VERSION "HNNBNNNYNNNNNNNNNNNNNNNNNNNNNNNNNNNNNNNNNN/4/%%%/4/'%**4NNN///"

NS_ :

BS_:

BU_: Airbag BAP_Tester ICAS1_Gateway ICAS1_KommunikationsServer LE1 LE2 Motor_BEV Schaltbetaetigung

BO_ 958 Motor_14: 8 Motor_BEV
 SG_ Motor_14_CRC : 0|8@1+ (1,0) [0|255] ""  ICAS1_Gateway
 SG_ Motor_14_BZ : 8|4@1+ (1,0) [0|15] ""  ICAS1_Gateway
 SG_ MO_StartStopp_Status : 12|2@1+ (1.0,0.0) [0.0|3] ""  ICAS1_Gateway
 SG_ MO_StartStopp_Wiederstart : 14|1@1+ (1.0,0.0) [0.0|1] ""  ICAS1_Gateway
 SG_ MO_StartStopp_Motorstopp : 15|1@1+ (1.0,0.0) [0.0|1] ""  ICAS1_Gateway
 SG_ MO_Freig_Reku : 16|2@1+ (1.0,0.0) [0.0|3] ""  ICAS1_Gateway
 SG_ MO_Kl_75 : 18|1@1+ (1.0,0.0) [0.0|1] ""  ICAS1_Gateway
 SG_ MO_Kl_50 : 19|1@1+ (1.0,0.0) [0.0|1] ""  ICAS1_Gateway
 SG_ MO_Gangposition : 20|4@1+ (1.0,0.0) [0.0|15] ""  ICAS1_Gateway
 SG_ MO_StartStopp_Fahrerwunsch : 24|2@1+ (1.0,0.0) [0.0|3] ""  ICAS1_Gateway
 SG_ MO_HYB_Fahrbereitschaft : 26|1@1+ (1.0,0.0) [0.0|1] ""  ICAS1_Gateway
 SG_ MO_Ext_E_Fahrt_aktiv : 27|1@1+ (1.0,0.0) [0.0|1] ""  ICAS1_Gateway
 SG_ MO_Fahrer_bremst : 28|1@1+ (1.0,0.0) [0.0|1] ""  Airbag,ICAS1_Gateway
 SG_ MO_QBit_Fahrer_bremst : 29|1@1+ (1.0,0.0) [0.0|1] ""  Airbag,ICAS1_Gateway
 SG_ MO_BLS : 30|1@1+ (1.0,0.0) [0.0|1] ""  Airbag,ICAS1_Gateway
 SG_ MO_Konsistenz_Bremsped : 31|1@1+ (1.0,0.0) [0.0|1] ""  ICAS1_Gateway
 SG_ MO_Timeout_ESP : 32|1@1+ (1.0,0.0) [0.0|1] ""  ICAS1_Gateway
 SG_ MO_Klima_Eingr : 33|2@1+ (1.0,0.0) [0.0|3] ""  ICAS1_Gateway
 SG_ MO_Aussp_Anlass : 35|1@1+ (1.0,0.0) [0.0|1] ""  ICAS1_Gateway
 SG_ MO_Freig_Anlass : 36|1@1+ (1.0,0.0) [0.0|1] ""  ICAS1_Gateway
 SG_ MO_Kuppl_schalter : 37|1@1+ (1.0,0.0) [0.0|1] ""  ICAS1_Gateway
 SG_ MO_Interlock : 38|1@1+ (1.0,0.0) [0.0|1] ""  ICAS1_Gateway
 SG_ MO_Motor_laeuft : 39|1@1+ (1.0,0.0) [0.0|1] ""  ICAS1_Gateway
 SG_ MO_Kickdown : 40|1@1+ (1.0,0.0) [0.0|1] ""  ICAS1_Gateway,ICAS1_KommunikationsServer
 SG_ MO_QBit_KL_75 : 41|1@1+ (1.0,0.0) [0.0|1] ""  ICAS1_Gateway
 SG_ MO_EKlKomLeiRed : 42|2@1+ (1.0,0.0) [0.0|3] ""  ICAS1_Gateway
 SG_ MO_Handshake_STH : 44|1@1+ (1.0,0.0) [0.0|1] ""  ICAS1_Gateway
 SG_ MO_BKV_Unterdruckwarnung : 45|1@1+ (1.0,0.0) [0.0|1] ""  ICAS1_Gateway
 SG_ MO_Freigabe_Segeln : 46|1@1+ (1.0,0.0) [0.0|1] ""  ICAS1_Gateway
 SG_ MO_PTC_Status : 47|3@1+ (1.0,0.0) [0.0|7] ""  ICAS1_Gateway
 SG_ MO_QBit_Gangposition : 50|1@1+ (1.0,0.0) [0.0|1] ""  ICAS1_Gateway
 SG_ MO_Signalquelle_Gangposition : 51|1@1+ (1.0,0.0) [0.0|1] ""  ICAS1_Gateway
 SG_ MO_Remotestart_Betrieb : 52|1@1+ (1.0,0.0) [0.0|1] ""  ICAS1_Gateway
 SG_ MO_Remotestart_moeglich : 53|1@1+ (1.0,0.0) [0.0|1] ""  ICAS1_Gateway
 SG_ MO_FMAus_aktiv : 55|1@1+ (1.0,0.0) [0.0|1] ""  ICAS1_Gateway
 SG_ MO_FMAus_Startvariante : 56|2@1+ (1.0,0.0) [0.0|3] ""  ICAS1_Gateway
 SG_ MO_BMS_NV_Anf_stuetzen : 58|1@1+ (1.0,0.0) [0.0|1] ""  ICAS1_Gateway
 SG_ MO_Zylinderabschaltung : 59|2@1+ (1.0,0.0) [0.0|3] ""  ICAS1_Gateway
 SG_ MO_HYB_VM_aktiv : 61|1@1+ (1.0,0.0) [0.0|1] ""  ICAS1_Gateway
 SG_ MO_StartVorauss_erfuellt : 62|2@1+ (1.0,0.0) [0.0|3] ""  ICAS1_Gateway

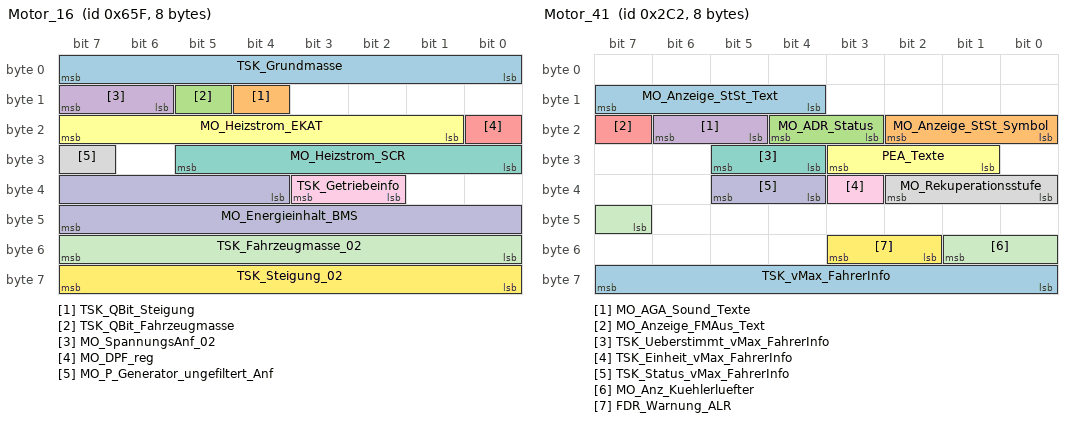
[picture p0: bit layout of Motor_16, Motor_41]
BO_ 1631 Motor_16: 8 Motor_BEV
 SG_ TSK_Grundmasse : 0|8@1+ (32,0) [0|8128] "Unit_KiloGram"  ICAS1_Gateway
 SG_ TSK_QBit_Steigung : 12|1@1+ (1.0,0.0) [0.0|1] ""  ICAS1_Gateway
 SG_ TSK_QBit_Fahrzeugmasse : 13|1@1+ (1.0,0.0) [0.0|1] ""  ICAS1_Gateway
 SG_ MO_SpannungsAnf_02 : 14|2@1+ (1.0,0.0) [0.0|3] ""  ICAS1_Gateway
 SG_ MO_DPF_reg : 16|1@1+ (1.0,0.0) [0.0|1] ""  ICAS1_Gateway
 SG_ MO_Heizstrom_EKAT : 17|7@1+ (1,0) [0|126] "Unit_Amper"  ICAS1_Gateway
 SG_ MO_Heizstrom_SCR : 24|6@1+ (1,0) [0|62] "Unit_Amper"  ICAS1_Gateway
 SG_ MO_P_Generator_ungefiltert_Anf : 31|1@1+ (1.0,0.0) [0.0|1] ""  ICAS1_Gateway
 SG_ TSK_Getriebeinfo : 34|2@1+ (1.0,0.0) [0.0|3] ""  ICAS1_Gateway
 SG_ MO_Energieinhalt_BMS : 36|12@1+ (25,0) [0|102325] "Unit_WattHour"  ICAS1_Gateway
 SG_ TSK_Fahrzeugmasse_02 : 48|8@1+ (32,0) [0|8128] "Unit_KiloGram"  ICAS1_Gateway
 SG_ TSK_Steigung_02 : 56|8@1+ (0.8,-101.6) [-100.8|101.6] "Unit_PerCent"  ICAS1_Gateway

BO_ 1648 Motor_18: 8 Motor_BEV
 SG_ MO_max_Ladedruck : 0|6@1+ (0.1,0) [0.0|6.3] "Unit_Bar"  ICAS1_Gateway
 SG_ MO_ANC_Kennfeld_Anf : 6|2@1+ (1.0,0.0) [0.0|3] ""  ICAS1_Gateway
 SG_ MO_Bremslicht_Reku : 8|1@1+ (1.0,0.0) [0.0|1] ""  ICAS1_Gateway
 SG_ MO_StartStopp_PopUp : 9|2@1+ (1.0,0.0) [0.0|3] ""  ICAS1_Gateway
 SG_ MO1_Sperr_Info_WFS : 11|1@1+ (1.0,0.0) [0.0|1] ""  ICAS1_Gateway
 SG_ MO1_Freigabe_Info_WFS : 12|1@1+ (1.0,0.0) [0.0|1] ""  ICAS1_Gateway
 SG_ MO_EPCL : 13|3@1+ (1.0,0.0) [0.0|7] ""  ICAS1_Gateway,ICAS1_KommunikationsServer
 SG_ MO_Zylabsch_Texte_02 : 16|4@1+ (1.0,0.0) [0.0|15] ""  ICAS1_Gateway
 SG_ MO_Fahrzeugtyp : 20|3@1+ (1.0,0.0) [0.0|7] ""  ICAS1_Gateway,ICAS1_KommunikationsServer
 SG_ MO_NMAX_Schaltanzeige : 23|9@1+ (25,0) [0|12775] "Unit_MinutInver"  ICAS1_Gateway
 SG_ MO_Abstellzeit : 32|8@1+ (8,0) [0|2024] "Unit_Minut"  ICAS1_Gateway
 SG_ MO_Abstellzeit_Status : 40|2@1+ (1.0,0.0) [0.0|3] ""  ICAS1_Gateway
 SG_ MO1_Freigabe_Verfallsinfo_WFS : 42|1@1+ (1.0,0.0) [0.0|1] ""  ICAS1_Gateway
 SG_ MO_Hybrid_StartStopp_LED : 43|2@1+ (1.0,0.0) [0.0|3] ""  ICAS1_Gateway
 SG_ MO_Fehler_Zylabsch : 45|2@1+ (1.0,0.0) [0.0|3] ""  ICAS1_Gateway
 SG_ MO_Anzahl_Abgesch_Zyl : 47|3@1+ (1.0,0.0) [0.0|7] ""  ICAS1_Gateway
 SG_ MO_Zylabsch_Texte : 50|2@1+ (1.0,0.0) [0.0|3] ""  ICAS1_Gateway
 SG_ MO_Ethanol_BS_Texte : 52|3@1+ (1.0,0.0) [0.0|7] ""  ICAS1_Gateway
 SG_ MO_Drehzahl_Warnung : 55|1@1+ (1.0,0.0) [0.0|1] ""  ICAS1_Gateway
 SG_ MO_obere_Drehzahlgrenze : 56|8@1+ (50,0) [50|12750] "Unit_MinutInver"  ICAS1_Gateway

BO_ 967 Motor_26: 8 Motor_BEV
 SG_ MO_Kuehlerluefter_MUX M  : 0|1@1+ (1.0,0.0) [0.0|1] "siema ooo"  ICAS1_Gateway
 SG_ MO_Kuehlerluefter_1 m0  : 1|7@1+ (1,0) [0|100] "Unit_PerCent"  ICAS1_Gateway
 SG_ MO_Kuehlerluefter_2 m1  : 1|7@1+ (1,0) [0|100] "Unit_PerCent"  ICAS1_Gateway
 SG_ MO_EFLEX_Lampe : 8|2@1+ (1.0,0.0) [0.0|3] ""  ICAS1_Gateway
 SG_ MO_KJS_nicht_bereit : 10|1@1+ (1.0,0.0) [0.0|1] ""  ICAS1_Gateway
 SG_ MO_ITM_Warnung_Pumpe : 11|1@1+ (1.0,0.0) [0.0|1] ""  ICAS1_Gateway
 SG_ WIV_Anzeige_aktiv : 12|1@1+ (1.0,0.0) [0.0|1] ""  ICAS1_Gateway
 SG_ WIV_Oelmin_Warn : 13|1@1+ (1.0,0.0) [0.0|1] ""  ICAS1_Gateway
 SG_ WIV_Sensorfehler : 14|1@1+ (1.0,0.0) [0.0|1] ""  ICAS1_Gateway
 SG_ WIV_Schieflage : 15|1@1+ (1.0,0.0) [0.0|1] ""  ICAS1_Gateway
 SG_ WIV_Oelstand : 16|4@1+ (12.5,0) [0.0|100.0] "Unit_PerCent"  ICAS1_Gateway
 SG_ MO_Zustand_HWP : 20|2@1+ (1.0,0.0) [0.0|3] ""  ICAS1_Gateway
 SG_ OLEV_Systemstoerung : 22|1@1+ (1.0,0.0) [0.0|1] ""  ICAS1_Gateway
 SG_ MO_Oelwarnung_max : 23|1@1+ (1.0,0.0) [0.0|1] ""  ICAS1_Gateway
 SG_ WIV_Oelsystem_aktiv : 24|1@1+ (1.0,0.0) [0.0|1] ""  ICAS1_Gateway
 SG_ WIV_nicht_betriebswarm : 25|1@1+ (1.0,0.0) [0.0|1] ""  ICAS1_Gateway
 SG_ WIV_Ueberfuell_Warn : 26|1@1+ (1.0,0.0) [0.0|1] ""  ICAS1_Gateway
 SG_ WIV_laufender_Motor : 27|1@1+ (1.0,0.0) [0.0|1] ""  ICAS1_Gateway
 SG_ MO_E_Warnungen : 28|4@1+ (1.0,0.0) [0.0|15] ""  ICAS1_Gateway
 SG_ MO_Text_Motorstart : 32|4@1+ (1.0,0.0) [0.0|15] ""  ICAS1_Gateway
 SG_ MO_E_Texte : 36|4@1+ (1.0,0.0) [0.0|15] ""  ICAS1_Gateway
 SG_ WIV_Oeldyn_avl : 40|1@1+ (1.0,0.0) [0.0|1] ""  ICAS1_Gateway
 SG_ MO_Text_Partikelfil_Reg : 41|1@1+ (1,0) [0|1] ""  ICAS1_Gateway
 SG_ OLEV_Oelstand_nicht_vorhanden : 42|1@1+ (1.0,0.0) [0.0|1] ""  ICAS1_Gateway
 SG_ WIV_Oelmenge : 43|5@1+ (125,0) [0|3875] "Unit_MilliLiter"  ICAS1_Gateway
 SG_ MO_Systemlampe : 48|1@1+ (1.0,0.0) [0.0|1] ""  ICAS1_Gateway
 SG_ MO_OBD2_Lampe : 49|1@1+ (1.0,0.0) [0.0|1] ""  ICAS1_Gateway
 SG_ MO_Heissleuchte : 50|1@1+ (1.0,0.0) [0.0|1] ""  ICAS1_Gateway
 SG_ MO_Partikel_Lampe : 51|1@1+ (1.0,0.0) [0.0|1] ""  ICAS1_Gateway
 SG_ MO_RedFahrleistung_Lampe : 52|1@1+ (1.0,0.0) [0.0|1] ""  ICAS1_Gateway,ICAS1_KommunikationsServer
 SG_ WIV_Oelstand_nicht_vorhanden : 53|1@1+ (1.0,0.0) [0.0|1] ""  ICAS1_Gateway
 SG_ WIV_nachfuellanzeige_ein : 54|1@1+ (1.0,0.0) [0.0|1] ""  ICAS1_Gateway
 SG_ WIV_Ueberfuell_deaktiv : 55|1@1+ (1.0,0.0) [0.0|1] ""  ICAS1_Gateway
 SG_ WIV_Unterfuell_Warn : 56|1@1+ (1.0,0.0) [0.0|1] ""  ICAS1_Gateway
 SG_ MO_Tankdeckel_Lampe : 57|1@1+ (1.0,0.0) [0.0|1] ""  ICAS1_Gateway
 SG_ MO_Text_Tankdeckelwarn : 58|1@1+ (1.0,0.0) [0.0|1] ""  ICAS1_Gateway
 SG_ MO_Vorglueh_Lampe : 59|1@1+ (1.0,0.0) [0.0|1] ""  ICAS1_Gateway
 SG_ WIV_Oeldr_Warn_Motor : 60|1@1+ (1.0,0.0) [0.0|1] ""  ICAS1_Gateway
 SG_ MO_E_Mode : 61|3@1+ (1.0,0.0) [0.0|7] ""  ICAS1_Gateway

BO_ 706 Motor_41: 8 Motor_BEV
 SG_ MO_Anzeige_StSt_Text : 12|4@1+ (1.0,0.0) [0.0|15] ""  Vector__XXX
 SG_ MO_Anzeige_StSt_Symbol : 16|3@1+ (1.0,0.0) [0.0|7] ""  Vector__XXX
 SG_ MO_ADR_Status : 19|2@1+ (1.0,0.0) [0.0|3] ""  Vector__XXX
 SG_ MO_AGA_Sound_Texte : 21|2@1+ (1.0,0.0) [0.0|3] ""  Vector__XXX
 SG_ MO_Anzeige_FMAus_Text : 23|1@1+ (1.0,0.0) [0.0|1] ""  Vector__XXX
 SG_ PEA_Texte : 25|3@1+ (1.0,0.0) [0.0|7] ""  Vector__XXX
 SG_ TSK_Ueberstimmt_vMax_FahrerInfo : 28|2@1+ (1.0,0.0) [0.0|3] ""  Vector__XXX
 SG_ MO_Rekuperationsstufe : 32|3@1+ (1.0,0.0) [0.0|7] ""  ICAS1_KommunikationsServer
 SG_ TSK_Einheit_vMax_FahrerInfo : 35|1@1+ (1.0,0.0) [0.0|1] ""  ICAS1_KommunikationsServer
 SG_ TSK_Status_vMax_FahrerInfo : 36|2@1+ (1.0,0.0) [0.0|3] ""  ICAS1_KommunikationsServer
 SG_ MO_Anz_Kuehlerluefter : 47|3@1+ (1.0,0.0) [0.0|7] ""  Vector__XXX
 SG_ FDR_Warnung_ALR : 50|2@1+ (1.0,0.0) [0.0|3] ""  ICAS1_KommunikationsServer
 SG_ TSK_vMax_FahrerInfo : 56|8@1+ (1,15) [16|270] ""  ICAS1_KommunikationsServer

BO_ 267 Motor_51: 32 Motor_BEV
 SG_ Motor_51_CRC : 0|8@1+ (1,0) [0|255] ""  ICAS1_Gateway
 SG_ Motor_51_BZ : 8|4@1+ (1,0) [0|15] ""  ICAS1_Gateway
 SG_ MO_Fahrpedalrohwert_01 : 12|8@1+ (0.4,0) [0.0|101.6] "Unit_PerCent"  Airbag,ICAS1_Gateway
 SG_ MO_QBit_Fahrpedalwerte_01 : 20|1@1+ (1.0,0.0) [0.0|1] ""  Airbag,ICAS1_Gateway
 SG_ MO_Fahrpedalgradient : 21|8@1+ (25,0) [0|6350] "Unit_PerCentPerSecon"  ICAS1_Gateway
 SG_ MO_Sig_Fahrpedalgradient : 29|1@1+ (1.0,0.0) [0.0|1] ""  ICAS1_Gateway
 SG_ MO_rel_Saugrohrdruck : 30|6@1+ (18,0) [0|1116] "Unit_MilliBar"  ICAS1_Gateway
 SG_ MO_rel_Saugrohrdruck_gem_err : 36|1@1+ (1.0,0.0) [0.0|1] ""  ICAS1_Gateway
 SG_ MO_Moment_im_Leerlauf : 37|1@1+ (1.0,0.0) [0.0|1] ""  ICAS1_Gateway
 SG_ MO_Schubabschaltung : 38|1@1+ (1.0,0.0) [0.0|1] ""  ICAS1_Gateway
 SG_ MO_Solldrehz_Leerlauf : 40|8@1+ (10,0) [0|2540] "Unit_MinutInver"  ICAS1_Gateway
 SG_ MO_Entkopplung_Sollschlupf : 48|7@1+ (20,0) [0|2480] "Unit_MinutInver"  ICAS1_Gateway
 SG_ MO_temporaere_Fahrerabwesenheit : 55|1@1+ (1.0,0.0) [0.0|1] ""  ICAS1_Gateway
 SG_ TSK_a_Soll_gradientenbegrenzt : 57|7@1+ (0.1,-7.2) [-7.2|5.4] "Unit_MeterPerSeconSquar"  ICAS1_Gateway
 SG_ TSK_Radbremsmom : 76|12@1+ (8,0) [0|32760] "Unit_NewtoMeter"  ICAS1_Gateway
 SG_ TSK_Status : 88|3@1+ (1.0,0.0) [0.0|7] ""  ICAS1_Gateway
 SG_ TSK_v_Begrenzung_aktiv : 91|1@1+ (1.0,0.0) [0.0|1] ""  ICAS1_Gateway
 SG_ TSK_Standby_Anf_ESP : 92|1@1+ (1.0,0.0) [0.0|1] ""  ICAS1_Gateway
 SG_ TSK_Freig_WU : 93|1@1+ (1.0,0.0) [0.0|1] ""  ICAS1_Gateway
 SG_ TSK_Freig_Verzoeg_Anf : 94|1@1+ (1.0,0.0) [0.0|1] ""  ICAS1_Gateway
 SG_ TSK_Limiter_ausgewaehlt : 95|1@1+ (1.0,0.0) [0.0|1] ""  ICAS1_Gateway
 SG_ TSK_Wunsch_Uebersetz : 96|10@1+ (0.0245,0) [0.0245|25.0635] ""  ICAS1_Gateway
 SG_ TSK_Hauptschalter_GRA_ACC : 106|2@1+ (1.0,0.0) [0.0|3] ""  ICAS1_Gateway,ICAS1_KommunikationsServer
 SG_ TSK_SRBM_Anf_ASIL : 108|3@1+ (1.0,0.0) [0.0|7] ""  ICAS1_Gateway
 SG_ TSK_ax_Getriebe_02 : 112|9@1+ (0.024,-2.016) [-2.016|10.224] "Unit_MeterPerSeconSquar"  ICAS1_Gateway
 SG_ TSK_Zwangszusch_ESP : 121|1@1+ (1.0,0.0) [0.0|1] ""  ICAS1_Gateway
 SG_ TSK_zul_Regelabw : 122|6@1+ (0.024,0) [0.000|1.512] "Unit_MeterPerSeconSquar"  ICAS1_Gateway
 SG_ MO_Status_MinDrzEingriff : 235|3@1+ (1.0,0.0) [0.0|7] ""  ICAS1_Gateway
 SG_ MO_Status_MaxDrzEingriff : 238|3@1+ (1.0,0.0) [0.0|7] ""  ICAS1_Gateway
 SG_ MO_Status_MinDrzEingriff_sek : 241|3@1+ (1.0,0.0) [0.0|7] ""  ICAS1_Gateway
 SG_ MO_Status_MaxDrzEingriff_sek : 244|3@1+ (1.0,0.0) [0.0|7] ""  ICAS1_Gateway
 SG_ GRA_KuFu_aktiv : 247|1@1+ (1.0,0.0) [0.0|1] ""  ICAS1_Gateway
 SG_ TSK_SRBM_max_Gradient : 248|7@1+ (50,0) [0|6250] "Unit_NewtoMeterPerSecon"  ICAS1_Gateway
 SG_ LIM_KuFu_aktiv : 255|1@1+ (1.0,0.0) [0.0|1] ""  ICAS1_Gateway

BO_ 330 Motor_52: 32 Motor_BEV
 SG_ MO_Hochschaltdrehz : 21|12@1+ (3,0) [3|12282] "Unit_MinutInver"  Vector__XXX
 SG_ MO_Anzeige_Verbr_Einheit : 33|2@1+ (1.0,0.0) [0.0|3] ""  Vector__XXX
 SG_ MO_Schaltblitz_Anz : 35|7@1+ (1,0) [0|100] "Unit_PerCent"  Vector__XXX
 SG_ MO_Anzeige_Drehmoment : 42|11@1+ (1,0) [0|2045] "Unit_NewtoMeter"  Vector__XXX
 SG_ MO_Anzeige_Leistung : 53|11@1+ (0.6,0) [0.0|1227.0] "Unit_KiloWatt"  Vector__XXX
 SG_ MO_rel_Ladedruck : 64|8@1+ (0.4,0) [0.0|100.0] "Unit_PerCent"  Vector__XXX
 SG_ MO_Istgang : 72|4@1+ (1.0,0.0) [0.0|15] ""  Vector__XXX
 SG_ MO_Sollgang : 76|4@1+ (1.0,0.0) [0.0|15] ""  Vector__XXX
 SG_ MO_Oeldruck : 80|8@1+ (0.04,0) [0.00|10.00] "Unit_Bar"  Vector__XXX
 SG_ MO_Anzeigedrehz : 88|12@1+ (3,0) [0|12282] "Unit_MinutInver"  Vector__XXX
 SG_ MO_Effizienzmodus : 100|1@1+ (1.0,0.0) [0.0|1] ""  Vector__XXX
 SG_ MO_Fehler_Oeldrucksensor : 101|1@1+ (1.0,0.0) [0.0|1] ""  Vector__XXX
 SG_ MO_Schaltempf_verfbar : 102|1@1+ (1.0,0.0) [0.0|1] ""  Vector__XXX
 SG_ MO_Ladedruck : 103|9@1+ (0.01,0) [0.00|5.10] "Unit_Bar"  Vector__XXX
 SG_ MO_KVS : 112|15@1+ (1,0) [0|32767] "Unit_MicroLiter"  Vector__XXX
 SG_ MO_KVS_Ueberlauf : 127|1@1+ (1.0,0.0) [0.0|1] ""  Vector__XXX
 SG_ MO_ePowermeter : 128|8@1+ (0.4,-0.4) [0.0|100.8] "Unit_PerCent"  Vector__XXX
 SG_ MO_ePerformance : 136|8@1+ (0.4,-0.4) [0.0|100.8] "Unit_PerCent"  ICAS1_KommunikationsServer
 SG_ MO_Zust_Antrieb : 144|4@1+ (1.0,0.0) [0.0|15] ""  Vector__XXX
 SG_ MO_Zust_Betriebsstrategie : 148|3@1+ (1.0,0.0) [0.0|7] ""  Vector__XXX
 SG_ Ladezustand_02 : 152|8@1+ (0.5,0) [0.0|100.0] "Unit_PerCent"  ICAS1_Gateway,ICAS1_KommunikationsServer
 SG_ MO_Powermeter_Elm_02 : 168|12@1+ (0.05,-102.4) [-100.00|100.00] "Unit_PerCent"  Vector__XXX
 SG_ MO_Powermeter : 180|12@1+ (1,0) [0|4092] ""  ICAS1_KommunikationsServer

BO_ 512 Motor_53: 32 Motor_BEV
 SG_ TSK_Wunschgeschw : 12|10@1+ (0.32,0) [0.00|326.72] "Unit_KiloMeterPerHour"  ICAS1_Gateway,ICAS1_KommunikationsServer
 SG_ TSK_praediktiver_Hinweis : 22|3@1+ (1.0,0.0) [0.0|7] ""  ICAS1_Gateway
 SG_ TSK_naechstes_Event : 25|6@1+ (1.0,0.0) [0.0|63] ""  ICAS1_Gateway
 SG_ TSK_Fahrzeugstatus_praed_Fkt : 31|3@1+ (1.0,0.0) [0.0|7] ""  ICAS1_Gateway
 SG_ TSK_Texte : 40|5@1+ (1.0,0.0) [0.0|31] ""  ICAS1_Gateway,ICAS1_KommunikationsServer
 SG_ TSK_Akustik : 45|3@1+ (1.0,0.0) [0.0|7] ""  ICAS1_Gateway,ICAS1_KommunikationsServer
 SG_ TSK_Texte_Primaeranz : 48|5@1+ (1.0,0.0) [0.0|31] ""  ICAS1_Gateway,ICAS1_KommunikationsServer
 SG_ TSK_Limiter_Fahrerinfo : 53|2@1+ (1.0,0.0) [0.0|3] ""  ICAS1_Gateway,ICAS1_KommunikationsServer
 SG_ TSK_Limiter_Anzeige : 55|1@1+ (1.0,0.0) [0.0|1] ""  ICAS1_Gateway,ICAS1_KommunikationsServer
 SG_ TSK_Fahrzeugstatus_GRA : 56|1@1+ (1.0,0.0) [0.0|1] ""  ICAS1_Gateway,ICAS1_KommunikationsServer
 SG_ TSK_Fahrzeugstatus_Limiter : 57|1@1+ (1.0,0.0) [0.0|1] ""  ICAS1_Gateway,ICAS1_KommunikationsServer
 SG_ MO_Motorlaufwarnung : 58|1@1+ (1.0,0.0) [0.0|1] ""  ICAS1_Gateway
 SG_ TSK_naechstes_Event_Einheit : 60|1@1+ (1.0,0.0) [0.0|1] ""  ICAS1_Gateway
 SG_ TSK_Status_Anzeige : 61|3@1+ (1.0,0.0) [0.0|7] ""  ICAS1_Gateway,ICAS1_KommunikationsServer
 SG_ MO_Sperrung_FahrPr_BZS : 64|8@1+ (1.0,0.0) [0.0|255] ""  ICAS1_Gateway
 SG_ MO_Rampenzeit_Generator_Anf : 72|4@1+ (1.0,0.0) [0.0|15] ""  ICAS1_Gateway
 SG_ MO_Prio_MAX_Wunschdrehzahl : 76|1@1+ (1.0,0.0) [0.0|1] ""  ICAS1_Gateway
 SG_ MO_Prio_MIN_Wunschdrehzahl : 77|1@1+ (1.0,0.0) [0.0|1] ""  ICAS1_Gateway
 SG_ MO_Luftpfad_aktiv : 78|1@1+ (1.0,0.0) [0.0|1] ""  ICAS1_Gateway
 SG_ MO_v_Begrenz_Aktivierbar : 79|1@1+ (1.0,0.0) [0.0|1] ""  ICAS1_Gateway
 SG_ MO_Drehzahlbeeinflussung : 80|8@1+ (0.39,0) [0.00|99.45] "Unit_PerCent"  ICAS1_Gateway
 SG_ MO_MIN_Wunschdrehzahl : 88|8@1+ (25,0) [0|6350] "Unit_MinutInver"  ICAS1_Gateway
 SG_ MO_MAX_Wunschdrehzahl : 96|9@1+ (25,0) [0|12750] "Unit_MinutInver"  ICAS1_Gateway
 SG_ MO_Charisma_FahrPr : 105|4@1+ (1.0,0.0) [0.0|15] ""  ICAS1_Gateway
 SG_ MO_Charisma_Status : 109|2@1+ (1.0,0.0) [0.0|3] ""  ICAS1_Gateway
 SG_ MO_StSt_Charisma_FahrPr : 111|4@1+ (1.0,0.0) [0.0|15] ""  ICAS1_Gateway
 SG_ MO_StSt_Charisma_Status : 115|2@1+ (1.0,0.0) [0.0|3] ""  ICAS1_Gateway
 SG_ MO_BZS_Charisma_FahrPr : 117|4@1+ (1.0,0.0) [0.0|15] ""  ICAS1_Gateway
 SG_ MO_BZS_Charisma_Status : 121|2@1+ (1.0,0.0) [0.0|3] ""  ICAS1_Gateway
 SG_ MO_NGS_Position : 123|1@1+ (1.0,0.0) [0.0|1] ""  ICAS1_Gateway
 SG_ MO_NGS_Status : 124|2@1+ (1.0,0.0) [0.0|3] ""  ICAS1_Gateway
 SG_ MO_v_Begrenzung_Niveau : 126|2@1+ (1.0,0.0) [0.0|3] ""  ICAS1_Gateway
 SG_ MO_Anzeige_Rekuperation : 128|8@1+ (0.5,-0.5) [0.0|100.0] "Unit_PerCent"  ICAS1_Gateway
 SG_ PEA_Fortschrittsanzeige : 136|7@1+ (1,0) [0|100] "Unit_PerCent"  ICAS1_Gateway
 SG_ MO_Anzeige_Fahrbereitschaft : 143|1@1+ (1.0,0.0) [0.0|1] ""  ICAS1_Gateway,ICAS1_KommunikationsServer
 SG_ MO_Boost_verfuegbar : 144|8@1+ (0.4,-0.4) [0.0|100.4] "Unit_PerCent"  ICAS1_Gateway
 SG_ MO_Overboost : 152|1@1+ (1.0,0.0) [0.0|1] ""  ICAS1_Gateway
 SG_ MO_Boost_aktiv : 153|1@1+ (1.0,0.0) [0.0|1] ""  ICAS1_Gateway
 SG_ MO_Anzeige_Betriebsmodus : 154|4@1+ (1.0,0.0) [0.0|15] ""  ICAS1_Gateway
 SG_ PEA_Hinweis : 158|2@1+ (1.0,0.0) [0.0|3] ""  ICAS1_Gateway
 SG_ PEA_Ereignisanzeige : 160|5@1+ (1.0,0.0) [0.0|31] ""  ICAS1_Gateway
 SG_ PEA_Ereignisanzeige_temporaer : 165|1@1+ (1.0,0.0) [0.0|1] ""  ICAS1_Gateway
 SG_ PEA_Abschalttexte : 166|2@1+ (1.0,0.0) [0.0|3] ""  ICAS1_Gateway
 SG_ PEA_Zielgeschw_Einheit : 168|1@1+ (1.0,0.0) [0.0|1] ""  ICAS1_Gateway
 SG_ PEA_Zielgeschw : 169|5@1+ (1.0,0.0) [0.0|31] ""  ICAS1_Gateway
 SG_ MO_Antriebsstrang_Warnung_HS : 174|2@1+ (1.0,0.0) [0.0|3] ""  ICAS1_Gateway
 SG_ MO_Anzeige_Verbrauch_oE : 176|16@1+ (0.005,0) [0.000|327.675] "Unit_None"  ICAS1_Gateway

BO_ 332 Motor_54: 32 Motor_BEV
 SG_ MO_Anforderung_HMS : 12|3@1+ (1.0,0.0) [0.0|7] ""  ICAS1_Gateway
 SG_ FoD_DTC_TSK_GRA : 15|1@1+ (1.0,0.0) [0.0|1] ""  ICAS1_Gateway
 SG_ TSK_vMax_aktuell : 16|8@1+ (1,0) [0|253] "Unit_KiloMeterPerHour"  ICAS1_Gateway
 SG_ TSK_Status_EA : 32|3@1+ (1.0,0.0) [0.0|7] ""  ICAS1_Gateway
 SG_ FoD_DTC_TSK_ACC : 35|1@1+ (1.0,0.0) [0.0|1] ""  ICAS1_Gateway
 SG_ TSK_ACC_FoD_Status : 36|2@1+ (1.0,0.0) [0.0|3] ""  ICAS1_Gateway
 SG_ TSK_GRA_FoD_Status : 38|2@1+ (1.0,0.0) [0.0|3] ""  ICAS1_Gateway
 SG_ TSK_vMax_Fahrerassistenz : 40|9@1+ (1,0) [0|510] ""  ICAS1_Gateway
 SG_ TSK_Einheit_vMax_Fahrerassistenz : 49|1@1+ (1.0,0.0) [0.0|1] ""  ICAS1_Gateway
 SG_ TSK_Status_PLA : 50|3@1+ (1.0,0.0) [0.0|7] ""  ICAS1_Gateway
 SG_ TSK_aktives_System : 53|3@1+ (1.0,0.0) [0.0|7] ""  ICAS1_Gateway
 SG_ TSK_erhoehter_Fahrwiderstand : 56|1@1+ (1.0,0.0) [0.0|1] ""  ICAS1_Gateway
 SG_ TSK_Anf_Antriebsmoment : 57|1@1+ (1.0,0.0) [0.0|1] ""  ICAS1_Gateway
 SG_ TSK_Status_ARA : 58|3@1+ (1.0,0.0) [0.0|7] ""  ICAS1_Gateway
 SG_ TSK_Status_IPA : 61|3@1+ (1.0,0.0) [0.0|7] ""  ICAS1_Gateway
 SG_ MO_Fahrbereitschaft : 76|2@1+ (1.0,0.0) [0.0|3] ""  ICAS1_Gateway,LE1,LE2
 SG_ MO_Freilauf_Info : 78|2@1+ (1.0,0.0) [0.0|3] ""  ICAS1_Gateway
 SG_ MO_Krit_Heckobjekt : 81|3@1+ (1.0,0.0) [0.0|7] ""  ICAS1_Gateway
 SG_ MO_NGS_Gangpos : 84|3@1+ (1.0,0.0) [0.0|7] ""  ICAS1_Gateway
 SG_ MO_Freilauf_Status : 87|3@1+ (1.0,0.0) [0.0|7] ""  ICAS1_Gateway
 SG_ MO_EBoost_verf_praed : 90|2@1+ (1.0,0.0) [0.0|3] ""  ICAS1_Gateway
 SG_ MO_Heckspoiler_Anf : 92|1@1+ (1.0,0.0) [0.0|1] ""  ICAS1_Gateway
 SG_ MO_eLaunch_verf : 93|2@1+ (1.0,0.0) [0.0|3] ""  ICAS1_Gateway
 SG_ MO_Positionierung_aktiv : 95|1@1+ (1.0,0.0) [0.0|1] ""  ICAS1_Gateway
 SG_ MO_Freilauf_Typ : 98|2@1+ (1.0,0.0) [0.0|3] ""  ICAS1_Gateway
 SG_ MO_Startwunsch : 100|1@1+ (1.0,0.0) [0.0|1] ""  ICAS1_Gateway
 SG_ OBD_Calc_Load_Val : 128|8@1+ (0.39215686274509803,0) [0E-17|99.99999999999999765] "Unit_PerCent"  ICAS1_Gateway,LE1,LE2
 SG_ OBD_Eng_Cool_Temp : 136|8@1+ (1,-40) [-40|215] "Unit_DegreCelsi"  ICAS1_Gateway,LE1,LE2
 SG_ OBD_Abs_Throttle_Pos : 144|8@1+ (0.39215686274509803,0) [0E-17|99.99999999999999765] "Unit_PerCent"  ICAS1_Gateway,LE1,LE2
 SG_ OBD_Abs_Load_Val : 152|16@1+ (0.39215686274509803,0) [0E-17|25699.99999999999939605] "Unit_PerCent"  ICAS1_Gateway,LE1,LE2
 SG_ OBD_Abs_Pedal_Pos : 168|8@1+ (0.39215686274509803,0) [0E-17|99.99999999999999765] "Unit_PerCent"  ICAS1_Gateway,LE1,LE2
 SG_ MO_Servicemodus : 176|4@1+ (1.0,0.0) [0.0|15] ""  ICAS1_Gateway,LE1,LE2
 SG_ OBD_ClearMem_Inhibit : 183|1@1+ (1.0,0.0) [0.0|1] ""  ICAS1_Gateway,LE1,LE2
 SG_ OBD_Sperrung_Kaltstart_Denom : 184|1@1+ (1.0,0.0) [0.0|1] ""  ICAS1_Gateway,LE1,LE2
 SG_ MO_QBit_Aussen_Temp : 185|1@1+ (1.0,0.0) [0.0|1] ""  ICAS1_Gateway
 SG_ OBD_Sperrung_IUMPR : 186|1@1+ (1.0,0.0) [0.0|1] ""  ICAS1_Gateway,LE1,LE2
 SG_ OBD_Kaltstart_Denominator : 187|1@1+ (1.0,0.0) [0.0|1] ""  ICAS1_Gateway,LE1,LE2
 SG_ OBD_Minimum_Trip : 188|1@1+ (1.0,0.0) [0.0|1] ""  ICAS1_Gateway,LE1,LE2
 SG_ OBD_Driving_Cycle : 189|1@1+ (1.0,0.0) [0.0|1] ""  ICAS1_Gateway,LE1,LE2
 SG_ OBD_Warm_Up_Cycle : 190|1@1+ (1.0,0.0) [0.0|1] ""  ICAS1_Gateway,LE1,LE2
 SG_ OBD_Normed_Trip : 191|1@1+ (1.0,0.0) [0.0|1] ""  ICAS1_Gateway,LE1,LE2
 SG_ OBD_Aussen_Temp_gef : 248|8@1+ (1,-40) [-40|213] "Unit_DegreCelsi"  ICAS1_Gateway

BO_ 246 Motor_55: 32 Motor_BEV
 SG_ Motor_55_CRC : 0|8@1+ (1,0) [0|255] ""  ICAS1_Gateway
 SG_ Motor_55_BZ : 8|4@1+ (1,0) [0|15] ""  ICAS1_Gateway
 SG_ TS_Faktor_Radmomente : 12|2@1+ (1.0,0.0) [0.0|3] ""  ICAS1_Gateway
 SG_ TS_Status_MomRad_Ist : 14|2@1+ (1.0,0.0) [0.0|3] ""  ICAS1_Gateway
 SG_ TS_MomRad_verfuegb_maxReku_Summe : 16|12@1+ (3,-12279) [-12279|0] ""  ICAS1_Gateway
 SG_ TS_MomRad_Ist : 28|13@1+ (3,-12279) [-12279|12279] "Unit_None"  ICAS1_Gateway
 SG_ TS_MomRad_Soll_Summe : 41|13@1+ (3,-12279) [-12279|12279] "Unit_None"  ICAS1_Gateway
 SG_ TS_MomRad_Wunsch : 54|13@1+ (3,-12279) [-12279|12279] "Unit_None"  ICAS1_Gateway
 SG_ TS_MomRad_Wunsch_sek : 67|13@1+ (3,-12279) [-12279|12279] "Unit_None"  ICAS1_Gateway
 SG_ TS_MomRad_verfuegb_max : 80|12@1+ (3,0) [0|12279] "Unit_None"  ICAS1_Gateway
 SG_ TS_MomRad_verfuegb_max_sek : 92|12@1+ (3,0) [0|12279] "Unit_None"  ICAS1_Gateway
 SG_ TS_MomRad_verfuegb_maxReku : 104|12@1+ (3,-12279) [-12279|0] "Unit_None"  ICAS1_Gateway
 SG_ TS_MomRad_verfuegb_maxReku_sek : 116|12@1+ (3,-12279) [-12279|0] "Unit_None"  ICAS1_Gateway
 SG_ TS_MomRad_Ist_sek : 128|13@1+ (3,-12279) [-12279|12279] "Unit_None"  ICAS1_Gateway
 SG_ TS_Allrad_Anteil_sek : 141|9@1+ (0.2,0) [0.0|100.0] "Unit_PerCent"  ICAS1_Gateway
 SG_ FDR_Allrad_Anteil_max_sek : 150|9@1+ (0.2,0) [0.0|100.0] "Unit_PerCent"  ICAS1_Gateway
 SG_ FDR_Allrad_Anteil_min_sek : 159|9@1+ (0.2,0) [0.0|100.0] "Unit_PerCent"  ICAS1_Gateway
 SG_ FDR_MomRad_Eingriff : 168|13@1+ (3,-12279) [-12279|12279] "Unit_NewtoMeter"  ICAS1_Gateway
 SG_ FDR_Status_Eingriff : 181|1@1+ (1.0,0.0) [0.0|1] ""  ICAS1_Gateway
 SG_ FDR_MomRad_Eingriff_sek : 182|13@1+ (3,-12279) [-12279|12279] "Unit_NewtoMeter"  ICAS1_Gateway
 SG_ FDR_Status_Eingriff_sek : 195|1@1+ (1.0,0.0) [0.0|1] ""  ICAS1_Gateway

BO_ 190 Motor_56: 48 Motor_BEV
 SG_ Motor_56_CRC : 0|8@1+ (1,0) [0|255] ""  ICAS1_Gateway,LE1,LE2
 SG_ Motor_56_BZ : 8|4@1+ (1,0) [0|15] ""  ICAS1_Gateway,LE1,LE2
 SG_ MO_EM1_MinDrehzahl : 12|14@1+ (2,-10000) [-10000|22764] "Unit_MinutInver"  ICAS1_Gateway,LE1
 SG_ MO_EM1_MaxDrehzahl : 26|14@1+ (2,-10000) [-10000|22764] "Unit_MinutInver"  ICAS1_Gateway,LE1
 SG_ MO_EM1_DynLimit_AR : 40|8@1+ (1,0) [0|254] "Unit_NewtoMeter"  ICAS1_Gateway,LE1
 SG_ MO_EM1_Periode_AR : 48|8@1+ (0.001953125,0) [0E-9|0.496093750] "Unit_Secon"  ICAS1_Gateway,LE1
 SG_ MO_EM1_SollMoment : 56|12@1+ (0.5,-1023) [-1023.0|1023.5] "Unit_NewtoMeter"  ICAS1_Gateway,LE1
 SG_ MO_EM1_Sollmodus : 68|4@1+ (1.0,0.0) [0.0|15] ""  ICAS1_Gateway,LE1
 SG_ MO_EM1_Min_Leistung : 72|14@1+ (100,-819000) [-819000|819100] "Unit_Watt"  ICAS1_Gateway,LE1
 SG_ MO_EM1_Max_Leistung : 86|14@1+ (100,-819000) [-819000|819100] "Unit_Watt"  ICAS1_Gateway,LE1
 SG_ MO_EM1_Min_Strom_Lim : 100|13@1+ (0.5,-2047) [-2047.0|2047.5] "Unit_Amper"  ICAS1_Gateway,LE1
 SG_ MO_EM1_Max_Strom_Lim : 113|13@1+ (0.5,-2047) [-2047.0|2047.5] "Unit_Amper"  ICAS1_Gateway,LE1
 SG_ MO_EM1_AR_Anf : 126|3@1+ (1.0,0.0) [0.0|7] ""  ICAS1_Gateway,LE1
 SG_ MO_EM1_Kp_AR : 129|9@1+ (0.00390625,0) [0E-8|1.99218750] "Unit_NewtoMeterPerRPM"  ICAS1_Gateway,LE1
 SG_ MO_EM1_SollSpannung : 138|12@1+ (0.5,0) [0.0|2047.0] "Unit_Volt"  ICAS1_Gateway,LE1
 SG_ MO_EM2_MinDrehzahl : 156|14@1+ (2,-10000) [-10000|22764] "Unit_MinutInver"  ICAS1_Gateway,LE2
 SG_ MO_EM2_MaxDrehzahl : 170|14@1+ (2,-10000) [-10000|22764] "Unit_MinutInver"  ICAS1_Gateway,LE2
 SG_ MO_EM2_DynLimit_AR : 184|8@1+ (1,0) [0|254] "Unit_NewtoMeter"  ICAS1_Gateway,LE2
 SG_ MO_EM2_Periode_AR : 192|8@1+ (0.001953125,0) [0E-9|0.496093750] "Unit_Secon"  ICAS1_Gateway,LE2
 SG_ MO_EM2_SollMoment : 200|12@1+ (0.5,-1023) [-1023.0|1023.5] "Unit_NewtoMeter"  ICAS1_Gateway,LE2
 SG_ MO_EM2_Sollmodus : 212|4@1+ (1.0,0.0) [0.0|15] ""  ICAS1_Gateway,LE2
 SG_ MO_EM2_Min_Leistung : 216|14@1+ (100,-819000) [-819000|819100] "Unit_Watt"  ICAS1_Gateway,LE2
 SG_ MO_EM2_Max_Leistung : 230|14@1+ (100,-819000) [-819000|819100] "Unit_Watt"  ICAS1_Gateway,LE2
 SG_ MO_EM2_Min_Strom_Lim : 244|13@1+ (0.5,-2047) [-2047.0|2047.5] "Unit_Amper"  ICAS1_Gateway,LE2
 SG_ MO_EM2_Max_Strom_Lim : 257|13@1+ (0.5,-2047) [-2047.0|2047.5] "Unit_Amper"  ICAS1_Gateway,LE2
 SG_ MO_EM2_AR_Anf : 270|3@1+ (1.0,0.0) [0.0|7] ""  ICAS1_Gateway,LE2
 SG_ MO_EM2_SollSpannung : 282|12@1+ (0.5,0) [0.0|2047.0] "Unit_Volt"  ICAS1_Gateway,LE2
 SG_ MO_DC_Max_Strom_HV : 296|8@1+ (0.2,0) [0.0|50.8] "Unit_Amper"  ICAS1_Gateway
 SG_ MO_DC_SollSpannung_HV : 304|8@1+ (2,0) [0|508] "Unit_Volt"  ICAS1_Gateway
 SG_ MO_EM1_Max_Moment : 312|12@1+ (0.5,-1023) [-1023.0|1023.5] "Unit_NewtoMeter"  ICAS1_Gateway,LE1
 SG_ MO_EM1_Min_Moment : 324|12@1+ (0.5,-1023) [-1023.0|1023.5] "Unit_NewtoMeter"  ICAS1_Gateway,LE1
 SG_ MO_EM2_Max_Moment : 336|12@1+ (0.5,-1023) [-1023.0|1023.5] "Unit_NewtoMeter"  ICAS1_Gateway,LE2
 SG_ MO_EM2_Min_Moment : 348|12@1+ (0.5,-1023) [-1023.0|1023.5] "Unit_NewtoMeter"  ICAS1_Gateway,LE2

BO_ 2463978666 Motor_57: 32 Motor_BEV
 SG_ MO_EM1_Min_Spannung_Lim : 12|10@1+ (1,0) [0|1021] "Unit_Volt"  ICAS1_Gateway,LE1
 SG_ MO_EM1_Max_Spannung_Lim : 22|10@1+ (1,0) [0|1021] "Unit_Volt"  ICAS1_Gateway,LE1
 SG_ MO_EM1_Min_Leistung_Gesamt : 32|13@1+ (200,-819000) [-819000|818800] "Unit_Watt"  ICAS1_Gateway,LE1
 SG_ MO_EM1_Max_Leistung_Gesamt : 45|13@1+ (200,-819000) [-819000|818800] "Unit_Watt"  ICAS1_Gateway,LE1
 SG_ MO_EM2_Min_Leistung_Gesamt : 58|13@1+ (200,-819000) [-819000|818800] "Unit_Watt"  ICAS1_Gateway,LE2
 SG_ MO_EM2_Max_Leistung_Gesamt : 71|13@1+ (200,-819000) [-819000|818800] "Unit_Watt"  ICAS1_Gateway,LE2
 SG_ MO_EM2_Min_Spannung_Lim : 84|10@1+ (1,0) [0|1021] "Unit_Volt"  ICAS1_Gateway,LE2
 SG_ MO_EM2_Max_Spannung_Lim : 94|10@1+ (1,0) [0|1021] "Unit_Volt"  ICAS1_Gateway,LE2
 SG_ MO_EM1_Generator_Leistung : 104|8@1+ (100,0) [0|25300] "Unit_Watt"  ICAS1_Gateway,LE1
 SG_ MO_Verbrauch_EM_Ges : 120|15@1+ (10,0) [0|327670] "Unit_WattSecond"  ICAS1_Gateway,ICAS1_KommunikationsServer
 SG_ MO_Verbrauch_EM_Ges_Ueberlauf : 135|1@1+ (1.0,0.0) [0.0|1] ""  ICAS1_Gateway,ICAS1_KommunikationsServer
 SG_ MO_Rekuperation_Ges_EM : 136|15@1+ (10,0) [0|327670] "Unit_WattSecond"  ICAS1_Gateway,ICAS1_KommunikationsServer
 SG_ MO_Rekuperation_EM_Ges_Ueberlauf : 151|1@1+ (1.0,0.0) [0.0|1] ""  ICAS1_Gateway,ICAS1_KommunikationsServer
 SG_ MO_Drehzahl_EM : 152|13@1+ (8,-32768) [-32768|32744] "Unit_RevPerMinute"  ICAS1_Gateway
 SG_ MO_Uebersetzung_EM : 165|10@1+ (0.03125,0) [0.03125|31.90625] ""  ICAS1_Gateway
 SG_ MO_Drehzahl_EM_sek : 175|13@1+ (8,-32768) [-32768|32744] "Unit_RevPerMinute"  ICAS1_Gateway
 SG_ MO_Uebersetzung_EM_sek : 188|10@1+ (0.03125,0) [0.03125|31.90625] ""  ICAS1_Gateway

CM_ BO_ 1648 "Kombischnittstelle";
CM_ BO_ 967 "MQB - vorher Motor_06 / Umbenennung wg. ID-Wechsel";

CM_ SG_ 958 MO_Aussp_Anlass "Das Signal zeigt an, ob die Wiederholstartsperre aktiv ist. D. h. eine Ansteuerung des Anlassers wird auch bei erfüllten Startvoraussetzungen (HS: Interlock betätigt bzw. AT: P/N eingelegt und Bremse betätigt) nicht erfolgen.";
CM_ SG_ 958 MO_BKV_Unterdruckwarnung "Über die Unterdruckwarnung signalisiert das MSG dem ESP, dass kein ausreichender Unterdruck für den BKV zur Verfügung gestellt werden kann.";
CM_ SG_ 958 MO_BLS "Ungefiltertes Rohsignal des Bremslichtschalters, nur wenn HW-Eingang bestückt und ausgewertet wird. Bei Motoren ohne genutzten HW-Eingang wird kein Ersatzwert (bspw. SW-Signal über CAN) ausgegeben!
Bei AUDI muss das Signal wg. Bremslichtfunktion immer be";
CM_ SG_ 958 MO_BMS_NV_Anf_stuetzen "Garantierte Unterstützung des Zusatzspeichers ist erforderlich. Zusatzspeicher muss an das Versorgungsnezt angebunden werden. ";
CM_ SG_ 958 MO_EKlKomLeiRed "Anforderung an die Klimasteuerung, die Leistungsaufnahme des E-Kompressors bei schlechtem SOC und in bestimmten Fahrsituationen zu begrenzen. (Das bereits bestehende Signal 'Klimakompressor aus' als stets umzusetzende Anforderung bleibt unverändert besteh";
CM_ SG_ 958 MO_Ext_E_Fahrt_aktiv "Funktionsrückmeldung zum erw. E-Fahr-Betrieb über Lampe/LED im E-Mode-Taster";
CM_ SG_ 958 MO_Fahrer_bremst "Redundante Bremsinformation vom Motor.

MLB:
AUDI D4: Zykluszeit: 10ms (siehe Zykluszeit schnell/Cycletime Fast)
Im AUDI B8 wird in diesem Bit der Wert der ESP-CAN-Information 'ESP_Fahrer_bremst' ausgegeben.

Achtung:
Reduktion der Zykluszeit Motor";
CM_ SG_ 958 MO_FMAus_aktiv "Das Signal gibt Rückmeldung ob Freilauf Motor aus aktiv ist. Beleibt auch 0km/h (unterhalb der StartStopp Schwelle) weiterhin aktiv.";
CM_ SG_ 958 MO_FMAus_Startvariante "Startvariante beim Motorstart aus der Freilauf-Motor-AUS Phase";
CM_ SG_ 958 MO_Freig_Anlass "Bit wird gesetzt, wenn der Motor beim Automatikstart gestartet werden darf (Motorstillstand, Emissionsmaßnahmen sind erfüllt).";
CM_ SG_ 958 MO_Freig_Reku "Empfehlung des Motor-SG's zur Spannungsabsenkung/-anhebung für den Rekuperationsbetrieb";
CM_ SG_ 958 MO_Freigabe_Segeln "Freigabebit des Segelbetriebs im Getriebe. Bedingt durch bestimmte Diagnosen und Adaptionen des MSGs, die nur im Schub möglich sind, darf nicht jede Schubphase für einen Segelbetrieb genutzt werden. Eine Freigabe bleibt auch außerhalb einer Schubphase bes";
CM_ SG_ 958 MO_Gangposition "MLB:
Stellung des Wählhebels in der Schaltgasse des Handschaltgetriebes.
MLBevo: 
Ausweitung der Bedienung auch auf Automatikgetriebe;
Routing des Signals GE_Fahrstufe: 
1. Position_R (dez. 6) auf MO_Gangposition: Gang_R (dez. 13) wegen Entfall Signa";
CM_ SG_ 958 MO_Handshake_STH "Es gilt: Signalspec MO_Handshake v1.0

Handshake zwischen MSG und STH. Wenn das MSG die EKP aufgrund einer STH-Anforderung ansteuert und kein Fehlereintrag bzgl. EKP/KPE/NDR vorliegt, wird das Bit gesetzt.";
CM_ SG_ 958 MO_HYB_Fahrbereitschaft "Signal steuert u.a. in der Lenkhilfe zusammen mit weiteren Informationen den Modewechsel in den 'Drivemode'
Grüne Anzeige im Kombiinstrument zur Signalisierung der Bereitschaft des Hybridsystems.";
CM_ SG_ 958 MO_HYB_VM_aktiv "0 = VMotor wird nicht aktiv gehalten (nVM < n_min und keine LL-Regelung aktiv)
1 = VMotor aktiv (ab der ersten Einspritzung; gilt auch für Schubbetrieb, wenn VMotor spätestens durch LLRegelung befeuert würde)
Verwendet zur Bestimmung des Ist-Zustandes";
CM_ SG_ 958 MO_Interlock "Das Motorsteuergerät gibt die Information aus, ab wann der Kupplungsschalter durch das Motorsteuergerät als getreten gesehen wird.
Bei Systemen für Start Stopp muss das Interlocksignal für einen Start durch das MSG generiert werden, sobald der Schalthebe";
CM_ SG_ 958 MO_Kickdown "Es gilt: Signalspec MO_Kickdown v1.0";
CM_ SG_ 958 MO_Kl_50 "Klemme 50: Startausführung durch Ritzelstarter

MLB: nicht von allen Motoren gesendet
MQB/MLBevo: gesendet von allen Motoren";
CM_ SG_ 958 MO_Kl_75 "Klemme X
";
CM_ SG_ 958 MO_Klima_Eingr "Eingriffe des Motor bei der Klima";
CM_ SG_ 958 MO_Konsistenz_Bremsped "MLB:

AUDI D4: Zykluszeit: 10ms (siehe Zykluszeit schnell/Cycletime Fast)
Siehe 'Funktionsspezifikation Bremslichtinfo B8'

Achtung:
Reduktion der Zykluszeit Motor_03 auf 10ms geplant.
Projektabhängig soll künftig mit 10ms gesendet werden.
Empfäng";
CM_ SG_ 958 MO_Kuppl_schalter "MLB:
Das Motorsteuergerät gibt die Information aus, ab wann der Kupplungsschalter durch das Motorsteuergerät als getreten gesehen wird
0x0: Schalter sagt betätigt (Ausgekuppelt)
0x1: Schalter sagt nicht betätigt (Eingekuppelt)

MQB:
Nur Handschalter";
CM_ SG_ 958 MO_Motor_laeuft "Das Motorsteuergerät gibt die Information aus, ab wann der Motor verbrennungsbedingt autark läuft und durch zuschaltbare Nebenaggregate mechanisch belastbar ist (z.B. durch Generator, Klimakompressor, etc.).

Die 'Motor läuft' Information wird ausgegebe";
CM_ SG_ 958 MO_PTC_Status "Status-Rückmeldung vom MSG zum aktuellen PTC-Status (stufiges PTC, Relais am MSG). Bei Ansteuerung eines stufigen PTC durch ein anderes SG beschreibt das Signal die vom MSG freigegebene PTC-Stufe.";
CM_ SG_ 958 MO_QBit_Fahrer_bremst "MLB:
AUDI D4: Zykluszeit: 10ms (siehe Zykluszeit schnell/Cycletime Fast)

Achtung:
Reduktion der Zykluszeit Motor_03 auf 10ms geplant.
Projektabhängig soll künftig mit 10ms gesendet werden.
Empfänger die in weiteren Konzern-Projekten eingesetzt werd";
CM_ SG_ 958 MO_QBit_Gangposition "Qualitätsbit zum Signal MO_Gangposition";
CM_ SG_ 958 MO_QBit_KL_75 "Q - Bit für das KL 75 Signal zur Vermeidung der fehlerhaften Erkennung von Motorstarts. 
Wird auf 1 gesetzt, solange das Motorsteuergerät KL15 = AUS erkannt hat.";
CM_ SG_ 958 MO_Remotestart_Betrieb "Das MSG ist für den Remotestart-Betrieb bereit. Nach Empfang der Motorstartanforderung für RSt-Betrieb durch BCM wird der Fahrzeugmotor gestartet und solange der Motor läuft, bleibt dieses Bit aktiv. Dieses Signal ist nur zur Verwendung durch das BCM zur ";
CM_ SG_ 958 MO_Remotestart_moeglich "Wenn Bit gesetzt, würde das MSG bei entsprechender Anforderung durch das BCM den Remotestartbetrieb einleiten, d.h. das MSG ist remotestartfähig und es liegen aktuell keine relevanten Fehler oder andere Abbruchgründe vor.";
CM_ SG_ 958 MO_Signalquelle_Gangposition "Signalquelle des Signals MO_Gangposition
0: Signalquelle Gangpositionssensor
1: Signalquelle Modellwert (v/n)";
CM_ SG_ 958 MO_StartStopp_Fahrerwunsch "Fahreraktivität Start/Stop";
CM_ SG_ 958 MO_StartStopp_Motorstopp "Motor-Stopp durch Start/Stopp-Koordinator
HYBRID:
Wenn MO_Hybridfahrzeug = 1 gilt:
Verbrennungsmotor durch Hybrid-Koordinator im MSG ausgeschaltet. 
Die definierten Start/Stopp-Signale beziehen sich nur auf den Verbrennungsmotor!";
CM_ SG_ 958 MO_StartStopp_Status "Aktivitätsstatus Start/Stopp-Koordinator
HYBRID:
Wenn MO_Hybridfahrzeug = 1 gilt:
Signal bezieht sich nur auf den Verbrennungsmotor, nicht auf den Hybridantrieb
";
CM_ SG_ 958 MO_StartStopp_Wiederstart "Motorwiederstart durch Start/Stopp-Koordinator
HYBRID:
Wenn MO_Hybridfahrzeug =1 gilt:
Warnung vor Spannungseinbruch beim Zustart des Verbrennungsmotors. 
-nicht relevant, da derzeit kein Start über 12V-Starter geplant-
Dieses Signal wird nur vom Hyb";
CM_ SG_ 958 MO_StartVorauss_erfuellt "Dient der Fallunterscheidung bei ZAT-Betätigung im Zustand 'KL15 ein' (bei nicht gesetztem Signal folgt KL15 aus, bei gesetztem Signal folgt setzen KL50-Anf.)

0: Signal nicht bedient 
1: Voraussetzungen zur Antriebsstrangaktivierung / Startvoraussetzu";
CM_ SG_ 958 MO_Timeout_ESP "500 ms Timeout auf Bremsen-Botschaft ist >= 1 mal aufgelaufen, Löschen des Bits nach Neustart (KL15).

MLB:
AUDI D4: Zykluszeit: 10ms (siehe Zykluszeit schnell/Cycletime Fast)

Achtung:
Reduktion der Zykluszeit Motor_03 auf 10ms geplant.
Projektabh";
CM_ SG_ 958 MO_Zylinderabschaltung "Status Zylinderabschaltung Motor";
CM_ SG_ 958 Motor_14_CRC "Ab MQB und MLBevo:
'Berechnung siehe Lastenheft 'End-to-End Kommunikationsabsicherung'

Endwerte siehe Begleitdokument 'S-PDU Kennungsfolgen'";

CM_ SG_ 1631 MO_DPF_reg "Regeneration Diesel-Partikel-Filter";
CM_ SG_ 1631 MO_Energieinhalt_BMS "Restenergieinhalt der Traktionsbatterie, beeinflusst durch Fahrstrategie und weiteren Faktoren der Antriebssteuerung.";
CM_ SG_ 1631 MO_Heizstrom_EKAT "Aktuelle Gesamtstromaufnahme des E-Katalysators";
CM_ SG_ 1631 MO_Heizstrom_SCR "Aktuelle Gesamtstromaufnahme der Tank-, Fördermodul- und Leitungsheizung des SCR-Systems";
CM_ SG_ 1631 MO_P_Generator_ungefiltert_Anf "Bei Empfang der Anforderung soll der Sender BEM_P_Generator ungefiltert befüllen.";
CM_ SG_ 1631 MO_SpannungsAnf_02 "Forderung des Motor-SG's zur Spannungsanhebung";
CM_ SG_ 1631 TSK_Fahrzeugmasse_02 "Neue Definition ab D4
Fahrzeugmasse in kg. Das Signal dient der Anpassung der Sollbeschleunigung vom ACC


";
CM_ SG_ 1631 TSK_Grundmasse "Fahrzeuggrundmasse in kg. Das Signal dient der Anpassung der Sollbeschleunigung vom ACC

Hinweis: Ehemaliger Fehlerwert 0x7F wird senderseitig nicht unterstützt. Diesen Wert aus Kompatibilitätsgründen nicht neu belegen!";
CM_ SG_ 1631 TSK_Steigung_02 "Steigung in % Berg. Das Signal dient der Anpassung der Sollbeschleunigung vom ACC

Positive Werte > bergauf; 
Negative Werte < bergab

Fehler: Die Steigung aufgrund eines Fehlers (mit KD-Fehlereintrag) nicht mehr berechnet werden";

CM_ SG_ 1648 MO1_Freigabe_Info_WFS "WFS-Freigabeinformation";
CM_ SG_ 1648 MO1_Freigabe_Verfallsinfo_WFS "WFS-Freigabeverfallsinformation";
CM_ SG_ 1648 MO1_Sperr_Info_WFS "WFS-Sperrinformation";
CM_ SG_ 1648 MO_Abstellzeit "Abstelldauer nach letztem KL15 aus

Hinweis: 
Ehemaliger Fehlerwert 0xFF wird senderseitig nicht unterstützt. 
Diesen Wert aus Kompatibilitätsgründen nicht neu belegen!";
CM_ SG_ 1648 MO_Abstellzeit_Status "Statusinformation zur Abstellzeit
0: Die dem Status zugeordnete Variable konnte noch nicht berechnet werden. 
1: Die dem Status zugehörige Variable wurde korrekt berechnet. 
2: Der Wert der zugehörigen Variablen ist nur ein Minimalwert. 
3: Der Wert d";
CM_ SG_ 1648 MO_ANC_Kennfeld_Anf "Anforderung ANC Kennfeldumschaltung";
CM_ SG_ 1648 MO_Anzahl_Abgesch_Zyl "Gibt die Anzahl der abgeschalteten Zylinder an. In Übergangszuständen wird der Zielbetriebszustand angezeigt.";
CM_ SG_ 1648 MO_Bremslicht_Reku "Bremslicht (ggf. bei Rekuperation durch E-Motor) wird angesteuert";
CM_ SG_ 1648 MO_Drehzahl_Warnung "Warnhinweis zum Kombi im Fall einer fehlerbehafteten Drehzahlbegrenzung";
CM_ SG_ 1648 MO_EPCL "Die Anforderung der EPC-Lampe vom MSG ans Kombi soll durch das Bus-Signal MO_EPCL gemäß folgender Logik erfolgen:
MO_EPCL = 0 dez -> EPC Lampe aus, kein Text
MO_EPCL = 1 dez -> gelbe EPC-Symbolik, Text „Antrieb: Störung! Bitte Service aufsuchen“
MO_EPC";
CM_ SG_ 1648 MO_Ethanol_BS_Texte "Ethanol Brennstoff-Texte im Kombi

0 = kein Text
1 = E85 Warm_Up
2 = FlexFuel Warnung 3.Stufe (Too cold for ethanol)
3 = Warmfahrempfehlung MQB / FlexFuel Warnung 1.Stufe (Refuel with gasoline)
4 = FlexFuel Warnung 2. Stufe (Refuel with gasoline)
5";
CM_ SG_ 1648 MO_Fahrzeugtyp "Unterscheidet die Fahrzeugtypen bzgl. der Antriebsart";
CM_ SG_ 1648 MO_Fehler_Zylabsch "Fehlerstatus der Funktion Zylinderabschaltung ";
CM_ SG_ 1648 MO_Hybrid_StartStopp_LED "Ansteuerung der Funktions-LED der Hybrid Taste bzw. Start/Stop Deaktivierungstaste.
Der Start/Stopp-Master (derzeit im MSG) (oder ein künftiger Hybrid-Master) soll die Ansteuerung senden.";
CM_ SG_ 1648 MO_max_Ladedruck "maximal möglicher Ladedruck (zur Anpassung des Anzeigebereichs bei absoluter Ladedruckanzeige)";
CM_ SG_ 1648 MO_NMAX_Schaltanzeige "Maximaldrehzahl für Schaltanzeige";
CM_ SG_ 1648 MO_obere_Drehzahlgrenze "obere Drehzahlgrenze des Motors";
CM_ SG_ 1648 MO_StartStopp_PopUp "Das Signal zeigt an, ob der StSt-Status mittels Deaktivierungstaster geändert wurde. Ein Wechsel auf die Werte 01 oder 10 löst im Kombi ein entsprechendes PopUp aus. Bei einem Statuswechsel durch andere Signalquellen (z.B. Charisma, fehlerbedingte Abschal";
CM_ SG_ 1648 MO_Zylabsch_Texte "Zylinderabschaltung mode in Kombi, fuer Zylinderabschaltung";
CM_ SG_ 1648 MO_Zylabsch_Texte_02 "ZAS-Anzeige für den Fahrer im Kombi
0: kein ZAS (generell keinerlei ZAS-Anzeigen)  (Init für nicht ZAS-Motor)
1: ZAS im Vollmotorbetrieb  (Init für ZAS-Motor)
2: ZAS im Abschaltbetrieb: 1 Zyl aktiv
3: ZAS im Abschaltbetrieb: 2 Zyl aktiv
4: ZAS im Abs";

CM_ SG_ 967 MO_E_Mode "Anforderung der E-Mode Statusanzeige";
CM_ SG_ 967 MO_E_Texte "Anforderung von Hinweistexten des E-Systems separat für HEV/BEV bzw. erweiterbar für PHEV";
CM_ SG_ 967 MO_E_Warnungen "Anforderung von Warnanzeigen des E-Systems separat für HEV/BEV bzw. erweiterbar für PHEV";
CM_ SG_ 967 MO_EFLEX_Lampe "Um ein Starten mit E100 zu ermöglichen, wird Kraftstoff ggf. vorgeheizt. Das Signal dient der Anzeige des Heizungsstatus.

Heizung aus -> Lampe aus
Heizung ein -> Lampe ein
Heizung ein und Startversuch -> Lampe blinkend
Heizung nicht möglich -> Lampe";
CM_ SG_ 967 MO_Heissleuchte "Ansteuerung der Kühlwassertemperatur-Heißleuchte (Sensor nur noch am Motorsteuergerät): Temperaturschaltschwellen mit Hysterese (bei VW D1/Colorado Kombi derzeit noch nicht genutzt).";
CM_ SG_ 967 MO_ITM_Warnung_Pumpe "Textanzeige: 'Motor sofort abstellen, geschaltete Wasserpumpe defekt / klemmt'";
CM_ SG_ 967 MO_KJS_nicht_bereit "Dieses Signal zeigen einen Fehler der Kühlerjalousie mit unbekannter Stellung der Lamellen. ";
CM_ SG_ 967 MO_Kuehlerluefter_1 "Ansteuertastverhaeltnis (PWM) der Kuehlerluefterendstufe 1";
CM_ SG_ 967 MO_Kuehlerluefter_2 "Ansteuertastverhaeltnis (PWM) der Kuehlerluefterendstufe 2";
CM_ SG_ 967 MO_Kuehlerluefter_MUX "Multiplexer für das Signal 'MO_Kuehlerlüfter'";
CM_ SG_ 967 MO_OBD2_Lampe "OBD bzw. MIL-Lampe wird vom Motorsteuergerät angesteuert, die Information im Signal GE_OBD_Status wird vom Motorsteuergerät an das Kombi weitergereicht";
CM_ SG_ 967 MO_Oelwarnung_max "Ölstandswarnung mit der Aufforderung zum Ölwechsel.
Hintergrund: Bei Kraftstoffeintrag (B20) ins Öl verbleibt der RME-Anteil irreversibel im Öl.";
CM_ SG_ 967 MO_Partikel_Lampe "Partikelfilter-Lampe wird eingeschaltet";
CM_ SG_ 967 MO_RedFahrleistung_Lampe "Ansteuerung der Turtle-Mode Lampe für E-Traktion Fahrzeuge";
CM_ SG_ 967 MO_Systemlampe "EGas Systemlampe (EPC) oder Vorglühlampe im Kombi, Kombi steuert immer gleiche
LED an, nur über Ziffernblatt wird die EPC von der Vorglühlampe differenziert";
CM_ SG_ 967 MO_Tankdeckel_Lampe "Ansteuerung Tankdeckel-Warnlampe Kombiinstrument (nur Ottomotoren) z.Zt. Vorhalt VW";
CM_ SG_ 967 MO_Text_Motorstart "Anzeigetexte für Start/Stopp und Motor-Start
0xB Fehler_Kupplungsschalter nur für PAG-MLB";
CM_ SG_ 967 MO_Text_Partikelfil_Reg "Über dieses Bit im Kombi wird ein Klartextanzeige erzeugt werden: 'Partikelfilter benötigt Regeneration'.
";
CM_ SG_ 967 MO_Text_Tankdeckelwarn "Textbit der Tankdeckelwarnung, z.Zt. Vorhalt VW";
CM_ SG_ 967 MO_Vorglueh_Lampe "Vorglühlampe im Kombi, Kombi steuert immer gleiche LED an. 
Mit Einführung des Einheits-Kombis sind getrennte Signalwege für Vorglühlampe und EPCL notwendig.";
CM_ SG_ 967 MO_Zustand_HWP "Rückmeldung des  Ansteuerzustand der Hauptwasserpumpe an das Klima-SG .
Der Zustand 'HWP fördert' wird übermittelt, wenn die Schaufeln der Hauptwasserpumpe frei drehen können und die Motordrehzahl und damit die Wasserpumpendrehzahl größer als Null ist. B";
CM_ SG_ 967 OLEV_Oelstand_nicht_vorhanden "Kein aktueller Ölstand vorhanden";
CM_ SG_ 967 OLEV_Systemstoerung "Systemstörung im Ölsystem";
CM_ SG_ 967 WIV_Anzeige_aktiv "Peilstabsanzeigefunktion aktiv";
CM_ SG_ 967 WIV_laufender_Motor "Messung bei laufendem Motor nicht möglich";
CM_ SG_ 967 WIV_nachfuellanzeige_ein "Steuert das Aufblenden der Nachfüllanzeige im Kombi, nach Klemme 15 ein und geöffneter Motorhaube";
CM_ SG_ 967 WIV_nicht_betriebswarm "Motor nicht betriebswarm, Messung ungenau";
CM_ SG_ 967 WIV_Oeldr_Warn_Motor "Löst im Kombiinstrument die rote Prio1-Öldruckwarnung (inkl. 3xBeep) aus.
nur MLB: die Warnauslösung erfolgt nur bei gleichzeitig gesetztem 'WIV_Enable_Oeldr_Motor'";
CM_ SG_ 967 WIV_Oeldyn_avl "Ölstand aus dynamischer Messung vorhanden";
CM_ SG_ 967 WIV_Oelmenge "Ölmenge zwischen Min und Max";
CM_ SG_ 967 WIV_Oelmin_Warn "Signal gibt an wenn der Ölstand die Min-Schwelle unterschritten hat";
CM_ SG_ 967 WIV_Oelstand "8 Segmente zur Balkenanzeige des Ölstands";
CM_ SG_ 967 WIV_Oelstand_nicht_vorhanden "Kein aktueller Ölstand vorhanden";
CM_ SG_ 967 WIV_Oelsystem_aktiv "Gesamtölsystem aktiv (entspricht Ölsensor verbaut) und das Ölstand-Untermenu im MMI aktiv";
CM_ SG_ 967 WIV_Schieflage "Fahrzeug steht nicht waagerecht, Messung ungenau";
CM_ SG_ 967 WIV_Sensorfehler "Ölstand/Öltemperatursensor (TOG) defekt";
CM_ SG_ 967 WIV_Ueberfuell_deaktiv "Unterdrückung der Warnung im Kombi die durch Signal WIV_Ueberfuel_Warn ausgelöst wird";
CM_ SG_ 967 WIV_Ueberfuell_Warn "Ölstand hat die Überfüllschwelle überschritten";
CM_ SG_ 967 WIV_Unterfuell_Warn "Ölstand hat die Unterfüllschwelle unterschritten";

CM_ SG_ 706 FDR_Warnung_ALR "Warnmeldungen der Allradverteilung";
CM_ SG_ 706 MO_ADR_Status "Status der Arbeitsdrehzahlregelung";
CM_ SG_ 706 MO_AGA_Sound_Texte "Textausgabe des aktuellen Sound-Zustandes der Abgasklappensteuerung";
CM_ SG_ 706 MO_Anz_Kuehlerluefter "Signal bei aktivem Kühlerlüfternachlauf (Motor aus) im Allgemeinen für die Anzeige im Kombi-Instument zur Information des Kunden über diesen Lüfterlauf";
CM_ SG_ 706 MO_Anzeige_FMAus_Text "Fehlerstatus des FMAus-Systems (z.B. Fehler im Zusatzspeicher)";
CM_ SG_ 706 MO_Anzeige_StSt_Symbol "Steuert die Anzeige der StSt-Symbolik im Kombi";
CM_ SG_ 706 MO_Anzeige_StSt_Text "Steuert die Anzeige der StSt-Texte im Kombi";
CM_ SG_ 706 MO_Rekuperationsstufe "In Projekten mit variablen oder anwählbaren Rekuperationsstufen soll dem Fahrer die aktuell ausgewählte Stufe über ein Icon in den Anzeigeinstrumenten visualisiert werden können. Dies dient der Nachvollziehbarkeit für den Kunden in Bezug auf eine zukünfti";
CM_ SG_ 706 PEA_Texte "Status der Funktion PEA";
CM_ SG_ 706 TSK_Einheit_vMax_FahrerInfo "Einheit zu TSK_vMax_FahrerInfo. Das MSG spiegelt hier KBI_MFA_v_Einheit und stellt den Anzeigewert in dieser Einheit zur Verfügung (kein zyklisches Mux)";
CM_ SG_ 706 TSK_Status_vMax_FahrerInfo "Status der TSK_vMax_FahrerInfo zur Steuerung von PopUps, Fahrzeugstatus und ggf. einer LED. Bei Wert 0 in TSK_vMax_Fahrerinfo soll auf eine unspezifische Begrenzung hingewiesen werden (z.B. wegen Momentenbegrenzung), bei allen anderen Werten soll dieser a";
CM_ SG_ 706 TSK_Ueberstimmt_vMax_FahrerInfo "Information ueber den Zustand wann die vMax-Limitierung vom Fahrer ueberstimmt wird.";
CM_ SG_ 706 TSK_vMax_FahrerInfo "anzuzeigende Begrenzungsgeschwindigkeit bei aktiver HGB";

CM_ SG_ 267 GRA_KuFu_aktiv "Status der Kundenfunktion Geschwindigkeitsregelanlage für VMM1.0";
CM_ SG_ 267 LIM_KuFu_aktiv "Status der Kundenfunktion bedienbarer Speed Limiter für VMM1.0";
CM_ SG_ 267 MO_Entkopplung_Sollschlupf "MSG fordert von GSG an, das Anfahrelement (Fahr-/Wandlerkupplung) zu entkoppeln; das GSG soll die gesendete Drehzahl als Schlupf einstellen und ggf. die Regler-Parameter umschalten, damit Rucke aus dem Antrieb nicht im Fahrzeug spürbar werden; nutzbar z.B";
CM_ SG_ 267 MO_Fahrpedalgradient "Das Motorsteuergerät besitzt 2 analoge Fahrpedalsignale. Das Signal des ersten Kanals wird alle 4ms abgetastet. Um Bitschwankungen des A/D-Wandler herauszufiltern wird das Signal entjittert. Anschließend wird der Gradient berechnet. Entsprechend der Zyklu";
CM_ SG_ 267 MO_Fahrpedalrohwert_01 "AUDI D4: Zykluszeit: 10ms (siehe Zykluszeit schnell/Cycletime Fast)

Stellung des Fahrpedales (Rohwert, ohne Überlagerung durch GRA-Eingriffe etc.)

Die Funktionen zur Berechung des Fahrpedalrohwerts laufen im 10ms Raster. Der Fahrpedalwert berechnet ";
CM_ SG_ 267 MO_Moment_im_Leerlauf "Fahrerwunschmoment ist minimal: keine Momentenanforderung durch Fahrpedal, ACC oder GRA+; (Das Signal ist unabhängig von Momentenerhöhungen durch Leerlaufregler oder MSR).

AUDI D4: Zykluszeit: 10ms (siehe Zykluszeit schnell/Cycletime Fast)

Achtung:";
CM_ SG_ 267 MO_QBit_Fahrpedalwerte_01 "AUDI D4: Zykluszeit: 10ms (siehe Zykluszeit schnell/Cycletime Fast)

QBit für beide Fahrpedalwerte des Motors (Fahrpedalrohsignal für ESP, EPB, ACC; Fahrpedalwert für Getriebe)

Achtung:
Reduktion der Zykluszeit Motor_03 auf 10ms geplant.
Projektabh";
CM_ SG_ 267 MO_rel_Saugrohrdruck "Der Wert gibt an, um wieviel mbar der Saugrohrdruck unterhalb des Umgebungsdrucks liegt. Überdruck im Saugrohr wird nicht ausgegeben.
0: Saugrohrdruck=Umgebungsdruck";
CM_ SG_ 267 MO_rel_Saugrohrdruck_gem_err "0: mind. eine Modellrechnung wird zur Berechnung des relativen Saugdrucks herangezogen
1: Relativer Saugrohrdruck wird ausschließlich über Messgrößen bestimmt";
CM_ SG_ 267 MO_Schubabschaltung "ESP plausibilisiert Unterdrucksensor nur bei aktiver Schubabschaltung

MLBevo:
Signal wird nur in MLBevo Projekten mit PDKII Getriebe bedient. In allen anderen MLBevo Projekten wird das Signal mit '0' bedient
PDKII berücksichtigt Verzugszeiten, die in";
CM_ SG_ 267 MO_Sig_Fahrpedalgradient "Kennzeichnet das Vorzeichen des Signal 'Fahrpedalgradient'. Die Ausgabe erfolgt nur parallel statisch mit gesendetem Signal: 'Steuerungsbit Fahrpedalgradient' ";
CM_ SG_ 267 MO_Solldrehz_Leerlauf "Leerlaufsolldrehzahl, die im Motor eingestellt ist (Bei Parallelhybrid im E-Fahr-Betrieb Leerlaufsolldrehzahl der E-Maschine). Der Motor paßt aufgrund der Anforderung von anderen Steuergeräten seine Leerlaufsolldrehzahl an, bspw. Kat-Heizen, Anforderung v";
CM_ SG_ 267 MO_Status_MaxDrzEingriff "Aktuell drehzahlführender Anforderer der Maximaldrehzahl (Begrenzungsregelung) des Pulswechselrichters der Primärachse";
CM_ SG_ 267 MO_Status_MaxDrzEingriff_sek "Aktuell drehzahlführender Anforderer der Maximaldrehzahl (Begrenzungsregelung) des Pulswechselrichters der Sekundärachse";
CM_ SG_ 267 MO_Status_MinDrzEingriff "Aktuell drehzahlführender Anforderer der Minimaldrehzahl (Begrenzungsregelung) des Pulswechselrichters der Primärachse";
CM_ SG_ 267 MO_Status_MinDrzEingriff_sek "Aktuell drehzahlführender Anforderer der Minimaldrehzahl (Begrenzungsregelung) des Pulswechselrichters der Sekundärachse";
CM_ SG_ 267 MO_temporaere_Fahrerabwesenheit "Das Signal dient zur Signalisierung einer temporären Abwesenheit des Fahrers. In dieser Zeit ist es ihm möglich, sich durch gewisse ¿ im Verlassenskonzept definierte ¿ Fahreraktionen im aktuellen Fahrzyklus zurückzumelden.
Das Signal wird gesetzt, sobald";
CM_ SG_ 267 Motor_51_BZ "4bit Botschaftszähler, wird mit jeder Sendebotschaft inkrementiert";
CM_ SG_ 267 Motor_51_CRC "Für MLB:
Berechnung siehe Lastenheft 'Kommunikationsabsicherung für FlexRay und CAN'
Ab MQB und MLBevo:
Berechnung siehe Lastenheft 'End-to-End Kommunikationsabsicherung'

Endwerte siehe Begleitdokument 'S-PDU Kennungsfolgen'";
CM_ SG_ 267 TSK_a_Soll_gradientenbegrenzt "TSK Sollbeschleunigung für Fahrerassistenzsysteme mit aktiver Längsführung (GRA, ACC, IPA...). Der Wert stellt den ruckbegrenzten Sollwert der TSK-Regelung dar und ist Basis der TSK-Antriebs- und Bremsmomentenvorsteuerung.";
CM_ SG_ 267 TSK_ax_Getriebe_02 "Beschleunigungsanforderung des Beschleunigungsreglers (u. a. für ACC, GRA, Speed Limiter). Das Signal wird vom Getriebe benutzt, um die von GRA/ACC geforderte Sollbeschleunigung in dem verbrauchsgünstigsten Gang einzustellen.
MQB: Im MQB wird die Sollbes";
CM_ SG_ 267 TSK_Freig_Verzoeg_Anf "Freigabe der Verzögerungsanforderung der ACC oder ggf. GRA+ Funktion für ECD Regelung im ESP";
CM_ SG_ 267 TSK_Freig_WU "Freigabe des TSK_Übersetzungswunsches bei ACC/GRA Betrieb bergab für die Verstellung nach kurz bzw. Rückschaltung im Getriebe.";
CM_ SG_ 267 TSK_Hauptschalter_GRA_ACC "Stellung des GRA/ACC Hauptschalters. Das Signal wird auch bei Fehlerabschaltungen von GRA/ACC weiterhin bedient und ermöglicht für ACC die Steuerung der ACC-Anzeige auch in Fehlerfällen.";
CM_ SG_ 267 TSK_Limiter_ausgewaehlt "ACC/GRA-Betrieb nur bei nicht ausgewähltem Limiter möglich";
CM_ SG_ 267 TSK_Radbremsmom "Bei der Schnittstelle vom TSK zum ESP soll in Folgeprojekten des B8 und insbesondere bei VW-Projekten die Ansteuerung der Bremse nicht über Sollbeschleunigung sondern Bremsmoment erfolgen.  Es handelt sich genauer um das Summenradbremsmoment, welches die ";
CM_ SG_ 267 TSK_SRBM_Anf_ASIL "ASIL-Level des TSK-Anforderers, der aktuell eine Bremsmomentenanforderung auslöst";
CM_ SG_ 267 TSK_SRBM_max_Gradient "In diesem Signal wird der vom TSK maximal geforderte SummenRadBremsMomentengradient gesendet, der von der Bremse bei der Umsetzung der TSK-Verzögerung nicht überschritten werden darf.";
CM_ SG_ 267 TSK_Standby_Anf_ESP "Mit diesem Bit wird das aktive Bremssystem auf eine anstehende TSK-Verzögerungsanforderung vorbereitet (Überfahren Leerweg, Anlegen Bremsbeläge)";
CM_ SG_ 267 TSK_Status "Betriebszustand des TSK-Reglers";
CM_ SG_ 267 TSK_v_Begrenzung_aktiv "Limiter oder HGB begrenzen die Beschleunigung/das Moment";
CM_ SG_ 267 TSK_Wunsch_Uebersetz "Bei ACC/GRA Betrieb bergab teilt der TSK dem Getriebe mit, dass eine Drehzahlerhöhung erwünscht ist, um mehr Schleppmoment und damit verbunden die nötige Verzögerung zu erzeugen, um die Geschwindigkeit konstant zu halten. 

Nutzung im VL: das Getriebe v";
CM_ SG_ 267 TSK_zul_Regelabw "Anforderung der zulässigen Regelabweichung vom Triebstrangkoordinator. Zulässiger Betrag der Abweichung zwischen angeforderter 'TSK_Sollbeschleunigung_Getriebe' und umzusetzender Sollbeschleunigung  im Getriebe. Im TSK wird, abhängig vom Arbeitspunkt die ";
CM_ SG_ 267 TSK_Zwangszusch_ESP "Mit diesem Bit wird das ESP/ASR zwangsweise aktiviert. Bei gesetztem Bit ist ein ausgetastetes ESP (oder ASR) wieder aktiviert bzw. wird die Austastung verhindert.";

CM_ SG_ 330 Ladezustand_02 "Aktueller relativer Ladezustand der HV-Batterie
";
CM_ SG_ 330 MO_Anzeige_Drehmoment "Drehmomentssignal für Sport-HMI im Kombi.";
CM_ SG_ 330 MO_Anzeige_Leistung "Leistungssignal für Sport-HMI im Kombi.";
CM_ SG_ 330 MO_Anzeige_Verbr_Einheit "Signal steht im Kontext MO_Anzeige_Verbrauch und überträgt die Verbrauchseinheit der aktuellen Antriebsart. Signal muss in der gleichen Botschaft wie MO_Anzeige_Verbrauch übertragen werden";
CM_ SG_ 330 MO_Anzeigedrehz "Optimierte Anzeigedrehzahl wegen sportlicherem Drehzahlmesser im Kombi. 
Bei Parallelhybrid: Anzeige VKM- Drehzahl nach Anzeigekonzept

Hinweis: Ehemaliger Fehlerwert 0xFFF wird senderseitig nicht unterstützt. Diesen Wert aus Kompatibilitätsgründen nic";
CM_ SG_ 330 MO_Effizienzmodus "Bei Handschaltern wird  das Fahrprogramm Effizienz signalisiert. 
Bei Automatikgetrieben wird das Fahrprogramm 'D' durch 'E' ersetzt.";
CM_ SG_ 330 MO_ePerformance "Zeigt die elektrische Leistungreserve bei BEV und PHEV Projekten an.
Bei Init und Fehler soll keine Anzeige erfolgen. ";
CM_ SG_ 330 MO_ePowermeter "Anzeige ePowermeter (Fahrreserve elektrisch bis Start Verbrennungsmotor (Verbrenner startet bei 100%))";
CM_ SG_ 330 MO_Fehler_Oeldrucksensor "Steuert  im Kombiinstrument die gelbe zentrale Warnlampe und das Symbol 'gelbe Ölkanne'  mit der Textmeldung 'Sensorfehler: Werkstatt aufsuchen' an
";
CM_ SG_ 330 MO_Hochschaltdrehz "Hochschaltdrehzahl bei manuellem Gangwechsel über Lenkrad Tip-Up oder Gangwahlhebel falls dieser in Tippgasse.
Nur AUDI RS-Modelle!";
CM_ SG_ 330 MO_Istgang "Aktueller Gang für Anzeige Hochschaltempfehlung (gültig, wenn MO_Schaltempf_verfbar = 1).

Anzeige im Kombi:
Sollgang == Istgang         ==> Anzeige Istgang
Sollgang !=   Istgang         ==> Schaltempfehlung
Sollgang == Istgang == 0 ==> keine Anzeige";
CM_ SG_ 330 MO_KVS "Motorsteuergerätinterner Verbrauchszähler, der vom Kombi zyklisch ausgelesen wird, um die Einspritzmenge zur Verbrauchsmessung aufzusummieren; aus diesem Zählerstand werden Momentan- und Durchschnittsverbrauch berechnet; das Überlauf-Bit ist zu berücksich";
CM_ SG_ 330 MO_KVS_Ueberlauf "Der motorsteuergeräteinterne Verbrauchszähler ist mindestens einmal übergelaufen. Dieses Bit wird genutzt, um erkennen zu können, daß das Motorsteuergerät aus dem Reset-Zustand hochläuft.";
CM_ SG_ 330 MO_Ladedruck "absoluter Ladedruck";
CM_ SG_ 330 MO_Oeldruck "Öldruck analog zur Anzeige";
CM_ SG_ 330 MO_Powermeter "Anzeigewerte im Kombi
0       = Unteres Ende Bremsen/grau;
340   = Unteres Ende CHARGE;
1020 = READY;
1870 = Oberes Ende EFFICIENCY;
3400 = 100%;
4080 = MAX;";
CM_ SG_ 330 MO_Powermeter_Elm_02 "relatives Moment / relative Leistung der elektrischen Maschine";
CM_ SG_ 330 MO_rel_Ladedruck "relativer Ladedruck (für Boostanzeige)";
CM_ SG_ 330 MO_Schaltblitz_Anz "Signalisierung der drehzahlabhängigen Schaltblitzanzeige im Kombiinstrument (0-100%)";
CM_ SG_ 330 MO_Schaltempf_verfbar "Info, ob Schaltempfehlung im Fzg. verfügbar. Statischer Wert, ändert sich für ein Fzg. nicht!";
CM_ SG_ 330 MO_Sollgang "Motor sendet den Sollgang in den der Fahrer schalten soll. Wird im Kombi als Hochschaltempfehlung hervorgehoben (gültig, wenn MO_Schaltempf_verfbar = 1).

Anzeige im Kombi:
Sollgang == Istgang          ==> Anzeige Istgang
Sollgang !=  Istgang         ";
CM_ SG_ 330 MO_Zust_Antrieb "Signalisiert die Zuordnung der Antriebsverbräuche zu den Antriebsmaschinen für die Restreichweitenberechnung, nicht gleichbedeutend mit Motorlauf EM oder VM";
CM_ SG_ 330 MO_Zust_Betriebsstrategie "Signalisiert den aktuellen Zustand der Betriebsstrategie";

CM_ SG_ 512 MO_Antriebsstrang_Warnung_HS "Status der Fehlerlampen-Ansteuerung und Textausgabe für Fehlerspeichereinträge aus der Kupplungsschutz-Funktion für Handschaltgetriebe.";
CM_ SG_ 512 MO_Anzeige_Betriebsmodus "Info an das Kombi zur Anzeige verschiedener Betriebsmodi";
CM_ SG_ 512 MO_Anzeige_Fahrbereitschaft "Signalisiert dauerhaft an das Kombi, ob die Fahrbereitschaft vorhanden ist (Drehzahlmesser auf READY)";
CM_ SG_ 512 MO_Anzeige_Rekuperation "Signal steht im Kontext zu MO_Anzeige_Verbrauch und wird für die Anzeige des Reku-Bereiches im grafischen Momentanverbrauch verwendet";
CM_ SG_ 512 MO_Anzeige_Verbrauch_oE "Anzeige Verbrauchssignal fürs Kombi. Im Bezug auf Verbrennerbeteiligung. Das Signal ist einheitenlos. Die zugehörige Einheit wird in MO_Anzeige_Verbr_Einheit übertragen.";
CM_ SG_ 512 MO_Boost_aktiv "Anzeige im Kombi ob Boost aktiv ist.
Die Anzeige wird zusätzlich über das Signal MO_Boost_verfuegbar gesteuert.
";
CM_ SG_ 512 MO_Boost_verfuegbar "Anzeige des aktuell verfügbaren Boostpotentials im Kombiinstrument.";
CM_ SG_ 512 MO_BZS_Charisma_FahrPr "Rückmeldung des aktuellen Charisma-Fahrprogramms der MSG Betriebsstrategie

MLBevo: Aktuelles Fahrprogramm des Charisma-Teilnehmers (siehe Systemlastenheft Drive Select)
MQB: Istwert der Kennlinie (siehe Systemlastenheft MQB FPA)";
CM_ SG_ 512 MO_BZS_Charisma_Status "Charisma Systemstatus des Charisma-Teilnehmers MSG (Betriebszustände)

Wert 0x3 ist nur für Fahrzeuge ab MQB relevant";
CM_ SG_ 512 MO_Charisma_FahrPr "MLBevo: Aktuelles Fahrprogramm des Charisma-Teilnehmers (siehe Systemlastenheft Drive Select)
MQB: Istwert der Kennlinie (siehe Systemlastenheft MQB FPA)";
CM_ SG_ 512 MO_Charisma_Status "Charisma Systemstatus des Charisma-Teilnehmers

Wert 0x3 ist nur für Fahrzeuge ab MQB relevant";
CM_ SG_ 512 MO_Drehzahlbeeinflussung "Faktor zur Anhebung der Fahrdrehzahl im Warmlauf";
CM_ SG_ 512 MO_Luftpfad_aktiv "Getriebeeingriff wird zusätzlich zum Zündungspfad auch über den Luftpfad umgesetzt, kommt zu MLB neu in die PL48-Getriebe";
CM_ SG_ 512 MO_MAX_Wunschdrehzahl "maximale Motorwunschdrehzahl, die vom Getriebe nicht überschritten werden darf

Signal darf GE_Synchro_Wunschdrehzahl nicht spiegeln";
CM_ SG_ 512 MO_MIN_Wunschdrehzahl "minimale Motorwunschdrehzahl aufgrund Regeneration, die vom Getriebe nicht unterschritten werden darf

Hinweis: 
Ehemaliger Fehlerwert 0xFF wird senderseitig nicht unterstützt. 
Diesen Wert aus Kompatibilitätsgründen nicht neu belegen!";
CM_ SG_ 512 MO_Motorlaufwarnung "Signal zur Anforderung der 'Motorlaufwarnung' im Kombi.";
CM_ SG_ 512 MO_NGS_Position "Messwert des Neutralgangsensors
(nur Handschalter)";
CM_ SG_ 512 MO_NGS_Status "Status des Signals MO_NGS_Position. Das MSG prüft die Plausibilität nur hinsichtlich sicher geöffnetem Triebstrang.";
CM_ SG_ 512 MO_Overboost "Nur Turbo. Anzeige eines Overboostpfeils im Kombi während Overboostzustand der Ladedruckregelung.";
CM_ SG_ 512 MO_Prio_MAX_Wunschdrehzahl "Prioritätsbit der Motorwunschdrehzahl  als MAX";
CM_ SG_ 512 MO_Prio_MIN_Wunschdrehzahl "Prioritätsbit der Motorwunschdrehzahl als MIN";
CM_ SG_ 512 MO_Rampenzeit_Generator_Anf "Das Motorsteuergerät kann eine Load-Response-Zeit des Generators vom Niedervoltenergiemanagement (NVEM) anfordern. Die Load-Response-Zeit wird vom NVEM umgesetzt, wenn dies bordnetzverträglich möglich ist.";
CM_ SG_ 512 MO_Sperrung_FahrPr_BZS "Sperrung einzelner Betriebszustände bzgl. Kommunikation zwischen Motor-SG und Charisma-SG (Gateway)";
CM_ SG_ 512 MO_StSt_Charisma_FahrPr "MLBevo: Aktuelles Fahrprogramm des Charisma-Teilnehmers (siehe Systemlastenheft Drive Select)
MQB: Istwert der Kennlinie (siehe Systemlastenheft MQB FPA)";
CM_ SG_ 512 MO_StSt_Charisma_Status "Charisma Systemstatus des Charisma-Teilnehmers

Wert 0x3 ist nur für Fahrzeuge ab MQB relevant";
CM_ SG_ 512 MO_v_Begrenz_Aktivierbar "Fehlerbit wird vom Motor-SG gesetzt, wenn dieses nicht in dieGeschwindigkeits-begrenzung gehen kann, ein Fehler während der v-Begrenzung auftritt oder v > v_Begrenzung - v_Delta";
CM_ SG_ 512 MO_v_Begrenzung_Niveau "Zeigt an, ob eine v-Begrenzung aufgrund Anforderung der Niveauregelung  im MSG aktiv ist oder nicht (Signal für Niveau zum Steuern der Kombianzeige).";
CM_ SG_ 512 PEA_Abschalttexte "Das Signal dient dem Anzeigen von Abschalttexten, wenn PEA nicht verfügbar ist";
CM_ SG_ 512 PEA_Ereignisanzeige "Das Signal dient der Anzeige des Hinweisgrundes";
CM_ SG_ 512 PEA_Ereignisanzeige_temporaer "Signal dient zur Steuerung einer TPA Anzeige im Kombi";
CM_ SG_ 512 PEA_Fortschrittsanzeige "Ablaufbalken für PEA-Hinweise";
CM_ SG_ 512 PEA_Hinweis "Aufforderung für Fahrerhandlung durch PEA";
CM_ SG_ 512 PEA_Zielgeschw "Das Signal dient der Anzeige einer Geschwindigkeit eines Geschwindigkeitsereignisses für PEA";
CM_ SG_ 512 PEA_Zielgeschw_Einheit "Einheit der anzuzeigenden Zielgeschwindigkeit für PEA (Prädiktiver Effizienz Assistent)";
CM_ SG_ 512 TSK_Akustik "Anforderung zur Ausgabe Akustischer Meldungen des Triebstrangkoordinators";
CM_ SG_ 512 TSK_Fahrzeugstatus_GRA "Zur Anzeige der Nicht-Verfuegbarkeit des Geschwindigkeitsregelanlage im Fahrzeugstatus";
CM_ SG_ 512 TSK_Fahrzeugstatus_Limiter "Zur Anzeige der Nicht-Verfuegbarkeit des Speedlimiters im Fahrzeugstatus";
CM_ SG_ 512 TSK_Fahrzeugstatus_praed_Fkt "Zeigt den Status der Prädiktion der Kundenfunktionen P_LIM und P_ GRA an";
CM_ SG_ 512 TSK_Limiter_Anzeige "Signalisiert den Wunsch des MSG an das Kombiinstrument, seine Anzeige auf Limiter umzuschalten";
CM_ SG_ 512 TSK_Limiter_Fahrerinfo "Fahrerhinweise und Warnungen des Speedlimiters";
CM_ SG_ 512 TSK_naechstes_Event "Anzeige des naechsten Streckenereignisses, welches in der PGRA-PLIM Regelung eine Änderung der Zielgeschwindigkeit zur Folge hat";
CM_ SG_ 512 TSK_naechstes_Event_Einheit "Das Signal zeigt an in welcher Einheit der Hinweis anzuzeigen ist. Bspw. Schilder in mph und Anzeige in Km/h";
CM_ SG_ 512 TSK_praediktiver_Hinweis "Anzeigesteuerung ob Geschwindigkeitshinweis als Vorschlag (zur Übernahme) oder als Hinweis (bei automatischer Übernahme) behandelt werden soll";
CM_ SG_ 512 TSK_Status_Anzeige "Signalisiert den Status von GRA oder Limiter zur Anzeige im Kombiinstrument.
Der Signalwert 'Limitierung_aktiv' wird nur verwendet für den Audi Speedlimiter und zeigt bei aktivier Funktion an, dass nahe an der Abregelgeschwindigkeit gefahren wird und die";
CM_ SG_ 512 TSK_Texte "Textmeldungen des TSK zur Darstellung im Kombi";
CM_ SG_ 512 TSK_Texte_Primaeranz "Trigger für Anzeigetexte von GRA und Limiter, GRA Temporäranzeige (Audi) und Limiter Warnungen

0 keine Anzeige 
1 GRA Symbol passiv xxx km/h / mph (nur Audi)
2 GRA Symbol aktiv xxx km/h / mph (nur Audi)
3 Bremse überhitzt ! (reserv.)
4 Limiter Modu";
CM_ SG_ 512 TSK_Wunschgeschw "Zur Anzeige der Wunschgeschwindigkeit von GRA/Speedlimiter im Kombiinstrument";

CM_ SG_ 332 FoD_DTC_TSK_ACC "DTC ist entweder bereits eingetragen oder wird eingetragen, sobald die zugehörige FOD Funktion freigeschaltet wird.";
CM_ SG_ 332 FoD_DTC_TSK_GRA "DTC ist entweder bereits eingetragen oder wird eingetragen, sobald die zugehörige FoD Funktion freigeschaltet wird.";
CM_ SG_ 332 MO_Anforderung_HMS "Halteanforderung vom Motor an HMS";
CM_ SG_ 332 MO_EBoost_verf_praed "Zeigt an, ob für eine im Projekt definierte Zeit (max. 10s) E-Boost in Höhe von EM1_maxPred_Moment verfügbar sein wird.

0 - Init_oder_nicht_verfügbar
1 - EBoost_kurzzeit_verfügbar (~3Sek.)
2 - EBoost_langzeit_verfügbar (~10Sek)";
CM_ SG_ 332 MO_eLaunch_verf "Zeigt an, ob aus Antriebssicht E-Launch verfügbar ist.";
CM_ SG_ 332 MO_Fahrbereitschaft "Das Signal MO_Fahrbereitschaft zeigt in mehreren Stufen an, ob der Motor in einem anfahrbereiten Zustand ist.";
CM_ SG_ 332 MO_Freilauf_Info "Freilauf Informationssignal vom Motorsteuergerät zum Getriebesteuergerät. Das Motorsteuergerät kann über dieses Signal den Freilauf freigeben, verhindern bzw. explizit anfordern.";
CM_ SG_ 332 MO_Freilauf_Status "Freilauf-Status-Signal vom Frailauf-Master an aktive Freilauf-Teilnehmer. In diesem Signal zeigt der Freilauf-Master an, welchen aktuellen Status die Freilauf-Betriebsstrategie hat.";
CM_ SG_ 332 MO_Freilauf_Typ "Beschreibt die vom MSG unterstützte Freilauffunktionalität:
Koordinator GSG = Freilauf nur in Eco 
Koordinator GSG mit FP-Grad = Freilauf 'Default on', GSG kann Freilauf auch in D und in Abhängigkeit des Fahrpedalgradienten steuern
Koordinator MSG = Fr";
CM_ SG_ 332 MO_Heckspoiler_Anf "Anforderung den Heckspoiler zur Ladeluft- bzw. Motorraumkühlung auszufahren.";
CM_ SG_ 332 MO_Krit_Heckobjekt "Beschreibt die Kritikalität des hinter einem in der Spur fahrenden Fahrzeuges";
CM_ SG_ 332 MO_NGS_Gangpos "Gang- bzw. Neutralinformation des erweiterten Neutralgangsensors. Bedingt durch den eingeschränkten Erfassungssbereich des Sensors sind die Ganginformationen als eingelegt bzw. fast eingelegt/vorausgewählt zu interpretieren (nur Handschalter)";
CM_ SG_ 332 MO_Positionierung_aktiv "Zeigt an, dass die Motorpositionierung mit Hilfe des Riemenstartergenerator momentan aktiv ist.";
CM_ SG_ 332 MO_QBit_Aussen_Temp "QBit der Aussentemperatur. Gesetzt bei Ersatzwert, Init oder Fehler.";
CM_ SG_ 332 MO_Servicemodus "Ausgabe aktiver Service-Mode";
CM_ SG_ 332 MO_Startwunsch "o	Setzen bei Erfüllung der kompletten Fahrerbedienhandlung (z.B. Zündanlasstaster + Bremse + Fahrstufe P/N [klassisch] oder Fahrstufe D/R + Bremse [MEB]), je nach Fahrzeug z.T. bereits vor oder immer erst nach Einschalten der Klemme 15;
o	Rücksetzen bei ";
CM_ SG_ 332 OBD_Abs_Load_Val "Absolute Load Value

Übertragung von Meßgrößen an das Getriebesteuergerät für Freeze Frame Abspeicherung bei Getriebefehlern

PID $43 Absolute Load Value; 0 .. 25700%  mit 100/255 %/bit";
CM_ SG_ 332 OBD_Abs_Pedal_Pos "Absolute Pedal Position

Übertragung von Meßgrößen an das Getriebesteuergerät für Freeze Frame Abspeicherung bei Getriebefehlern

PID $49 Accelerator Pedal Position D; 0 .. 100% mit 100/255 %/bit";
CM_ SG_ 332 OBD_Abs_Throttle_Pos "Absolute Throttle Position

Übertragung von Meßgrößen an das Getriebesteuergerät für Freeze Frame Abspeicherung bei Getriebefehlern

PID $11 Absolute Throttle Position; 0 .. 100% mit 100/255 %/bit";
CM_ SG_ 332 OBD_Aussen_Temp_gef "Gefilterte Aussentemperatur vom Motor für OBD Funktionen.";
CM_ SG_ 332 OBD_Calc_Load_Val "Calculated Load Value

Übertragung von Meßgrößen an das Getriebesteuergerät für Freeze Frame Abspeicherung bei Getriebefehlern

PID $04 Calculated Load Value; 0 .. 100% mit 100/255 % per bit
";
CM_ SG_ 332 OBD_ClearMem_Inhibit "Das Fehlerspeicher löschen soll nur noch bei stehendem Fahrzeug über Service-04hex ausgeführt werden, dafür wird vom MIL-Master ein CAN Signal benötigt, das das Löschen unter bestimmten Randbedingungen nicht zulässig ist";
CM_ SG_ 332 OBD_Eng_Cool_Temp "Engine Coolant Temperature

Übertragung von Meßgrößen an das Getriebesteuergerät für Freeze Frame Abspeicherung bei Getriebefehlern

PID $05 Engine Coolant Temperature; -40 .. +215°C mit 1°C/bit und 40°C Offset";
CM_ SG_ 332 OBD_Kaltstart_Denominator "Bestimmte Diagnosen werden nur unter Kaltstartbedingungen durchgeführt, der entsprechende Denominator bei IUMPR-pflichtigen Systemen wird anhand dieses vom MSG gebildeten Signals inkrementiert. (Entspricht EVAP-Denominator)";
CM_ SG_ 332 OBD_Minimum_Trip "Grundlage OBD-Gesetz CCR 1968.2 (d)(4.3) Denominator Specifications
Bildung des General Denominator 'Normed Trip':
 600 sec. (kumulativ) Zeit nach Motorstart
 300 sec. (kumulativ) mit Fahrzeuggeschwindigkeit > 25 mph (40 km/h)
 30 sec. (kontinuierlich";
CM_ SG_ 332 OBD_Normed_Trip "Gesetzlich definierte 'Normed Condition' erfüllt, 'General Denominator' darf erhöht werden";
CM_ SG_ 332 OBD_Sperrung_IUMPR "Wenn der General Denominator auf Grund eines Fehlers in den Eingangsgrößen gesperrt wird, wird diese Information über Bussystem als OBD-Statusinformation OBD_Sperrung_IUMPR für andere OBD-Steuergeräte bereitgestellt. 

Das MSG (MIL-Master) setzt dieses ";
CM_ SG_ 332 OBD_Sperrung_Kaltstart_Denom "Information vom MIL Master, dass die Bildung des EVAP Denominators  im Motor nicht möglich ist und damit der noECM-Denominator gesperrt werden darf.";
CM_ SG_ 332 OBD_Warm_Up_Cycle "Mit dem Warm-Up-Cycle wird der zentrale Verlernzähler vom Gateway inkrementiert";
CM_ SG_ 332 TSK_ACC_FoD_Status "Information, ob die TSK-ACC-Funktion freigeschaltet ist oder nicht.";
CM_ SG_ 332 TSK_aktives_System "Anzeige der in der TSK-Längsführung aktiven Funktion";
CM_ SG_ 332 TSK_Anf_Antriebsmoment "Das Signal zeigt an, ob die TSK-Laengsregelung aktuell Antriebsmoment anfordert, zur Verwendung in der ASR/EDS-Funktion";
CM_ SG_ 332 TSK_Einheit_vMax_Fahrerassistenz "Einheit zu Signal TSK_vMax_Fahrerassistenz";
CM_ SG_ 332 TSK_erhoehter_Fahrwiderstand "Rueckmeldung vom Triebstrangkoordinator, dass eine große Reglerdifferenz detektiert wurde. Soll ermoeglichen, einen ggfs. unbekannten Fahrwiderstand am Boden zu erkennen.";
CM_ SG_ 332 TSK_GRA_FoD_Status "Information, ob die TSK-GRA-Funktion freigeschaltet ist oder nicht.";
CM_ SG_ 332 TSK_Status_ARA "Funktionsstatus des Triebstrangkoordinators für den Anhängerrangierassistenten";
CM_ SG_ 332 TSK_Status_EA "Funktionsstatus des Triebstrangkoordinators für den Anforderer Emergency Assist";
CM_ SG_ 332 TSK_Status_IPA "Funktionsstatus des Triebstrangkoordinators für die Längsführung des Einparkassistenten";
CM_ SG_ 332 TSK_Status_PLA "Funktionsstatus des Triebstrangkoordinators für den Speedlimiter des Parkassistenten";
CM_ SG_ 332 TSK_vMax_aktuell "Im aktuellen Betriebszustand global gültige Geschwindigkeitslimitierung.";
CM_ SG_ 332 TSK_vMax_Fahrerassistenz "maximale Sollgeschwindigkeit für GRA/ACC/Limiter
Hinweis: Signal ist mit Signal TSK_Einheit_vMax_Fahrerassistenz zu interpretieren.  Das Signal wird abwechselnd in km/h und mph gesendet.";

CM_ SG_ 246 FDR_Allrad_Anteil_max_sek "Maximaler prozentualer Anteil der sekundären Antriebsachse am Gesamtmoment - wird soweit dies durch die Leistungsfähigkeit der Achse möglich ist eingehalten";
CM_ SG_ 246 FDR_Allrad_Anteil_min_sek "Minimaler prozentualer Anteil der sekundären Antriebsachse am Gesamtmoment - wird soweit dies durch die Leistungsfähigkeit der Achse möglich ist eingehalten";
CM_ SG_ 246 FDR_MomRad_Eingriff "maximal zulässiges Moment primäre Antriebsachse";
CM_ SG_ 246 FDR_MomRad_Eingriff_sek "maximal zulässiges Moment sekundäre Antriebsachse";
CM_ SG_ 246 FDR_Status_Eingriff "Eingriff primäre Antriebsachse aktiv";
CM_ SG_ 246 FDR_Status_Eingriff_sek "Eingriff sekundäre Antriebsachse aktiv";
CM_ SG_ 246 Motor_55_BZ "4bit Botschaftszähler, wird mit jeder Sendebotschaft inkrementiert";
CM_ SG_ 246 Motor_55_CRC "Für MLB:
Berechnung siehe Lastenheft 'Kommunikationsabsicherung für FlexRay und CAN'
Ab MQB und MLBevo:
Berechnung siehe Lastenheft 'End-to-End Kommunikationsabsicherung'

Endwerte siehe Begleitdokument 'S-PDU Kennungsfolgen'";
CM_ SG_ 246 TS_Allrad_Anteil_sek "Vom Antrieb gewünschter prozentualer Anteil der sekundären Antriebsachse am Gesamtmoment";
CM_ SG_ 246 TS_Faktor_Radmomente "Schaltet den Wertebereich von Rad-Momenten-Signale diverser SG um, so dass zum einen die max. möglichen Werte übertragen werden können und zum anderen die Auflösung möglichst hoch ist.
Faktor ist über Laufzeit konstant, variiert nur zwischen Fahrzeug-Pro";
CM_ SG_ 246 TS_MomRad_Ist "Gesamt-Istmoment der Antriebsmaschinen, umgerechnet auf Radebene, unter Berücksichtigung der Massenträgheiten der Antriebsmaschinen und des Getriebes, unter Berücksichtigung der Verluste der Antriebsmaschinen, der Nebenaggregate und des Getriebes (d.h. ke";
CM_ SG_ 246 TS_MomRad_Ist_sek "Gesamt-Istmoment der Antriebsmaschinen, umgerechnet auf Radebene, unter Berücksichtigung der Massenträgheiten der Antriebsmaschinen und des Getriebes, unter Berücksichtigung der Verluste der Antriebsmaschinen, der Nebenaggregate und des Getriebes.
Zeigt ";
CM_ SG_ 246 TS_MomRad_Soll_Summe "Faktor in TS_Faktor_Radmomente beachten!

Momentenanforderung aus Fahrpedal bzw. von ACC/GRA bzw. aus dem Leerlaufregler (quasistatischer Anteil); keine Begrenzungen, keine Fahrverhaltensformung, keine Abbildung externer Eingriffsanforderungen; definier";
CM_ SG_ 246 TS_MomRad_verfuegb_max "Faktor in TS_Faktor_Radmomente beachten!

In aktuellem Betriebszustand (u.a. Übersetzung) kurzfristig (ca. 100..200 ms) verfügbares max. positives Moment; 

Zeigt bei antriebstechnisch getrennten Achsen das Moment der primären Achse; zeigt bei mechani";
CM_ SG_ 246 TS_MomRad_verfuegb_max_sek "Faktor in TS_Faktor_Radmomente beachten!

In aktuellem Betriebszustand (u.a. Übersetzung) kurzfristig (ca. 100..200 ms) verfügbares max. positives Moment; 

Zeigt bei antriebstechnisch getrennten Achsen das Moment der sekundären Achse; steht bei mecha";
CM_ SG_ 246 TS_MomRad_verfuegb_maxReku "Faktor in TS_Faktor_Radmomente beachten!

In aktuellem Betriebszustand (u.a. Übersetzung) kurzfristig (ca. 100..200 ms) verfügbares max. negatives Moment; 

Zeigt bei antriebstechnisch getrennten Achsen das Moment der primären Achse; zeigt bei mechani";
CM_ SG_ 246 TS_MomRad_verfuegb_maxReku_sek "Faktor in TS_Faktor_Radmomente beachten!

In aktuellem Betriebszustand (u.a. Übersetzung) kurzfristig (ca. 100..200 ms) verfügbares max. negatives Moment; 

Zeigt bei antriebstechnisch getrennten Achsen das Moment der sekundären Achse; steht bei mecha";
CM_ SG_ 246 TS_MomRad_verfuegb_maxReku_Summe "Im aktuellen Betriebszustand kurzfristig (ca. 100..200 ms) verfügbares max. negatives Summenmoment; definiert auf Bezugsebene Rad.
Faktor in TS_Faktor_Radmomente beachten!";
CM_ SG_ 246 TS_MomRad_Wunsch "Faktor in TS_Faktor_Radmomente beachten!

Wunsch-Moment nach MSG-Betriebs-Strategie-Aufteilung und Umverteilung der Achs-Aufteilung durch EF; nach Lastschlagdämpfung der jeweiligen Achse; incl. Deckelung aufgrund von Schutz-Eingriffen, ohne Berücksichti";
CM_ SG_ 246 TS_MomRad_Wunsch_sek "Faktor in TS_Faktor_Radmomente beachten!

Wunsch-Moment nach MSG-Betriebs-Strategie-Aufteilung und Umverteilung der Achs-Aufteilung durch EF; nach Lastschlagdämpfung der jeweiligen Achse; incl. Deckelung aufgrund von Schutz-Eingriffen, ohne Berücksichti";
CM_ SG_ 246 TS_Status_MomRad_Ist "Qualitätsstatus zu TS_MomRad_Ist und TS_MomRad_Ist_Sek
Qualifiziert bei antriebstechnisch getrennten Achsen sowohl das Moment der primären Achse als auch das Moment der sekundären Achse, und bei mechanischem Allradantrieb das Gesamtmoment für beide Achse";

CM_ SG_ 190 MO_DC_Max_Strom_HV "Abregelgrenze: maximal freigegebener Strom auf der Hochvolt-Seite im Tiefsetzbetrieb (Strom aus dem Traktionsnetz ins Bordnetz)";
CM_ SG_ 190 MO_DC_SollSpannung_HV "Sollwert für die Traktionsnetzspannung im Hochsetzbetrieb vom Bordnetz ins Traktionsnetz
vorgehaltenes Signal; wird in PQ35/PL71 nicht berücksichtigt";
CM_ SG_ 190 MO_EM1_AR_Anf "Anforderung der Anti-Ruckel Funktion auf der E-Maschine

0: aus
1: nicht belegt
2: D2T2 Regelung
3: Referenzdrehzahl Regelung
4: interne Referenzdrehzahlregelung";
CM_ SG_ 190 MO_EM1_DynLimit_AR "Auslöseschwelle für dynamische Ruckeldämpfung

Der Momentenwert ergibt sich aus der Multiplikation mit dem Faktor MO_EM1_Faktor_AR_Momente (Skalierung Wertebereich und Auflösung).";
CM_ SG_ 190 MO_EM1_Kp_AR "dynamischer Verstärkungsfaktor zur Umrechnung Drehzahlschwingung in Eingriffsmoment";
CM_ SG_ 190 MO_EM1_Max_Leistung "zugeteilte elektrische Leistung für den motorischen Betrieb; elektrische Leistung zur Berechnung eines momentan möglichen maximalen Moments und einer momentan möglichen maximalen mechanischen Leistung";
CM_ SG_ 190 MO_EM1_Max_Moment "maximal erlaubtes positives (motorisches) Moment der E-Maschine aus Hybridstrategie";
CM_ SG_ 190 MO_EM1_Max_Strom_Lim "maximal zulässiger HV-Strom, der von der LE im motorischen Betrieb aufgenommen werden darf; Abregelstrom zur Begrenzung des maximalen Moments im motorischen Betrieb";
CM_ SG_ 190 MO_EM1_MaxDrehzahl "Maximale E-Maschinen-Drehzahl";
CM_ SG_ 190 MO_EM1_Min_Leistung "zugeteilte elektrische Leistung für den generatorischen Betrieb (betragsmäßig maximal aber i.d.R. negativ, daher ‚Min‘);; elektrische Leistung zur Berechnung eines momentan möglichen minimalen Moments und einer momentan möglichen minimalen mechanischen Le";
CM_ SG_ 190 MO_EM1_Min_Moment "maximal erlaubtes negatives (generatorisches) Moment der E-Maschine aus Hybridstrategie";
CM_ SG_ 190 MO_EM1_Min_Strom_Lim "minimal zulässiger HV-Strom, der von der LE im generatorischen Betrieb abgegeben werden darf (betragsmäßig maximal aber i.d.R. negativ, daher ‚Min‘); Abregelstrom zur Begrenzung des minimalen Moments im generatorischen Betrieb";
CM_ SG_ 190 MO_EM1_MinDrehzahl "Minimale E-Maschinen-Drehzahl";
CM_ SG_ 190 MO_EM1_Periode_AR "Zeitkonstante (Periodendauer) der Ruckelschwingung (abhängig vom Gang und ggf. elektrischem/hybridischem Fahren) ";
CM_ SG_ 190 MO_EM1_Sollmodus "Werte:
  Anforderung der Betriebsart der E-Maschine
0: Standby; Kommunikation aktiv; aktiver Kurzschluss
1: Momentenregelung
2: Drehzahlregelung (interner Regelkreis)
3: Spannungsregelung
4: Drehzahlregelung (externer Regelkreis)
5: nicht verfügbar";
CM_ SG_ 190 MO_EM1_SollMoment "E-Maschinen Soll-Moment vom Hybridcontroller";
CM_ SG_ 190 MO_EM1_SollSpannung "E-Maschinen Soll-Spannung";
CM_ SG_ 190 MO_EM2_AR_Anf "Anforderung der Anti-Ruckel Funktion auf der E-Maschine

0: aus
1: nicht belegt
2: D2T2 Regelung
3: Referenzdrehzahl Regelung
4: interne Referenzdrehzahlregelung";
CM_ SG_ 190 MO_EM2_DynLimit_AR "Auslöseschwelle für dynamische Ruckeldämpfung

Der Momentenwert ergibt sich aus der Multiplikation mit dem Faktor MO_EM2_Faktor_AR_Momente (Skalierung Wertebereich und Auflösung).";
CM_ SG_ 190 MO_EM2_Max_Leistung "zugeteilte elektrische Leistung für den motorischen Betrieb; elektrische Leistung zur Berechnung eines momentan möglichen maximalen Moments und einer momentan möglichen maximalen mechanischen Leistung";
CM_ SG_ 190 MO_EM2_Max_Moment "maximal erlaubtes positives (motorisches) Moment der E-Maschine aus Hybridstrategie";
CM_ SG_ 190 MO_EM2_Max_Strom_Lim "maximal zulässiger HV-Strom, der von der LE im motorischen Betrieb aufgenommen werden darf; Abregelstrom zur Begrenzung des maximalen Moments im motorischen Betrieb";
CM_ SG_ 190 MO_EM2_MaxDrehzahl "Maximale E-Maschinen-Drehzahl";
CM_ SG_ 190 MO_EM2_Min_Leistung "zugeteilte elektrische Leistung für den generatorischen Betrieb (betragsmäßig maximal aber i.d.R. negativ, daher ‚Min‘);; elektrische Leistung zur Berechnung eines momentan möglichen minimalen Moments und einer momentan möglichen minimalen mechanischen Le";
CM_ SG_ 190 MO_EM2_Min_Moment "maximal erlaubtes negatives (generatorisches) Moment der E-Maschine aus Hybridstrategie";
CM_ SG_ 190 MO_EM2_Min_Strom_Lim "minimal zulässiger HV-Strom, der von der LE im generatorischen Betrieb abgegeben werden darf (betragsmäßig maximal aber i.d.R. negativ, daher ‚Min‘); Abregelstrom zur Begrenzung des minimalen Moments im generatorischen Betrieb";
CM_ SG_ 190 MO_EM2_MinDrehzahl "Minimale E-Maschinen-Drehzahl";
CM_ SG_ 190 MO_EM2_Periode_AR "Zeitkonstante (Periodendauer) der Ruckelschwingung (abhängig vom Gang und ggf. elektrischem/hybridischem Fahren) ";
CM_ SG_ 190 MO_EM2_Sollmodus "Werte:
  Anforderung der Betriebsart der E-Maschine
0: Standby; Kommunikation aktiv; aktiver Kurzschluss
1: Momentenregelung
2: Drehzahlregelung (interner Regelkreis)
3: Spannungsregelung
4: Drehzahlregelung (externer Regelkreis)
5: nicht verfügbar";
CM_ SG_ 190 MO_EM2_SollMoment "E-Maschinen Soll-Moment vom Hybridcontroller";
CM_ SG_ 190 MO_EM2_SollSpannung "E-Maschinen Soll-Spannung";
CM_ SG_ 190 Motor_56_BZ "4bit Botschaftszähler, wird mit jeder Sendebotschaft inkrementiert";
CM_ SG_ 190 Motor_56_CRC "Für MLB:
Berechnung siehe Lastenheft 'Kommunikationsabsicherung für FlexRay und CAN'
Ab MQB und MLBevo:
Berechnung siehe Lastenheft 'End-to-End Kommunikationsabsicherung'

Endwerte siehe Begleitdokument 'S-PDU Kennungsfolgen'";

CM_ SG_ 2463978666 MO_Drehzahl_EM "Effektivdrehzahl, die am E-Maschinenausgang ermittelt wird, die für die Primärachse zur Verfügung steht";
CM_ SG_ 2463978666 MO_Drehzahl_EM_sek "Effektivdrehzahl, die am E-Maschinenausgang ermittelt wird, die für die Sekundärachse zur Verfügung steht";
CM_ SG_ 2463978666 MO_EM1_Generator_Leistung "elektrische Wunschleistung zur Berechnung eines momentan erforderlichen Moments im Generatorbetrieb";
CM_ SG_ 2463978666 MO_EM1_Max_Leistung_Gesamt "im Gesamtsystem verfügbare elektrische Leistung für den motorischen Betrieb; elektrische Leistung zur Berechnung eines momentan möglichen";
CM_ SG_ 2463978666 MO_EM1_Max_Spannung_Lim "maximal zulässige HV-Spannung (DC), die von der LE im generatorischen Betrieb nicht überschritten werden darf; Abregelspannung zur Begrenzung des minimalen Moments im generatorischen Betrieb";
CM_ SG_ 2463978666 MO_EM1_Min_Leistung_Gesamt "vom Gesamtsystem aufnehmbare elektrische Leistung für den generatorischen Betrieb (betragsmäßig maximal aber i.d.R. negativ, daher ‚Min‘); elektrische Leistung zur Berechnung eines momentan möglichen minimalen Moments (maximal genaratorisch)";
CM_ SG_ 2463978666 MO_EM1_Min_Spannung_Lim "minimal zulässige HV-Spannung (DC), die von der LE im motorischen Betrieb nicht unterschritten werden darf; Abregelspannung zur Begrenzung des maximalen Moments im motorischen Betrieb";
CM_ SG_ 2463978666 MO_EM2_Max_Leistung_Gesamt "im Gesamtsystem verfügbare elektrische Leistung für den motorischen Betrieb; elektrische Leistung zur Berechnung eines momentan möglichen";
CM_ SG_ 2463978666 MO_EM2_Max_Spannung_Lim "maximal zulässige HV-Spannung (DC), die von der LE im generatorischen Betrieb nicht überschritten werden darf; Abregelspannung zur Begrenzung des minimalen Moments im generatorischen Betrieb";
CM_ SG_ 2463978666 MO_EM2_Min_Leistung_Gesamt "vom Gesamtsystem aufnehmbare elektrische Leistung für den generatorischen Betrieb (betragsmäßig maximal aber i.d.R. negativ, daher ‚Min‘); elektrische Leistung zur Berechnung eines momentan möglichen minimalen Moments (maximal genaratorisch)";
CM_ SG_ 2463978666 MO_EM2_Min_Spannung_Lim "minimal zulässige HV-Spannung (DC), die von der LE im motorischen Betrieb nicht unterschritten werden darf; Abregelspannung zur Begrenzung des maximalen Moments im motorischen Betrieb";
CM_ SG_ 2463978666 MO_Rekuperation_EM_Ges_Ueberlauf "Rekuperationleistungssignal mindest 1x übergelaufen";
CM_ SG_ 2463978666 MO_Rekuperation_Ges_EM "Rekuperation-Energie des Antriebs";
CM_ SG_ 2463978666 MO_Uebersetzung_EM "Übersetzung von MO_Drehzahl_EM zur Primärachse, wenn eine Verbindung sicher hergestellt ist";
CM_ SG_ 2463978666 MO_Uebersetzung_EM_sek "Übersetzung von MO_Drehzahl_EM_sek zur Sekundärachse, wenn eine Verbindung sicher hergestellt ist";
CM_ SG_ 2463978666 MO_Verbrauch_EM_Ges "Antriebs-Energie des Antriebs";
CM_ SG_ 2463978666 MO_Verbrauch_EM_Ges_Ueberlauf "Verbrauchssignal mindest 1x übergelaufen";
BA_DEF_REL_ BU_SG_REL_  "GenSigTimeoutTime" INT 0 65535;
BA_DEF_ BO_  "DiagRequest" ENUM "No", "Yes";
BA_DEF_ BO_  "DiagResponse" ENUM "No", "Yes";
BA_DEF_ BO_  "DiagState" ENUM "No", "Yes";
BA_DEF_ BO_  "GenMsgChkConstant" HEX 0 4095;
BA_DEF_ BO_  "GenMsgCycleTime" INT 0 65535;
BA_DEF_ BO_  "GenMsgCycleTimeFast" INT 0 65535;
BA_DEF_ BO_  "GenMsgDelayTime" INT 0 100000;
BA_DEF_ BO_  "GenMsgILSupport" ENUM "No", "Yes";
BA_DEF_ BO_  "GenMsgNrOfRepetition" INT 0 100;
BA_DEF_ BO_  "GenMsgPDUConstants" STRING;
BA_DEF_ BO_  "GenMsgSendType" ENUM "Cyclic", "not_used", "not_used", "not_used", "not_used", "not_used", "not_used", "IfActive", "NoMsgSendType";
BA_DEF_ BO_  "GenMsgStartDelayTime" INT 0 100000;
BA_DEF_ BO_  "NmMessage" ENUM "No", "Yes";
BA_DEF_ BO_  "NmhMessage" ENUM "No", "Yes";
BA_DEF_ BO_  "MsgType" ENUM "Application", "NM ", "NMH", "TP2.0", "ISO-TP ", "BAP", "EID", "KS";
BA_DEF_ BO_  "VAGTP20_API" HEX 0 255;
BA_DEF_ BO_  "VAGTP20_DynConnection" ENUM "No", "Yes";
BA_DEF_ BO_  "VAGTP20_DynSetup" ENUM "No", "Yes";
BA_DEF_ BO_  "VAGTP20_StatConnection" ENUM "No", "Yes";
BA_DEF_ BO_  "CANFD_BRS" ENUM "0", "1";
BA_DEF_ BO_  "VFrameFormat" ENUM "StandardCAN", "ExtendedCAN", "reserved", "reserved", "reserved", "reserved", "reserved", "reserved", "reserved", "reserved", "reserved", "reserved", "reserved", "reserved", "StandardCAN_FD", "ExtendedCAN_FD";
BA_DEF_ SG_  "GenSigActiveRepetitions" INT -2147483648 2147483647;
BA_DEF_ SG_  "GenSigInactiveValue" INT -2147483648 2147483647;
BA_DEF_ SG_  "GenSigSendType" ENUM "Cyclic", "OnWrite", "OnWriteWithRepetition", "OnChange", "OnChangeWithRepetition", "IfActive", "IfActiveWithRepetition", "NoSigSendType", "OnChangeAndIfActive", "OnChangeAndIfActiveWithRepetition";
BA_DEF_ SG_  "GenSigStartValue" INT -2147483648 2147483647;
BA_DEF_ SG_  "NWM-WakeupAllowed" ENUM "No", "Yes";
BA_DEF_ SG_  "GenSigFuncType" ENUM "NoFunction", "MsgCounter", "CRC-8", "XOR", "XOR-2", "DatedBit", "SW-Kl15", "CHK", "Constant", "Protocol", "CRC-8-SAE_J1850";
BA_DEF_ SG_  "GenSigSwitchedByIgnition" ENUM "No", "Yes";
BA_DEF_ SG_  "Fehlerwert" HEX 0 2147483647;
BA_DEF_ SG_  "GenSigMissingSourceValue" HEX 0 2147483647;
BA_DEF_DEF_REL_  "GenSigTimeoutTime" 0;
BA_DEF_DEF_  "DiagRequest" "No";
BA_DEF_DEF_  "DiagResponse" "No";
BA_DEF_DEF_  "DiagState" "No";
BA_DEF_DEF_  "GenMsgChkConstant" 0;
BA_DEF_DEF_  "GenMsgCycleTime" 0;
BA_DEF_DEF_  "GenMsgCycleTimeFast" 0;
BA_DEF_DEF_  "GenMsgDelayTime" 0;
BA_DEF_DEF_  "GenMsgILSupport" "No";
BA_DEF_DEF_  "GenMsgNrOfRepetition" 0;
BA_DEF_DEF_  "GenMsgPDUConstants" "";
BA_DEF_DEF_  "GenMsgSendType" "NoMsgSendType";
BA_DEF_DEF_  "GenMsgStartDelayTime" 0;
BA_DEF_DEF_  "NmMessage" "No";
BA_DEF_DEF_  "NmhMessage" "No";
BA_DEF_DEF_  "MsgType" "Application";
BA_DEF_DEF_  "VAGTP20_API" 0;
BA_DEF_DEF_  "VAGTP20_DynConnection" "No";
BA_DEF_DEF_  "VAGTP20_DynSetup" "No";
BA_DEF_DEF_  "VAGTP20_StatConnection" "No";
BA_DEF_DEF_  "CANFD_BRS" "1";
BA_DEF_DEF_  "VFrameFormat" "StandardCAN";
BA_DEF_DEF_  "GenSigActiveRepetitions" 0;
BA_DEF_DEF_  "GenSigInactiveValue" 0;
BA_DEF_DEF_  "GenSigSendType" "NoSigSendType";
BA_DEF_DEF_  "GenSigStartValue" 0;
BA_DEF_DEF_  "NWM-WakeupAllowed" "No";
BA_DEF_DEF_  "GenSigFuncType" "NoFunction";
BA_DEF_DEF_  "GenSigSwitchedByIgnition" "Yes";
BA_DEF_DEF_  "Fehlerwert" 0;
BA_DEF_DEF_  "GenSigMissingSourceValue" 0;
BA_ "GenMsgCycleTime" BO_ 958 100;
BA_ "GenMsgDelayTime" BO_ 958 10;
BA_ "GenMsgILSupport" BO_ 958 1;
BA_ "GenMsgPDUConstants" BO_ 958 "0x1f,0x28,0xc6,0x85,0xe6,0xf8,0xb0,0x19,0x5b,0x64,0x35,0x21,0xe4,0xf7,0x9c,0x24";
BA_ "GenMsgSendType" BO_ 958 0;
BA_ "VFrameFormat" BO_ 958 14;
BA_ "GenMsgCycleTime" BO_ 1631 500;
BA_ "GenMsgILSupport" BO_ 1631 1;
BA_ "GenMsgSendType" BO_ 1631 0;
BA_ "VFrameFormat" BO_ 1631 14;
BA_ "GenMsgCycleTime" BO_ 1648 500;
BA_ "GenMsgDelayTime" BO_ 1648 20;
BA_ "GenMsgILSupport" BO_ 1648 1;
BA_ "GenMsgSendType" BO_ 1648 0;
BA_ "VFrameFormat" BO_ 1648 14;
BA_ "GenMsgCycleTime" BO_ 967 100;
BA_ "GenMsgILSupport" BO_ 967 1;
BA_ "GenMsgSendType" BO_ 967 0;
BA_ "VFrameFormat" BO_ 967 14;
BA_ "GenMsgCycleTime" BO_ 706 500;
BA_ "GenMsgDelayTime" BO_ 706 100;
BA_ "GenMsgILSupport" BO_ 706 1;
BA_ "GenMsgSendType" BO_ 706 0;
BA_ "VFrameFormat" BO_ 706 14;
BA_ "GenMsgCycleTime" BO_ 267 20;
BA_ "GenMsgILSupport" BO_ 267 1;
BA_ "GenMsgPDUConstants" BO_ 267 "0x77,0x5c,0xa0,0x89,0x4b,0x7c,0xbb,0xd6,0x1f,0x6c,0x4f,0xf6,0x20,0x2b,0x43,0xdd";
BA_ "GenMsgSendType" BO_ 267 0;
BA_ "VFrameFormat" BO_ 267 14;
BA_ "GenMsgCycleTime" BO_ 330 20;
BA_ "GenMsgILSupport" BO_ 330 1;
BA_ "GenMsgSendType" BO_ 330 0;
BA_ "VFrameFormat" BO_ 330 14;
BA_ "GenMsgCycleTime" BO_ 512 50;
BA_ "GenMsgILSupport" BO_ 512 1;
BA_ "GenMsgSendType" BO_ 512 0;
BA_ "VFrameFormat" BO_ 512 14;
BA_ "GenMsgCycleTime" BO_ 332 100;
BA_ "GenMsgDelayTime" BO_ 332 10;
BA_ "GenMsgILSupport" BO_ 332 1;
BA_ "GenMsgSendType" BO_ 332 0;
BA_ "VFrameFormat" BO_ 332 14;
BA_ "GenMsgCycleTime" BO_ 246 10;
BA_ "GenMsgILSupport" BO_ 246 1;
BA_ "GenMsgPDUConstants" BO_ 246 "0x89,0xd6,0xf6,0xdd,0xe7,0x74,0x0f,0xd2,0x26,0x5a,0x44,0x70,0xd5,0x67,0x79,0x3d";
BA_ "GenMsgSendType" BO_ 246 0;
BA_ "VFrameFormat" BO_ 246 14;
BA_ "GenMsgCycleTime" BO_ 190 10;
BA_ "GenMsgILSupport" BO_ 190 1;
BA_ "GenMsgPDUConstants" BO_ 190 "0x18,0x71,0x10,0x8d,0xd7,0xaa,0xb0,0x78,0xac,0x12,0xae,0x0c,0xdd,0xf1,0x85,0x68";
BA_ "GenMsgSendType" BO_ 190 0;
BA_ "VFrameFormat" BO_ 190 14;
BA_ "GenMsgCycleTime" BO_ 2463978666 100;
BA_ "GenMsgILSupport" BO_ 2463978666 1;
BA_ "GenMsgSendType" BO_ 2463978666 0;
BA_ "VFrameFormat" BO_ 2463978666 15;
BA_ "GenSigSendType" SG_ 958 MO_Aussp_Anlass 3;
BA_ "GenSigSwitchedByIgnition" SG_ 958 MO_Aussp_Anlass 0;
BA_ "GenSigSendType" SG_ 958 MO_BKV_Unterdruckwarnung 0;
BA_ "GenSigSwitchedByIgnition" SG_ 958 MO_BKV_Unterdruckwarnung 0;
BA_ "GenSigSendType" SG_ 958 MO_BLS 3;
BA_ "GenSigSwitchedByIgnition" SG_ 958 MO_BLS 0;
BA_ "GenSigSendType" SG_ 958 MO_BMS_NV_Anf_stuetzen 3;
BA_ "GenSigSwitchedByIgnition" SG_ 958 MO_BMS_NV_Anf_stuetzen 0;
BA_ "GenSigSendType" SG_ 958 MO_EKlKomLeiRed 0;
BA_ "GenSigSwitchedByIgnition" SG_ 958 MO_EKlKomLeiRed 0;
BA_ "GenSigSendType" SG_ 958 MO_Ext_E_Fahrt_aktiv 3;
BA_ "NWM-WakeupAllowed" SG_ 958 MO_Ext_E_Fahrt_aktiv 1;
BA_ "GenSigSwitchedByIgnition" SG_ 958 MO_Ext_E_Fahrt_aktiv 0;
BA_ "GenSigSendType" SG_ 958 MO_Fahrer_bremst 3;
BA_ "GenSigSwitchedByIgnition" SG_ 958 MO_Fahrer_bremst 0;
BA_ "GenSigSendType" SG_ 958 MO_FMAus_aktiv 3;
BA_ "GenSigSwitchedByIgnition" SG_ 958 MO_FMAus_aktiv 0;
BA_ "GenSigSendType" SG_ 958 MO_FMAus_Startvariante 3;
BA_ "GenSigSwitchedByIgnition" SG_ 958 MO_FMAus_Startvariante 0;
BA_ "GenSigSendType" SG_ 958 MO_Freig_Anlass 3;
BA_ "GenSigSwitchedByIgnition" SG_ 958 MO_Freig_Anlass 0;
BA_ "GenSigSendType" SG_ 958 MO_Freig_Reku 0;
BA_ "GenSigSwitchedByIgnition" SG_ 958 MO_Freig_Reku 0;
BA_ "GenSigSendType" SG_ 958 MO_Freigabe_Segeln 0;
BA_ "GenSigSwitchedByIgnition" SG_ 958 MO_Freigabe_Segeln 0;
BA_ "GenSigSendType" SG_ 958 MO_Gangposition 3;
BA_ "GenSigStartValue" SG_ 958 MO_Gangposition 14;
BA_ "GenSigSwitchedByIgnition" SG_ 958 MO_Gangposition 0;
BA_ "Fehlerwert" SG_ 958 MO_Gangposition 15;
BA_ "GenSigSendType" SG_ 958 MO_Handshake_STH 0;
BA_ "GenSigSwitchedByIgnition" SG_ 958 MO_Handshake_STH 0;
BA_ "GenSigSendType" SG_ 958 MO_HYB_Fahrbereitschaft 0;
BA_ "GenSigSwitchedByIgnition" SG_ 958 MO_HYB_Fahrbereitschaft 0;
BA_ "GenSigSendType" SG_ 958 MO_HYB_VM_aktiv 3;
BA_ "GenSigSwitchedByIgnition" SG_ 958 MO_HYB_VM_aktiv 0;
BA_ "GenSigSendType" SG_ 958 MO_Interlock 3;
BA_ "GenSigSwitchedByIgnition" SG_ 958 MO_Interlock 0;
BA_ "GenSigSendType" SG_ 958 MO_Kickdown 3;
BA_ "GenSigSwitchedByIgnition" SG_ 958 MO_Kickdown 0;
BA_ "GenSigSendType" SG_ 958 MO_Kl_50 3;
BA_ "GenSigSwitchedByIgnition" SG_ 958 MO_Kl_50 0;
BA_ "GenSigSendType" SG_ 958 MO_Kl_75 3;
BA_ "GenSigSwitchedByIgnition" SG_ 958 MO_Kl_75 0;
BA_ "GenSigSendType" SG_ 958 MO_Klima_Eingr 3;
BA_ "GenSigSwitchedByIgnition" SG_ 958 MO_Klima_Eingr 0;
BA_ "GenSigSendType" SG_ 958 MO_Konsistenz_Bremsped 3;
BA_ "GenSigSwitchedByIgnition" SG_ 958 MO_Konsistenz_Bremsped 0;
BA_ "GenSigSendType" SG_ 958 MO_Kuppl_schalter 3;
BA_ "GenSigSwitchedByIgnition" SG_ 958 MO_Kuppl_schalter 0;
BA_ "GenSigSendType" SG_ 958 MO_Motor_laeuft 3;
BA_ "GenSigSwitchedByIgnition" SG_ 958 MO_Motor_laeuft 0;
BA_ "GenSigSendType" SG_ 958 MO_PTC_Status 0;
BA_ "GenSigSwitchedByIgnition" SG_ 958 MO_PTC_Status 0;
BA_ "GenSigSendType" SG_ 958 MO_QBit_Fahrer_bremst 3;
BA_ "GenSigStartValue" SG_ 958 MO_QBit_Fahrer_bremst 1;
BA_ "GenSigSwitchedByIgnition" SG_ 958 MO_QBit_Fahrer_bremst 0;
BA_ "GenSigSendType" SG_ 958 MO_QBit_Gangposition 3;
BA_ "GenSigStartValue" SG_ 958 MO_QBit_Gangposition 1;
BA_ "GenSigSwitchedByIgnition" SG_ 958 MO_QBit_Gangposition 0;
BA_ "GenSigSendType" SG_ 958 MO_QBit_KL_75 3;
BA_ "GenSigStartValue" SG_ 958 MO_QBit_KL_75 1;
BA_ "GenSigSwitchedByIgnition" SG_ 958 MO_QBit_KL_75 0;
BA_ "GenSigSendType" SG_ 958 MO_Remotestart_Betrieb 3;
BA_ "GenSigSwitchedByIgnition" SG_ 958 MO_Remotestart_Betrieb 0;
BA_ "GenSigSendType" SG_ 958 MO_Remotestart_moeglich 0;
BA_ "GenSigSwitchedByIgnition" SG_ 958 MO_Remotestart_moeglich 0;
BA_ "GenSigSendType" SG_ 958 MO_Signalquelle_Gangposition 0;
BA_ "GenSigSwitchedByIgnition" SG_ 958 MO_Signalquelle_Gangposition 0;
BA_ "GenSigSendType" SG_ 958 MO_StartStopp_Fahrerwunsch 0;
BA_ "GenSigSwitchedByIgnition" SG_ 958 MO_StartStopp_Fahrerwunsch 0;
BA_ "GenSigSendType" SG_ 958 MO_StartStopp_Motorstopp 3;
BA_ "GenSigSwitchedByIgnition" SG_ 958 MO_StartStopp_Motorstopp 0;
BA_ "GenSigSendType" SG_ 958 MO_StartStopp_Status 0;
BA_ "GenSigSwitchedByIgnition" SG_ 958 MO_StartStopp_Status 0;
BA_ "GenSigSendType" SG_ 958 MO_StartStopp_Wiederstart 3;
BA_ "GenSigSwitchedByIgnition" SG_ 958 MO_StartStopp_Wiederstart 0;
BA_ "GenSigSendType" SG_ 958 MO_StartVorauss_erfuellt 3;
BA_ "GenSigStartValue" SG_ 958 MO_StartVorauss_erfuellt 1;
BA_ "GenSigSwitchedByIgnition" SG_ 958 MO_StartVorauss_erfuellt 0;
BA_ "GenSigSendType" SG_ 958 MO_Timeout_ESP 3;
BA_ "GenSigSwitchedByIgnition" SG_ 958 MO_Timeout_ESP 0;
BA_ "GenSigSendType" SG_ 958 MO_Zylinderabschaltung 3;
BA_ "GenSigSwitchedByIgnition" SG_ 958 MO_Zylinderabschaltung 0;
BA_ "GenSigSendType" SG_ 958 Motor_14_BZ 0;
BA_ "GenSigFuncType" SG_ 958 Motor_14_BZ 1;
BA_ "GenSigSwitchedByIgnition" SG_ 958 Motor_14_BZ 0;
BA_ "GenSigSendType" SG_ 958 Motor_14_CRC 0;
BA_ "GenSigFuncType" SG_ 958 Motor_14_CRC 2;
BA_ "GenSigSwitchedByIgnition" SG_ 958 Motor_14_CRC 0;
BA_ "GenSigSendType" SG_ 1631 MO_DPF_reg 0;
BA_ "GenSigSwitchedByIgnition" SG_ 1631 MO_DPF_reg 0;
BA_ "GenSigSendType" SG_ 1631 MO_Energieinhalt_BMS 0;
BA_ "GenSigStartValue" SG_ 1631 MO_Energieinhalt_BMS 4094;
BA_ "GenSigSwitchedByIgnition" SG_ 1631 MO_Energieinhalt_BMS 0;
BA_ "Fehlerwert" SG_ 1631 MO_Energieinhalt_BMS 4095;
BA_ "GenSigSendType" SG_ 1631 MO_Heizstrom_EKAT 0;
BA_ "GenSigSwitchedByIgnition" SG_ 1631 MO_Heizstrom_EKAT 0;
BA_ "Fehlerwert" SG_ 1631 MO_Heizstrom_EKAT 127;
BA_ "GenSigSendType" SG_ 1631 MO_Heizstrom_SCR 0;
BA_ "GenSigSwitchedByIgnition" SG_ 1631 MO_Heizstrom_SCR 0;
BA_ "Fehlerwert" SG_ 1631 MO_Heizstrom_SCR 63;
BA_ "GenSigSendType" SG_ 1631 MO_P_Generator_ungefiltert_Anf 0;
BA_ "GenSigSwitchedByIgnition" SG_ 1631 MO_P_Generator_ungefiltert_Anf 0;
BA_ "GenSigSendType" SG_ 1631 MO_SpannungsAnf_02 0;
BA_ "GenSigSwitchedByIgnition" SG_ 1631 MO_SpannungsAnf_02 0;
BA_ "GenSigSendType" SG_ 1631 TSK_Fahrzeugmasse_02 0;
BA_ "GenSigSwitchedByIgnition" SG_ 1631 TSK_Fahrzeugmasse_02 0;
BA_ "Fehlerwert" SG_ 1631 TSK_Fahrzeugmasse_02 255;
BA_ "GenSigSendType" SG_ 1631 TSK_Getriebeinfo 0;
BA_ "GenSigSwitchedByIgnition" SG_ 1631 TSK_Getriebeinfo 0;
BA_ "GenSigSendType" SG_ 1631 TSK_Grundmasse 0;
BA_ "GenSigSwitchedByIgnition" SG_ 1631 TSK_Grundmasse 0;
BA_ "GenSigSendType" SG_ 1631 TSK_QBit_Fahrzeugmasse 0;
BA_ "GenSigStartValue" SG_ 1631 TSK_QBit_Fahrzeugmasse 1;
BA_ "GenSigSwitchedByIgnition" SG_ 1631 TSK_QBit_Fahrzeugmasse 0;
BA_ "GenSigSendType" SG_ 1631 TSK_QBit_Steigung 0;
BA_ "GenSigStartValue" SG_ 1631 TSK_QBit_Steigung 1;
BA_ "GenSigSwitchedByIgnition" SG_ 1631 TSK_QBit_Steigung 0;
BA_ "GenSigSendType" SG_ 1631 TSK_Steigung_02 0;
BA_ "GenSigSwitchedByIgnition" SG_ 1631 TSK_Steigung_02 0;
BA_ "Fehlerwert" SG_ 1631 TSK_Steigung_02 255;
BA_ "GenSigSendType" SG_ 1648 MO1_Freigabe_Info_WFS 3;
BA_ "GenSigSwitchedByIgnition" SG_ 1648 MO1_Freigabe_Info_WFS 0;
BA_ "GenSigSendType" SG_ 1648 MO1_Freigabe_Verfallsinfo_WFS 3;
BA_ "GenSigSwitchedByIgnition" SG_ 1648 MO1_Freigabe_Verfallsinfo_WFS 0;
BA_ "GenSigSendType" SG_ 1648 MO1_Sperr_Info_WFS 3;
BA_ "GenSigSwitchedByIgnition" SG_ 1648 MO1_Sperr_Info_WFS 0;
BA_ "GenSigSendType" SG_ 1648 MO_Abstellzeit 0;
BA_ "GenSigStartValue" SG_ 1648 MO_Abstellzeit 254;
BA_ "GenSigSwitchedByIgnition" SG_ 1648 MO_Abstellzeit 0;
BA_ "GenSigSendType" SG_ 1648 MO_Abstellzeit_Status 0;
BA_ "GenSigSwitchedByIgnition" SG_ 1648 MO_Abstellzeit_Status 0;
BA_ "GenSigSendType" SG_ 1648 MO_ANC_Kennfeld_Anf 3;
BA_ "GenSigSwitchedByIgnition" SG_ 1648 MO_ANC_Kennfeld_Anf 0;
BA_ "GenSigSendType" SG_ 1648 MO_Anzahl_Abgesch_Zyl 3;
BA_ "GenSigSwitchedByIgnition" SG_ 1648 MO_Anzahl_Abgesch_Zyl 0;
BA_ "GenSigSendType" SG_ 1648 MO_Bremslicht_Reku 3;
BA_ "GenSigSwitchedByIgnition" SG_ 1648 MO_Bremslicht_Reku 0;
BA_ "GenSigSendType" SG_ 1648 MO_Drehzahl_Warnung 0;
BA_ "GenSigSwitchedByIgnition" SG_ 1648 MO_Drehzahl_Warnung 0;
BA_ "GenSigSendType" SG_ 1648 MO_EPCL 3;
BA_ "GenSigSwitchedByIgnition" SG_ 1648 MO_EPCL 0;
BA_ "GenSigSendType" SG_ 1648 MO_Ethanol_BS_Texte 0;
BA_ "GenSigSwitchedByIgnition" SG_ 1648 MO_Ethanol_BS_Texte 0;
BA_ "GenSigSendType" SG_ 1648 MO_Fahrzeugtyp 0;
BA_ "GenSigFuncType" SG_ 1648 MO_Fahrzeugtyp 8;
BA_ "GenSigSwitchedByIgnition" SG_ 1648 MO_Fahrzeugtyp 0;
BA_ "GenSigSendType" SG_ 1648 MO_Fehler_Zylabsch 0;
BA_ "GenSigSwitchedByIgnition" SG_ 1648 MO_Fehler_Zylabsch 0;
BA_ "GenSigSendType" SG_ 1648 MO_Hybrid_StartStopp_LED 3;
BA_ "GenSigSwitchedByIgnition" SG_ 1648 MO_Hybrid_StartStopp_LED 0;
BA_ "GenSigSendType" SG_ 1648 MO_max_Ladedruck 0;
BA_ "GenSigFuncType" SG_ 1648 MO_max_Ladedruck 8;
BA_ "GenSigSwitchedByIgnition" SG_ 1648 MO_max_Ladedruck 0;
BA_ "GenSigSendType" SG_ 1648 MO_NMAX_Schaltanzeige 3;
BA_ "GenSigSwitchedByIgnition" SG_ 1648 MO_NMAX_Schaltanzeige 0;
BA_ "GenSigSendType" SG_ 1648 MO_obere_Drehzahlgrenze 0;
BA_ "GenSigSwitchedByIgnition" SG_ 1648 MO_obere_Drehzahlgrenze 0;
BA_ "GenSigSendType" SG_ 1648 MO_StartStopp_PopUp 3;
BA_ "GenSigSwitchedByIgnition" SG_ 1648 MO_StartStopp_PopUp 0;
BA_ "GenSigSendType" SG_ 1648 MO_Zylabsch_Texte 0;
BA_ "GenSigSwitchedByIgnition" SG_ 1648 MO_Zylabsch_Texte 0;
BA_ "GenSigSendType" SG_ 1648 MO_Zylabsch_Texte_02 3;
BA_ "GenSigSwitchedByIgnition" SG_ 1648 MO_Zylabsch_Texte_02 0;
BA_ "GenSigSendType" SG_ 967 MO_E_Mode 0;
BA_ "GenSigSwitchedByIgnition" SG_ 967 MO_E_Mode 0;
BA_ "GenSigSendType" SG_ 967 MO_E_Texte 0;
BA_ "GenSigSwitchedByIgnition" SG_ 967 MO_E_Texte 0;
BA_ "GenSigSendType" SG_ 967 MO_E_Warnungen 0;
BA_ "GenSigSwitchedByIgnition" SG_ 967 MO_E_Warnungen 0;
BA_ "GenSigSendType" SG_ 967 MO_EFLEX_Lampe 0;
BA_ "GenSigSwitchedByIgnition" SG_ 967 MO_EFLEX_Lampe 0;
BA_ "GenSigSendType" SG_ 967 MO_Heissleuchte 0;
BA_ "GenSigSwitchedByIgnition" SG_ 967 MO_Heissleuchte 0;
BA_ "GenSigSendType" SG_ 967 MO_ITM_Warnung_Pumpe 0;
BA_ "GenSigSwitchedByIgnition" SG_ 967 MO_ITM_Warnung_Pumpe 0;
BA_ "GenSigSendType" SG_ 967 MO_KJS_nicht_bereit 0;
BA_ "GenSigSwitchedByIgnition" SG_ 967 MO_KJS_nicht_bereit 0;
BA_ "Fehlerwert" SG_ 967 MO_KJS_nicht_bereit 1;
BA_ "GenSigStartValue" SG_ 967 MO_Kuehlerluefter_1 126;
BA_ "GenSigSwitchedByIgnition" SG_ 967 MO_Kuehlerluefter_1 0;
BA_ "Fehlerwert" SG_ 967 MO_Kuehlerluefter_1 127;
BA_ "GenSigStartValue" SG_ 967 MO_Kuehlerluefter_2 126;
BA_ "GenSigSwitchedByIgnition" SG_ 967 MO_Kuehlerluefter_2 0;
BA_ "Fehlerwert" SG_ 967 MO_Kuehlerluefter_2 127;
BA_ "GenSigSendType" SG_ 967 MO_Kuehlerluefter_MUX 0;
BA_ "GenSigSwitchedByIgnition" SG_ 967 MO_Kuehlerluefter_MUX 0;
BA_ "GenSigSendType" SG_ 967 MO_OBD2_Lampe 0;
BA_ "GenSigSwitchedByIgnition" SG_ 967 MO_OBD2_Lampe 0;
BA_ "GenSigSendType" SG_ 967 MO_Oelwarnung_max 0;
BA_ "GenSigSwitchedByIgnition" SG_ 967 MO_Oelwarnung_max 0;
BA_ "GenSigSendType" SG_ 967 MO_Partikel_Lampe 0;
BA_ "GenSigSwitchedByIgnition" SG_ 967 MO_Partikel_Lampe 0;
BA_ "GenSigSendType" SG_ 967 MO_RedFahrleistung_Lampe 0;
BA_ "GenSigSwitchedByIgnition" SG_ 967 MO_RedFahrleistung_Lampe 0;
BA_ "GenSigSendType" SG_ 967 MO_Systemlampe 0;
BA_ "GenSigSwitchedByIgnition" SG_ 967 MO_Systemlampe 0;
BA_ "GenSigSendType" SG_ 967 MO_Tankdeckel_Lampe 0;
BA_ "GenSigSwitchedByIgnition" SG_ 967 MO_Tankdeckel_Lampe 0;
BA_ "GenSigSendType" SG_ 967 MO_Text_Motorstart 0;
BA_ "GenSigSwitchedByIgnition" SG_ 967 MO_Text_Motorstart 0;
BA_ "GenSigSendType" SG_ 967 MO_Text_Partikelfil_Reg 0;
BA_ "GenSigSwitchedByIgnition" SG_ 967 MO_Text_Partikelfil_Reg 0;
BA_ "GenSigSendType" SG_ 967 MO_Text_Tankdeckelwarn 0;
BA_ "GenSigSwitchedByIgnition" SG_ 967 MO_Text_Tankdeckelwarn 0;
BA_ "GenSigSendType" SG_ 967 MO_Vorglueh_Lampe 0;
BA_ "GenSigSwitchedByIgnition" SG_ 967 MO_Vorglueh_Lampe 0;
BA_ "GenSigSendType" SG_ 967 MO_Zustand_HWP 0;
BA_ "GenSigStartValue" SG_ 967 MO_Zustand_HWP 1;
BA_ "GenSigSwitchedByIgnition" SG_ 967 MO_Zustand_HWP 0;
BA_ "GenSigSendType" SG_ 967 OLEV_Oelstand_nicht_vorhanden 0;
BA_ "GenSigSwitchedByIgnition" SG_ 967 OLEV_Oelstand_nicht_vorhanden 0;
BA_ "GenSigSendType" SG_ 967 OLEV_Systemstoerung 0;
BA_ "GenSigSwitchedByIgnition" SG_ 967 OLEV_Systemstoerung 0;
BA_ "GenSigSendType" SG_ 967 WIV_Anzeige_aktiv 0;
BA_ "GenSigSwitchedByIgnition" SG_ 967 WIV_Anzeige_aktiv 0;
BA_ "GenSigSendType" SG_ 967 WIV_laufender_Motor 0;
BA_ "GenSigSwitchedByIgnition" SG_ 967 WIV_laufender_Motor 0;
BA_ "GenSigSendType" SG_ 967 WIV_nachfuellanzeige_ein 0;
BA_ "GenSigSwitchedByIgnition" SG_ 967 WIV_nachfuellanzeige_ein 0;
BA_ "GenSigSendType" SG_ 967 WIV_nicht_betriebswarm 0;
BA_ "GenSigSwitchedByIgnition" SG_ 967 WIV_nicht_betriebswarm 0;
BA_ "GenSigSendType" SG_ 967 WIV_Oeldr_Warn_Motor 0;
BA_ "GenSigSwitchedByIgnition" SG_ 967 WIV_Oeldr_Warn_Motor 0;
BA_ "GenSigSendType" SG_ 967 WIV_Oeldyn_avl 0;
BA_ "GenSigSwitchedByIgnition" SG_ 967 WIV_Oeldyn_avl 0;
BA_ "GenSigSendType" SG_ 967 WIV_Oelmenge 0;
BA_ "GenSigSwitchedByIgnition" SG_ 967 WIV_Oelmenge 0;
BA_ "GenSigSendType" SG_ 967 WIV_Oelmin_Warn 0;
BA_ "GenSigSwitchedByIgnition" SG_ 967 WIV_Oelmin_Warn 0;
BA_ "GenSigSendType" SG_ 967 WIV_Oelstand 0;
BA_ "GenSigSwitchedByIgnition" SG_ 967 WIV_Oelstand 0;
BA_ "GenSigSendType" SG_ 967 WIV_Oelstand_nicht_vorhanden 0;
BA_ "GenSigSwitchedByIgnition" SG_ 967 WIV_Oelstand_nicht_vorhanden 0;
BA_ "GenSigSendType" SG_ 967 WIV_Oelsystem_aktiv 0;
BA_ "GenSigSwitchedByIgnition" SG_ 967 WIV_Oelsystem_aktiv 0;
BA_ "GenSigSendType" SG_ 967 WIV_Schieflage 0;
BA_ "GenSigSwitchedByIgnition" SG_ 967 WIV_Schieflage 0;
BA_ "GenSigSendType" SG_ 967 WIV_Sensorfehler 0;
BA_ "GenSigSwitchedByIgnition" SG_ 967 WIV_Sensorfehler 0;
BA_ "GenSigSendType" SG_ 967 WIV_Ueberfuell_deaktiv 0;
BA_ "GenSigSwitchedByIgnition" SG_ 967 WIV_Ueberfuell_deaktiv 0;
BA_ "GenSigSendType" SG_ 967 WIV_Ueberfuell_Warn 0;
BA_ "GenSigSwitchedByIgnition" SG_ 967 WIV_Ueberfuell_Warn 0;
BA_ "GenSigSendType" SG_ 967 WIV_Unterfuell_Warn 0;
BA_ "GenSigSwitchedByIgnition" SG_ 967 WIV_Unterfuell_Warn 0;
BA_ "GenSigSendType" SG_ 706 FDR_Warnung_ALR 3;
BA_ "GenSigSwitchedByIgnition" SG_ 706 FDR_Warnung_ALR 0;
BA_ "GenSigSendType" SG_ 706 MO_ADR_Status 3;
BA_ "GenSigSwitchedByIgnition" SG_ 706 MO_ADR_Status 0;
BA_ "GenSigSendType" SG_ 706 MO_AGA_Sound_Texte 3;
BA_ "GenSigSwitchedByIgnition" SG_ 706 MO_AGA_Sound_Texte 0;
BA_ "GenSigSendType" SG_ 706 MO_Anz_Kuehlerluefter 0;
BA_ "GenSigSwitchedByIgnition" SG_ 706 MO_Anz_Kuehlerluefter 0;
BA_ "GenSigSendType" SG_ 706 MO_Anzeige_FMAus_Text 3;
BA_ "GenSigSwitchedByIgnition" SG_ 706 MO_Anzeige_FMAus_Text 0;
BA_ "GenSigSendType" SG_ 706 MO_Anzeige_StSt_Symbol 3;
BA_ "GenSigSwitchedByIgnition" SG_ 706 MO_Anzeige_StSt_Symbol 0;
BA_ "GenSigSendType" SG_ 706 MO_Anzeige_StSt_Text 3;
BA_ "GenSigSwitchedByIgnition" SG_ 706 MO_Anzeige_StSt_Text 0;
BA_ "GenSigSendType" SG_ 706 MO_Rekuperationsstufe 3;
BA_ "GenSigStartValue" SG_ 706 MO_Rekuperationsstufe 7;
BA_ "GenSigSwitchedByIgnition" SG_ 706 MO_Rekuperationsstufe 0;
BA_ "GenSigSendType" SG_ 706 PEA_Texte 3;
BA_ "GenSigSwitchedByIgnition" SG_ 706 PEA_Texte 0;
BA_ "GenSigSendType" SG_ 706 TSK_Einheit_vMax_FahrerInfo 0;
BA_ "GenSigSwitchedByIgnition" SG_ 706 TSK_Einheit_vMax_FahrerInfo 0;
BA_ "GenSigSendType" SG_ 706 TSK_Status_vMax_FahrerInfo 0;
BA_ "GenSigSwitchedByIgnition" SG_ 706 TSK_Status_vMax_FahrerInfo 0;
BA_ "GenSigSendType" SG_ 706 TSK_Ueberstimmt_vMax_FahrerInfo 3;
BA_ "GenSigSwitchedByIgnition" SG_ 706 TSK_Ueberstimmt_vMax_FahrerInfo 0;
BA_ "GenSigSendType" SG_ 706 TSK_vMax_FahrerInfo 0;
BA_ "GenSigSwitchedByIgnition" SG_ 706 TSK_vMax_FahrerInfo 0;
BA_ "GenSigSendType" SG_ 267 GRA_KuFu_aktiv 0;
BA_ "GenSigSwitchedByIgnition" SG_ 267 GRA_KuFu_aktiv 0;
BA_ "GenSigSendType" SG_ 267 LIM_KuFu_aktiv 0;
BA_ "GenSigSwitchedByIgnition" SG_ 267 LIM_KuFu_aktiv 0;
BA_ "GenSigSendType" SG_ 267 MO_Entkopplung_Sollschlupf 0;
BA_ "GenSigStartValue" SG_ 267 MO_Entkopplung_Sollschlupf 126;
BA_ "GenSigSwitchedByIgnition" SG_ 267 MO_Entkopplung_Sollschlupf 0;
BA_ "GenSigSendType" SG_ 267 MO_Fahrpedalgradient 0;
BA_ "GenSigSwitchedByIgnition" SG_ 267 MO_Fahrpedalgradient 0;
BA_ "Fehlerwert" SG_ 267 MO_Fahrpedalgradient 255;
BA_ "GenSigSendType" SG_ 267 MO_Fahrpedalrohwert_01 0;
BA_ "GenSigSwitchedByIgnition" SG_ 267 MO_Fahrpedalrohwert_01 0;
BA_ "Fehlerwert" SG_ 267 MO_Fahrpedalrohwert_01 255;
BA_ "GenSigSendType" SG_ 267 MO_Moment_im_Leerlauf 0;
BA_ "GenSigSwitchedByIgnition" SG_ 267 MO_Moment_im_Leerlauf 0;
BA_ "GenSigSendType" SG_ 267 MO_QBit_Fahrpedalwerte_01 0;
BA_ "GenSigStartValue" SG_ 267 MO_QBit_Fahrpedalwerte_01 1;
BA_ "GenSigSwitchedByIgnition" SG_ 267 MO_QBit_Fahrpedalwerte_01 0;
BA_ "GenSigSendType" SG_ 267 MO_rel_Saugrohrdruck 0;
BA_ "GenSigSwitchedByIgnition" SG_ 267 MO_rel_Saugrohrdruck 0;
BA_ "Fehlerwert" SG_ 267 MO_rel_Saugrohrdruck 63;
BA_ "GenSigSendType" SG_ 267 MO_rel_Saugrohrdruck_gem_err 0;
BA_ "GenSigSwitchedByIgnition" SG_ 267 MO_rel_Saugrohrdruck_gem_err 0;
BA_ "GenSigSendType" SG_ 267 MO_Schubabschaltung 0;
BA_ "GenSigSwitchedByIgnition" SG_ 267 MO_Schubabschaltung 0;
BA_ "GenSigSendType" SG_ 267 MO_Sig_Fahrpedalgradient 0;
BA_ "GenSigSwitchedByIgnition" SG_ 267 MO_Sig_Fahrpedalgradient 0;
BA_ "GenSigSendType" SG_ 267 MO_Solldrehz_Leerlauf 0;
BA_ "GenSigSwitchedByIgnition" SG_ 267 MO_Solldrehz_Leerlauf 0;
BA_ "GenSigSendType" SG_ 267 MO_Status_MaxDrzEingriff 0;
BA_ "GenSigSwitchedByIgnition" SG_ 267 MO_Status_MaxDrzEingriff 0;
BA_ "GenSigSendType" SG_ 267 MO_Status_MaxDrzEingriff_sek 0;
BA_ "GenSigSwitchedByIgnition" SG_ 267 MO_Status_MaxDrzEingriff_sek 0;
BA_ "GenSigSendType" SG_ 267 MO_Status_MinDrzEingriff 0;
BA_ "GenSigSwitchedByIgnition" SG_ 267 MO_Status_MinDrzEingriff 0;
BA_ "GenSigSendType" SG_ 267 MO_Status_MinDrzEingriff_sek 0;
BA_ "GenSigSwitchedByIgnition" SG_ 267 MO_Status_MinDrzEingriff_sek 0;
BA_ "GenSigSendType" SG_ 267 MO_temporaere_Fahrerabwesenheit 0;
BA_ "GenSigSwitchedByIgnition" SG_ 267 MO_temporaere_Fahrerabwesenheit 0;
BA_ "GenSigSendType" SG_ 267 Motor_51_BZ 0;
BA_ "GenSigFuncType" SG_ 267 Motor_51_BZ 1;
BA_ "GenSigSwitchedByIgnition" SG_ 267 Motor_51_BZ 0;
BA_ "GenSigSendType" SG_ 267 Motor_51_CRC 0;
BA_ "GenSigFuncType" SG_ 267 Motor_51_CRC 2;
BA_ "GenSigSwitchedByIgnition" SG_ 267 Motor_51_CRC 0;
BA_ "GenSigSendType" SG_ 267 TSK_a_Soll_gradientenbegrenzt 0;
BA_ "GenSigStartValue" SG_ 267 TSK_a_Soll_gradientenbegrenzt 127;
BA_ "GenSigSwitchedByIgnition" SG_ 267 TSK_a_Soll_gradientenbegrenzt 0;
BA_ "GenSigSendType" SG_ 267 TSK_ax_Getriebe_02 0;
BA_ "GenSigStartValue" SG_ 267 TSK_ax_Getriebe_02 511;
BA_ "GenSigSwitchedByIgnition" SG_ 267 TSK_ax_Getriebe_02 0;
BA_ "GenSigSendType" SG_ 267 TSK_Freig_Verzoeg_Anf 0;
BA_ "GenSigSwitchedByIgnition" SG_ 267 TSK_Freig_Verzoeg_Anf 0;
BA_ "GenSigSendType" SG_ 267 TSK_Freig_WU 0;
BA_ "GenSigSwitchedByIgnition" SG_ 267 TSK_Freig_WU 0;
BA_ "GenSigSendType" SG_ 267 TSK_Hauptschalter_GRA_ACC 0;
BA_ "GenSigSwitchedByIgnition" SG_ 267 TSK_Hauptschalter_GRA_ACC 0;
BA_ "Fehlerwert" SG_ 267 TSK_Hauptschalter_GRA_ACC 3;
BA_ "GenSigSendType" SG_ 267 TSK_Limiter_ausgewaehlt 0;
BA_ "GenSigSwitchedByIgnition" SG_ 267 TSK_Limiter_ausgewaehlt 0;
BA_ "GenSigSendType" SG_ 267 TSK_Radbremsmom 0;
BA_ "GenSigSwitchedByIgnition" SG_ 267 TSK_Radbremsmom 0;
BA_ "GenSigSendType" SG_ 267 TSK_SRBM_Anf_ASIL 0;
BA_ "GenSigSwitchedByIgnition" SG_ 267 TSK_SRBM_Anf_ASIL 0;
BA_ "GenSigSendType" SG_ 267 TSK_SRBM_max_Gradient 0;
BA_ "GenSigStartValue" SG_ 267 TSK_SRBM_max_Gradient 126;
BA_ "GenSigSwitchedByIgnition" SG_ 267 TSK_SRBM_max_Gradient 0;
BA_ "Fehlerwert" SG_ 267 TSK_SRBM_max_Gradient 127;
BA_ "GenSigSendType" SG_ 267 TSK_Standby_Anf_ESP 0;
BA_ "GenSigSwitchedByIgnition" SG_ 267 TSK_Standby_Anf_ESP 0;
BA_ "GenSigSendType" SG_ 267 TSK_Status 0;
BA_ "GenSigStartValue" SG_ 267 TSK_Status 1;
BA_ "GenSigSwitchedByIgnition" SG_ 267 TSK_Status 0;
BA_ "GenSigSendType" SG_ 267 TSK_v_Begrenzung_aktiv 0;
BA_ "GenSigSwitchedByIgnition" SG_ 267 TSK_v_Begrenzung_aktiv 0;
BA_ "GenSigSendType" SG_ 267 TSK_Wunsch_Uebersetz 0;
BA_ "GenSigSwitchedByIgnition" SG_ 267 TSK_Wunsch_Uebersetz 0;
BA_ "GenSigSendType" SG_ 267 TSK_zul_Regelabw 0;
BA_ "GenSigSwitchedByIgnition" SG_ 267 TSK_zul_Regelabw 0;
BA_ "GenSigSendType" SG_ 267 TSK_Zwangszusch_ESP 0;
BA_ "GenSigSwitchedByIgnition" SG_ 267 TSK_Zwangszusch_ESP 0;
BA_ "GenSigSendType" SG_ 330 Ladezustand_02 0;
BA_ "GenSigStartValue" SG_ 330 Ladezustand_02 254;
BA_ "GenSigSwitchedByIgnition" SG_ 330 Ladezustand_02 0;
BA_ "Fehlerwert" SG_ 330 Ladezustand_02 255;
BA_ "GenSigSendType" SG_ 330 MO_Anzeige_Drehmoment 0;
BA_ "GenSigSwitchedByIgnition" SG_ 330 MO_Anzeige_Drehmoment 0;
BA_ "Fehlerwert" SG_ 330 MO_Anzeige_Drehmoment 2047;
BA_ "GenSigSendType" SG_ 330 MO_Anzeige_Leistung 0;
BA_ "GenSigSwitchedByIgnition" SG_ 330 MO_Anzeige_Leistung 0;
BA_ "Fehlerwert" SG_ 330 MO_Anzeige_Leistung 2047;
BA_ "GenSigSendType" SG_ 330 MO_Anzeige_Verbr_Einheit 0;
BA_ "GenSigSwitchedByIgnition" SG_ 330 MO_Anzeige_Verbr_Einheit 0;
BA_ "GenSigSendType" SG_ 330 MO_Anzeigedrehz 0;
BA_ "GenSigSwitchedByIgnition" SG_ 330 MO_Anzeigedrehz 0;
BA_ "GenSigSendType" SG_ 330 MO_Effizienzmodus 0;
BA_ "GenSigSwitchedByIgnition" SG_ 330 MO_Effizienzmodus 0;
BA_ "GenSigSendType" SG_ 330 MO_ePerformance 0;
BA_ "GenSigSwitchedByIgnition" SG_ 330 MO_ePerformance 0;
BA_ "Fehlerwert" SG_ 330 MO_ePerformance 255;
BA_ "GenSigSendType" SG_ 330 MO_ePowermeter 0;
BA_ "GenSigSwitchedByIgnition" SG_ 330 MO_ePowermeter 0;
BA_ "GenSigSendType" SG_ 330 MO_Fehler_Oeldrucksensor 0;
BA_ "GenSigSwitchedByIgnition" SG_ 330 MO_Fehler_Oeldrucksensor 0;
BA_ "Fehlerwert" SG_ 330 MO_Fehler_Oeldrucksensor 1;
BA_ "GenSigSendType" SG_ 330 MO_Hochschaltdrehz 0;
BA_ "GenSigSwitchedByIgnition" SG_ 330 MO_Hochschaltdrehz 0;
BA_ "Fehlerwert" SG_ 330 MO_Hochschaltdrehz 4095;
BA_ "GenSigSendType" SG_ 330 MO_Istgang 0;
BA_ "GenSigSwitchedByIgnition" SG_ 330 MO_Istgang 0;
BA_ "GenSigSendType" SG_ 330 MO_KVS 0;
BA_ "GenSigSwitchedByIgnition" SG_ 330 MO_KVS 0;
BA_ "GenSigSendType" SG_ 330 MO_KVS_Ueberlauf 0;
BA_ "GenSigSwitchedByIgnition" SG_ 330 MO_KVS_Ueberlauf 0;
BA_ "GenSigSendType" SG_ 330 MO_Ladedruck 0;
BA_ "GenSigSwitchedByIgnition" SG_ 330 MO_Ladedruck 0;
BA_ "Fehlerwert" SG_ 330 MO_Ladedruck 511;
BA_ "GenSigSendType" SG_ 330 MO_Oeldruck 0;
BA_ "GenSigStartValue" SG_ 330 MO_Oeldruck 254;
BA_ "GenSigSwitchedByIgnition" SG_ 330 MO_Oeldruck 0;
BA_ "Fehlerwert" SG_ 330 MO_Oeldruck 255;
BA_ "GenSigSendType" SG_ 330 MO_Powermeter 0;
BA_ "GenSigStartValue" SG_ 330 MO_Powermeter 4093;
BA_ "GenSigSwitchedByIgnition" SG_ 330 MO_Powermeter 0;
BA_ "GenSigSendType" SG_ 330 MO_Powermeter_Elm_02 0;
BA_ "GenSigStartValue" SG_ 330 MO_Powermeter_Elm_02 4094;
BA_ "GenSigSwitchedByIgnition" SG_ 330 MO_Powermeter_Elm_02 0;
BA_ "GenSigSendType" SG_ 330 MO_rel_Ladedruck 0;
BA_ "GenSigSwitchedByIgnition" SG_ 330 MO_rel_Ladedruck 0;
BA_ "Fehlerwert" SG_ 330 MO_rel_Ladedruck 255;
BA_ "GenSigSendType" SG_ 330 MO_Schaltblitz_Anz 0;
BA_ "GenSigStartValue" SG_ 330 MO_Schaltblitz_Anz 126;
BA_ "GenSigSwitchedByIgnition" SG_ 330 MO_Schaltblitz_Anz 0;
BA_ "Fehlerwert" SG_ 330 MO_Schaltblitz_Anz 127;
BA_ "GenSigSendType" SG_ 330 MO_Schaltempf_verfbar 0;
BA_ "GenSigSwitchedByIgnition" SG_ 330 MO_Schaltempf_verfbar 0;
BA_ "GenSigSendType" SG_ 330 MO_Sollgang 0;
BA_ "GenSigSwitchedByIgnition" SG_ 330 MO_Sollgang 0;
BA_ "GenSigSendType" SG_ 330 MO_Zust_Antrieb 0;
BA_ "GenSigSwitchedByIgnition" SG_ 330 MO_Zust_Antrieb 0;
BA_ "GenSigSendType" SG_ 330 MO_Zust_Betriebsstrategie 0;
BA_ "GenSigSwitchedByIgnition" SG_ 330 MO_Zust_Betriebsstrategie 0;
BA_ "GenSigSendType" SG_ 512 MO_Antriebsstrang_Warnung_HS 0;
BA_ "GenSigSwitchedByIgnition" SG_ 512 MO_Antriebsstrang_Warnung_HS 0;
BA_ "GenSigSendType" SG_ 512 MO_Anzeige_Betriebsmodus 0;
BA_ "GenSigSwitchedByIgnition" SG_ 512 MO_Anzeige_Betriebsmodus 0;
BA_ "GenSigSendType" SG_ 512 MO_Anzeige_Fahrbereitschaft 0;
BA_ "GenSigSwitchedByIgnition" SG_ 512 MO_Anzeige_Fahrbereitschaft 0;
BA_ "GenSigSendType" SG_ 512 MO_Anzeige_Rekuperation 0;
BA_ "GenSigSwitchedByIgnition" SG_ 512 MO_Anzeige_Rekuperation 0;
BA_ "GenSigSendType" SG_ 512 MO_Anzeige_Verbrauch_oE 0;
BA_ "GenSigSwitchedByIgnition" SG_ 512 MO_Anzeige_Verbrauch_oE 0;
BA_ "GenSigSendType" SG_ 512 MO_Boost_aktiv 0;
BA_ "GenSigSwitchedByIgnition" SG_ 512 MO_Boost_aktiv 0;
BA_ "GenSigSendType" SG_ 512 MO_Boost_verfuegbar 0;
BA_ "GenSigSwitchedByIgnition" SG_ 512 MO_Boost_verfuegbar 0;
BA_ "Fehlerwert" SG_ 512 MO_Boost_verfuegbar 255;
BA_ "GenSigSendType" SG_ 512 MO_BZS_Charisma_FahrPr 0;
BA_ "GenSigSwitchedByIgnition" SG_ 512 MO_BZS_Charisma_FahrPr 0;
BA_ "GenSigSendType" SG_ 512 MO_BZS_Charisma_Status 0;
BA_ "GenSigSwitchedByIgnition" SG_ 512 MO_BZS_Charisma_Status 0;
BA_ "GenSigSendType" SG_ 512 MO_Charisma_FahrPr 0;
BA_ "GenSigSwitchedByIgnition" SG_ 512 MO_Charisma_FahrPr 0;
BA_ "GenSigSendType" SG_ 512 MO_Charisma_Status 0;
BA_ "GenSigSwitchedByIgnition" SG_ 512 MO_Charisma_Status 0;
BA_ "GenSigSendType" SG_ 512 MO_Drehzahlbeeinflussung 0;
BA_ "GenSigSwitchedByIgnition" SG_ 512 MO_Drehzahlbeeinflussung 0;
BA_ "GenSigSendType" SG_ 512 MO_Luftpfad_aktiv 0;
BA_ "GenSigSwitchedByIgnition" SG_ 512 MO_Luftpfad_aktiv 0;
BA_ "GenSigSendType" SG_ 512 MO_MAX_Wunschdrehzahl 0;
BA_ "GenSigSwitchedByIgnition" SG_ 512 MO_MAX_Wunschdrehzahl 0;
BA_ "GenSigSendType" SG_ 512 MO_MIN_Wunschdrehzahl 0;
BA_ "GenSigSwitchedByIgnition" SG_ 512 MO_MIN_Wunschdrehzahl 0;
BA_ "GenSigSendType" SG_ 512 MO_Motorlaufwarnung 0;
BA_ "GenSigSwitchedByIgnition" SG_ 512 MO_Motorlaufwarnung 0;
BA_ "GenSigSendType" SG_ 512 MO_NGS_Position 0;
BA_ "GenSigSwitchedByIgnition" SG_ 512 MO_NGS_Position 0;
BA_ "GenSigSendType" SG_ 512 MO_NGS_Status 0;
BA_ "GenSigSwitchedByIgnition" SG_ 512 MO_NGS_Status 0;
BA_ "Fehlerwert" SG_ 512 MO_NGS_Status 3;
BA_ "GenSigSendType" SG_ 512 MO_Overboost 0;
BA_ "GenSigSwitchedByIgnition" SG_ 512 MO_Overboost 0;
BA_ "GenSigSendType" SG_ 512 MO_Prio_MAX_Wunschdrehzahl 0;
BA_ "GenSigSwitchedByIgnition" SG_ 512 MO_Prio_MAX_Wunschdrehzahl 0;
BA_ "GenSigSendType" SG_ 512 MO_Prio_MIN_Wunschdrehzahl 0;
BA_ "GenSigSwitchedByIgnition" SG_ 512 MO_Prio_MIN_Wunschdrehzahl 0;
BA_ "GenSigSendType" SG_ 512 MO_Rampenzeit_Generator_Anf 0;
BA_ "GenSigStartValue" SG_ 512 MO_Rampenzeit_Generator_Anf 15;
BA_ "GenSigSwitchedByIgnition" SG_ 512 MO_Rampenzeit_Generator_Anf 0;
BA_ "GenSigSendType" SG_ 512 MO_Sperrung_FahrPr_BZS 0;
BA_ "GenSigSwitchedByIgnition" SG_ 512 MO_Sperrung_FahrPr_BZS 0;
BA_ "GenSigSendType" SG_ 512 MO_StSt_Charisma_FahrPr 0;
BA_ "GenSigSwitchedByIgnition" SG_ 512 MO_StSt_Charisma_FahrPr 0;
BA_ "GenSigSendType" SG_ 512 MO_StSt_Charisma_Status 0;
BA_ "GenSigSwitchedByIgnition" SG_ 512 MO_StSt_Charisma_Status 0;
BA_ "GenSigSendType" SG_ 512 MO_v_Begrenz_Aktivierbar 0;
BA_ "GenSigSwitchedByIgnition" SG_ 512 MO_v_Begrenz_Aktivierbar 0;
BA_ "GenSigSendType" SG_ 512 MO_v_Begrenzung_Niveau 0;
BA_ "GenSigSwitchedByIgnition" SG_ 512 MO_v_Begrenzung_Niveau 0;
BA_ "GenSigSendType" SG_ 512 PEA_Abschalttexte 0;
BA_ "GenSigSwitchedByIgnition" SG_ 512 PEA_Abschalttexte 0;
BA_ "GenSigSendType" SG_ 512 PEA_Ereignisanzeige 0;
BA_ "GenSigSwitchedByIgnition" SG_ 512 PEA_Ereignisanzeige 0;
BA_ "GenSigSendType" SG_ 512 PEA_Ereignisanzeige_temporaer 0;
BA_ "GenSigSwitchedByIgnition" SG_ 512 PEA_Ereignisanzeige_temporaer 0;
BA_ "GenSigSendType" SG_ 512 PEA_Fortschrittsanzeige 0;
BA_ "GenSigStartValue" SG_ 512 PEA_Fortschrittsanzeige 127;
BA_ "GenSigSwitchedByIgnition" SG_ 512 PEA_Fortschrittsanzeige 0;
BA_ "GenSigSendType" SG_ 512 PEA_Hinweis 0;
BA_ "GenSigSwitchedByIgnition" SG_ 512 PEA_Hinweis 0;
BA_ "GenSigSendType" SG_ 512 PEA_Zielgeschw 0;
BA_ "GenSigSwitchedByIgnition" SG_ 512 PEA_Zielgeschw 0;
BA_ "GenSigSendType" SG_ 512 PEA_Zielgeschw_Einheit 0;
BA_ "GenSigSwitchedByIgnition" SG_ 512 PEA_Zielgeschw_Einheit 0;
BA_ "GenSigSendType" SG_ 512 TSK_Akustik 0;
BA_ "GenSigSwitchedByIgnition" SG_ 512 TSK_Akustik 0;
BA_ "GenSigSendType" SG_ 512 TSK_Fahrzeugstatus_GRA 0;
BA_ "GenSigSwitchedByIgnition" SG_ 512 TSK_Fahrzeugstatus_GRA 0;
BA_ "GenSigSendType" SG_ 512 TSK_Fahrzeugstatus_Limiter 0;
BA_ "GenSigSwitchedByIgnition" SG_ 512 TSK_Fahrzeugstatus_Limiter 0;
BA_ "GenSigSendType" SG_ 512 TSK_Fahrzeugstatus_praed_Fkt 0;
BA_ "GenSigSwitchedByIgnition" SG_ 512 TSK_Fahrzeugstatus_praed_Fkt 0;
BA_ "GenSigSendType" SG_ 512 TSK_Limiter_Anzeige 0;
BA_ "GenSigSwitchedByIgnition" SG_ 512 TSK_Limiter_Anzeige 0;
BA_ "GenSigSendType" SG_ 512 TSK_Limiter_Fahrerinfo 0;
BA_ "GenSigSwitchedByIgnition" SG_ 512 TSK_Limiter_Fahrerinfo 0;
BA_ "GenSigSendType" SG_ 512 TSK_naechstes_Event 0;
BA_ "GenSigSwitchedByIgnition" SG_ 512 TSK_naechstes_Event 0;
BA_ "GenSigSendType" SG_ 512 TSK_naechstes_Event_Einheit 0;
BA_ "GenSigSwitchedByIgnition" SG_ 512 TSK_naechstes_Event_Einheit 0;
BA_ "GenSigSendType" SG_ 512 TSK_praediktiver_Hinweis 0;
BA_ "GenSigSwitchedByIgnition" SG_ 512 TSK_praediktiver_Hinweis 0;
BA_ "GenSigSendType" SG_ 512 TSK_Status_Anzeige 0;
BA_ "GenSigStartValue" SG_ 512 TSK_Status_Anzeige 1;
BA_ "GenSigSwitchedByIgnition" SG_ 512 TSK_Status_Anzeige 0;
BA_ "GenSigSendType" SG_ 512 TSK_Texte 0;
BA_ "GenSigSwitchedByIgnition" SG_ 512 TSK_Texte 0;
BA_ "GenSigSendType" SG_ 512 TSK_Texte_Primaeranz 0;
BA_ "GenSigSwitchedByIgnition" SG_ 512 TSK_Texte_Primaeranz 0;
BA_ "GenSigSendType" SG_ 512 TSK_Wunschgeschw 0;
BA_ "GenSigSwitchedByIgnition" SG_ 512 TSK_Wunschgeschw 0;
BA_ "GenSigSendType" SG_ 332 FoD_DTC_TSK_ACC 0;
BA_ "GenSigSwitchedByIgnition" SG_ 332 FoD_DTC_TSK_ACC 0;
BA_ "GenSigSendType" SG_ 332 FoD_DTC_TSK_GRA 0;
BA_ "GenSigSwitchedByIgnition" SG_ 332 FoD_DTC_TSK_GRA 0;
BA_ "GenSigSendType" SG_ 332 MO_Anforderung_HMS 3;
BA_ "GenSigSwitchedByIgnition" SG_ 332 MO_Anforderung_HMS 0;
BA_ "GenSigSendType" SG_ 332 MO_EBoost_verf_praed 0;
BA_ "GenSigSwitchedByIgnition" SG_ 332 MO_EBoost_verf_praed 0;
BA_ "GenSigSendType" SG_ 332 MO_eLaunch_verf 0;
BA_ "GenSigSwitchedByIgnition" SG_ 332 MO_eLaunch_verf 0;
BA_ "GenSigSendType" SG_ 332 MO_Fahrbereitschaft 3;
BA_ "GenSigSwitchedByIgnition" SG_ 332 MO_Fahrbereitschaft 0;
BA_ "GenSigSendType" SG_ 332 MO_Freilauf_Info 3;
BA_ "GenSigSwitchedByIgnition" SG_ 332 MO_Freilauf_Info 0;
BA_ "GenSigSendType" SG_ 332 MO_Freilauf_Status 3;
BA_ "GenSigSwitchedByIgnition" SG_ 332 MO_Freilauf_Status 0;
BA_ "Fehlerwert" SG_ 332 MO_Freilauf_Status 7;
BA_ "GenSigSendType" SG_ 332 MO_Freilauf_Typ 0;
BA_ "GenSigSwitchedByIgnition" SG_ 332 MO_Freilauf_Typ 0;
BA_ "GenSigSendType" SG_ 332 MO_Heckspoiler_Anf 0;
BA_ "GenSigSwitchedByIgnition" SG_ 332 MO_Heckspoiler_Anf 0;
BA_ "GenSigSendType" SG_ 332 MO_Krit_Heckobjekt 0;
BA_ "GenSigSwitchedByIgnition" SG_ 332 MO_Krit_Heckobjekt 0;
BA_ "Fehlerwert" SG_ 332 MO_Krit_Heckobjekt 7;
BA_ "GenSigSendType" SG_ 332 MO_NGS_Gangpos 3;
BA_ "GenSigSwitchedByIgnition" SG_ 332 MO_NGS_Gangpos 0;
BA_ "Fehlerwert" SG_ 332 MO_NGS_Gangpos 7;
BA_ "GenSigSendType" SG_ 332 MO_Positionierung_aktiv 0;
BA_ "GenSigSwitchedByIgnition" SG_ 332 MO_Positionierung_aktiv 0;
BA_ "GenSigSendType" SG_ 332 MO_QBit_Aussen_Temp 0;
BA_ "GenSigStartValue" SG_ 332 MO_QBit_Aussen_Temp 1;
BA_ "GenSigSwitchedByIgnition" SG_ 332 MO_QBit_Aussen_Temp 0;
BA_ "GenSigSendType" SG_ 332 MO_Servicemodus 0;
BA_ "GenSigSwitchedByIgnition" SG_ 332 MO_Servicemodus 0;
BA_ "GenSigSendType" SG_ 332 MO_Startwunsch 3;
BA_ "GenSigSwitchedByIgnition" SG_ 332 MO_Startwunsch 0;
BA_ "GenSigSendType" SG_ 332 OBD_Abs_Load_Val 0;
BA_ "GenSigStartValue" SG_ 332 OBD_Abs_Load_Val 65535;
BA_ "GenSigSwitchedByIgnition" SG_ 332 OBD_Abs_Load_Val 0;
BA_ "GenSigSendType" SG_ 332 OBD_Abs_Pedal_Pos 0;
BA_ "GenSigStartValue" SG_ 332 OBD_Abs_Pedal_Pos 255;
BA_ "GenSigSwitchedByIgnition" SG_ 332 OBD_Abs_Pedal_Pos 0;
BA_ "GenSigSendType" SG_ 332 OBD_Abs_Throttle_Pos 0;
BA_ "GenSigStartValue" SG_ 332 OBD_Abs_Throttle_Pos 255;
BA_ "GenSigSwitchedByIgnition" SG_ 332 OBD_Abs_Throttle_Pos 0;
BA_ "GenSigSendType" SG_ 332 OBD_Aussen_Temp_gef 0;
BA_ "GenSigStartValue" SG_ 332 OBD_Aussen_Temp_gef 254;
BA_ "GenSigSwitchedByIgnition" SG_ 332 OBD_Aussen_Temp_gef 0;
BA_ "Fehlerwert" SG_ 332 OBD_Aussen_Temp_gef 255;
BA_ "GenSigSendType" SG_ 332 OBD_Calc_Load_Val 0;
BA_ "GenSigStartValue" SG_ 332 OBD_Calc_Load_Val 255;
BA_ "GenSigSwitchedByIgnition" SG_ 332 OBD_Calc_Load_Val 0;
BA_ "GenSigSendType" SG_ 332 OBD_ClearMem_Inhibit 0;
BA_ "GenSigSwitchedByIgnition" SG_ 332 OBD_ClearMem_Inhibit 0;
BA_ "GenSigSendType" SG_ 332 OBD_Driving_Cycle 0;
BA_ "GenSigSwitchedByIgnition" SG_ 332 OBD_Driving_Cycle 0;
BA_ "GenSigSendType" SG_ 332 OBD_Eng_Cool_Temp 0;
BA_ "GenSigStartValue" SG_ 332 OBD_Eng_Cool_Temp 255;
BA_ "GenSigSwitchedByIgnition" SG_ 332 OBD_Eng_Cool_Temp 0;
BA_ "GenSigSendType" SG_ 332 OBD_Kaltstart_Denominator 0;
BA_ "GenSigSwitchedByIgnition" SG_ 332 OBD_Kaltstart_Denominator 0;
BA_ "GenSigSendType" SG_ 332 OBD_Minimum_Trip 0;
BA_ "GenSigSwitchedByIgnition" SG_ 332 OBD_Minimum_Trip 0;
BA_ "GenSigSendType" SG_ 332 OBD_Normed_Trip 0;
BA_ "GenSigSwitchedByIgnition" SG_ 332 OBD_Normed_Trip 0;
BA_ "GenSigSendType" SG_ 332 OBD_Sperrung_IUMPR 0;
BA_ "GenSigSwitchedByIgnition" SG_ 332 OBD_Sperrung_IUMPR 0;
BA_ "GenSigSendType" SG_ 332 OBD_Sperrung_Kaltstart_Denom 0;
BA_ "GenSigSwitchedByIgnition" SG_ 332 OBD_Sperrung_Kaltstart_Denom 0;
BA_ "GenSigSendType" SG_ 332 OBD_Warm_Up_Cycle 0;
BA_ "GenSigSwitchedByIgnition" SG_ 332 OBD_Warm_Up_Cycle 0;
BA_ "GenSigSendType" SG_ 332 TSK_ACC_FoD_Status 0;
BA_ "GenSigSwitchedByIgnition" SG_ 332 TSK_ACC_FoD_Status 0;
BA_ "GenSigSendType" SG_ 332 TSK_aktives_System 3;
BA_ "GenSigSwitchedByIgnition" SG_ 332 TSK_aktives_System 0;
BA_ "GenSigSendType" SG_ 332 TSK_Anf_Antriebsmoment 3;
BA_ "GenSigSwitchedByIgnition" SG_ 332 TSK_Anf_Antriebsmoment 0;
BA_ "GenSigSendType" SG_ 332 TSK_Einheit_vMax_Fahrerassistenz 0;
BA_ "GenSigSwitchedByIgnition" SG_ 332 TSK_Einheit_vMax_Fahrerassistenz 0;
BA_ "GenSigSendType" SG_ 332 TSK_erhoehter_Fahrwiderstand 3;
BA_ "GenSigSwitchedByIgnition" SG_ 332 TSK_erhoehter_Fahrwiderstand 0;
BA_ "GenSigSendType" SG_ 332 TSK_GRA_FoD_Status 0;
BA_ "GenSigSwitchedByIgnition" SG_ 332 TSK_GRA_FoD_Status 0;
BA_ "GenSigSendType" SG_ 332 TSK_Status_ARA 3;
BA_ "GenSigStartValue" SG_ 332 TSK_Status_ARA 1;
BA_ "GenSigSwitchedByIgnition" SG_ 332 TSK_Status_ARA 0;
BA_ "Fehlerwert" SG_ 332 TSK_Status_ARA 7;
BA_ "GenSigSendType" SG_ 332 TSK_Status_EA 3;
BA_ "GenSigStartValue" SG_ 332 TSK_Status_EA 1;
BA_ "GenSigSwitchedByIgnition" SG_ 332 TSK_Status_EA 0;
BA_ "Fehlerwert" SG_ 332 TSK_Status_EA 7;
BA_ "GenSigSendType" SG_ 332 TSK_Status_IPA 3;
BA_ "GenSigStartValue" SG_ 332 TSK_Status_IPA 1;
BA_ "GenSigSwitchedByIgnition" SG_ 332 TSK_Status_IPA 0;
BA_ "Fehlerwert" SG_ 332 TSK_Status_IPA 7;
BA_ "GenSigSendType" SG_ 332 TSK_Status_PLA 3;
BA_ "GenSigStartValue" SG_ 332 TSK_Status_PLA 1;
BA_ "GenSigSwitchedByIgnition" SG_ 332 TSK_Status_PLA 0;
BA_ "Fehlerwert" SG_ 332 TSK_Status_PLA 7;
BA_ "GenSigSendType" SG_ 332 TSK_vMax_aktuell 0;
BA_ "GenSigStartValue" SG_ 332 TSK_vMax_aktuell 255;
BA_ "GenSigSendType" SG_ 332 TSK_vMax_Fahrerassistenz 0;
BA_ "GenSigStartValue" SG_ 332 TSK_vMax_Fahrerassistenz 511;
BA_ "GenSigSwitchedByIgnition" SG_ 332 TSK_vMax_Fahrerassistenz 0;
BA_ "GenSigSendType" SG_ 246 FDR_Allrad_Anteil_max_sek 0;
BA_ "GenSigStartValue" SG_ 246 FDR_Allrad_Anteil_max_sek 510;
BA_ "Fehlerwert" SG_ 246 FDR_Allrad_Anteil_max_sek 511;
BA_ "GenSigSendType" SG_ 246 FDR_Allrad_Anteil_min_sek 0;
BA_ "GenSigStartValue" SG_ 246 FDR_Allrad_Anteil_min_sek 510;
BA_ "Fehlerwert" SG_ 246 FDR_Allrad_Anteil_min_sek 511;
BA_ "GenSigSendType" SG_ 246 FDR_MomRad_Eingriff 0;
BA_ "GenSigStartValue" SG_ 246 FDR_MomRad_Eingriff 8190;
BA_ "GenSigSwitchedByIgnition" SG_ 246 FDR_MomRad_Eingriff 0;
BA_ "Fehlerwert" SG_ 246 FDR_MomRad_Eingriff 8191;
BA_ "GenSigSendType" SG_ 246 FDR_MomRad_Eingriff_sek 0;
BA_ "GenSigStartValue" SG_ 246 FDR_MomRad_Eingriff_sek 8190;
BA_ "GenSigSwitchedByIgnition" SG_ 246 FDR_MomRad_Eingriff_sek 0;
BA_ "Fehlerwert" SG_ 246 FDR_MomRad_Eingriff_sek 8191;
BA_ "GenSigSendType" SG_ 246 FDR_Status_Eingriff 0;
BA_ "GenSigSwitchedByIgnition" SG_ 246 FDR_Status_Eingriff 0;
BA_ "GenSigSendType" SG_ 246 FDR_Status_Eingriff_sek 0;
BA_ "GenSigSwitchedByIgnition" SG_ 246 FDR_Status_Eingriff_sek 0;
BA_ "GenSigSendType" SG_ 246 Motor_55_BZ 0;
BA_ "GenSigFuncType" SG_ 246 Motor_55_BZ 1;
BA_ "GenSigSwitchedByIgnition" SG_ 246 Motor_55_BZ 0;
BA_ "GenSigSendType" SG_ 246 Motor_55_CRC 0;
BA_ "GenSigFuncType" SG_ 246 Motor_55_CRC 2;
BA_ "GenSigSwitchedByIgnition" SG_ 246 Motor_55_CRC 0;
BA_ "GenSigSendType" SG_ 246 TS_Allrad_Anteil_sek 0;
BA_ "GenSigStartValue" SG_ 246 TS_Allrad_Anteil_sek 510;
BA_ "GenSigSwitchedByIgnition" SG_ 246 TS_Allrad_Anteil_sek 0;
BA_ "Fehlerwert" SG_ 246 TS_Allrad_Anteil_sek 511;
BA_ "GenSigSendType" SG_ 246 TS_Faktor_Radmomente 0;
BA_ "GenSigSwitchedByIgnition" SG_ 246 TS_Faktor_Radmomente 0;
BA_ "GenSigSendType" SG_ 246 TS_MomRad_Ist 0;
BA_ "GenSigStartValue" SG_ 246 TS_MomRad_Ist 8190;
BA_ "GenSigSwitchedByIgnition" SG_ 246 TS_MomRad_Ist 0;
BA_ "GenSigSendType" SG_ 246 TS_MomRad_Ist_sek 0;
BA_ "GenSigStartValue" SG_ 246 TS_MomRad_Ist_sek 8190;
BA_ "GenSigSwitchedByIgnition" SG_ 246 TS_MomRad_Ist_sek 0;
BA_ "Fehlerwert" SG_ 246 TS_MomRad_Ist_sek 8191;
BA_ "GenSigSendType" SG_ 246 TS_MomRad_Soll_Summe 0;
BA_ "GenSigStartValue" SG_ 246 TS_MomRad_Soll_Summe 8190;
BA_ "GenSigSwitchedByIgnition" SG_ 246 TS_MomRad_Soll_Summe 0;
BA_ "GenSigSendType" SG_ 246 TS_MomRad_verfuegb_max 0;
BA_ "GenSigStartValue" SG_ 246 TS_MomRad_verfuegb_max 4094;
BA_ "GenSigSwitchedByIgnition" SG_ 246 TS_MomRad_verfuegb_max 0;
BA_ "GenSigSendType" SG_ 246 TS_MomRad_verfuegb_max_sek 0;
BA_ "GenSigStartValue" SG_ 246 TS_MomRad_verfuegb_max_sek 4094;
BA_ "GenSigSwitchedByIgnition" SG_ 246 TS_MomRad_verfuegb_max_sek 0;
BA_ "Fehlerwert" SG_ 246 TS_MomRad_verfuegb_max_sek 4095;
BA_ "GenSigSendType" SG_ 246 TS_MomRad_verfuegb_maxReku 0;
BA_ "GenSigStartValue" SG_ 246 TS_MomRad_verfuegb_maxReku 4094;
BA_ "GenSigSwitchedByIgnition" SG_ 246 TS_MomRad_verfuegb_maxReku 0;
BA_ "GenSigSendType" SG_ 246 TS_MomRad_verfuegb_maxReku_sek 0;
BA_ "GenSigStartValue" SG_ 246 TS_MomRad_verfuegb_maxReku_sek 4094;
BA_ "GenSigSwitchedByIgnition" SG_ 246 TS_MomRad_verfuegb_maxReku_sek 0;
BA_ "Fehlerwert" SG_ 246 TS_MomRad_verfuegb_maxReku_sek 4095;
BA_ "GenSigSendType" SG_ 246 TS_MomRad_verfuegb_maxReku_Summe 0;
BA_ "GenSigStartValue" SG_ 246 TS_MomRad_verfuegb_maxReku_Summe 4094;
BA_ "GenSigSwitchedByIgnition" SG_ 246 TS_MomRad_verfuegb_maxReku_Summe 0;
BA_ "Fehlerwert" SG_ 246 TS_MomRad_verfuegb_maxReku_Summe 4095;
BA_ "GenSigSendType" SG_ 246 TS_MomRad_Wunsch 0;
BA_ "GenSigStartValue" SG_ 246 TS_MomRad_Wunsch 8190;
BA_ "GenSigSwitchedByIgnition" SG_ 246 TS_MomRad_Wunsch 0;
BA_ "GenSigSendType" SG_ 246 TS_MomRad_Wunsch_sek 0;
BA_ "GenSigStartValue" SG_ 246 TS_MomRad_Wunsch_sek 8190;
BA_ "GenSigSwitchedByIgnition" SG_ 246 TS_MomRad_Wunsch_sek 0;
BA_ "Fehlerwert" SG_ 246 TS_MomRad_Wunsch_sek 8191;
BA_ "GenSigSendType" SG_ 246 TS_Status_MomRad_Ist 0;
BA_ "GenSigStartValue" SG_ 246 TS_Status_MomRad_Ist 2;
BA_ "GenSigSwitchedByIgnition" SG_ 246 TS_Status_MomRad_Ist 0;
BA_ "GenSigSendType" SG_ 190 MO_DC_Max_Strom_HV 0;
BA_ "GenSigStartValue" SG_ 190 MO_DC_Max_Strom_HV 255;
BA_ "GenSigSwitchedByIgnition" SG_ 190 MO_DC_Max_Strom_HV 0;
BA_ "GenSigSendType" SG_ 190 MO_DC_SollSpannung_HV 0;
BA_ "GenSigStartValue" SG_ 190 MO_DC_SollSpannung_HV 255;
BA_ "GenSigSwitchedByIgnition" SG_ 190 MO_DC_SollSpannung_HV 0;
BA_ "GenSigSendType" SG_ 190 MO_EM1_AR_Anf 0;
BA_ "GenSigSwitchedByIgnition" SG_ 190 MO_EM1_AR_Anf 0;
BA_ "GenSigSendType" SG_ 190 MO_EM1_DynLimit_AR 0;
BA_ "GenSigStartValue" SG_ 190 MO_EM1_DynLimit_AR 255;
BA_ "GenSigSwitchedByIgnition" SG_ 190 MO_EM1_DynLimit_AR 0;
BA_ "GenSigSendType" SG_ 190 MO_EM1_Kp_AR 0;
BA_ "GenSigStartValue" SG_ 190 MO_EM1_Kp_AR 511;
BA_ "GenSigSwitchedByIgnition" SG_ 190 MO_EM1_Kp_AR 0;
BA_ "GenSigSendType" SG_ 190 MO_EM1_Max_Leistung 0;
BA_ "GenSigStartValue" SG_ 190 MO_EM1_Max_Leistung 16382;
BA_ "GenSigSwitchedByIgnition" SG_ 190 MO_EM1_Max_Leistung 0;
BA_ "GenSigSendType" SG_ 190 MO_EM1_Max_Moment 0;
BA_ "GenSigStartValue" SG_ 190 MO_EM1_Max_Moment 4094;
BA_ "GenSigSwitchedByIgnition" SG_ 190 MO_EM1_Max_Moment 0;
BA_ "GenSigSendType" SG_ 190 MO_EM1_Max_Strom_Lim 0;
BA_ "GenSigStartValue" SG_ 190 MO_EM1_Max_Strom_Lim 8190;
BA_ "GenSigSwitchedByIgnition" SG_ 190 MO_EM1_Max_Strom_Lim 0;
BA_ "GenSigSendType" SG_ 190 MO_EM1_MaxDrehzahl 0;
BA_ "GenSigStartValue" SG_ 190 MO_EM1_MaxDrehzahl 16383;
BA_ "GenSigSwitchedByIgnition" SG_ 190 MO_EM1_MaxDrehzahl 0;
BA_ "GenSigSendType" SG_ 190 MO_EM1_Min_Leistung 0;
BA_ "GenSigStartValue" SG_ 190 MO_EM1_Min_Leistung 16382;
BA_ "GenSigSwitchedByIgnition" SG_ 190 MO_EM1_Min_Leistung 0;
BA_ "GenSigSendType" SG_ 190 MO_EM1_Min_Moment 0;
BA_ "GenSigStartValue" SG_ 190 MO_EM1_Min_Moment 4094;
BA_ "GenSigSwitchedByIgnition" SG_ 190 MO_EM1_Min_Moment 0;
BA_ "GenSigSendType" SG_ 190 MO_EM1_Min_Strom_Lim 0;
BA_ "GenSigStartValue" SG_ 190 MO_EM1_Min_Strom_Lim 8190;
BA_ "GenSigSwitchedByIgnition" SG_ 190 MO_EM1_Min_Strom_Lim 0;
BA_ "GenSigSendType" SG_ 190 MO_EM1_MinDrehzahl 0;
BA_ "GenSigStartValue" SG_ 190 MO_EM1_MinDrehzahl 16383;
BA_ "GenSigSwitchedByIgnition" SG_ 190 MO_EM1_MinDrehzahl 0;
BA_ "GenSigSendType" SG_ 190 MO_EM1_Periode_AR 0;
BA_ "GenSigStartValue" SG_ 190 MO_EM1_Periode_AR 255;
BA_ "GenSigSwitchedByIgnition" SG_ 190 MO_EM1_Periode_AR 0;
BA_ "GenSigSendType" SG_ 190 MO_EM1_Sollmodus 0;
BA_ "GenSigStartValue" SG_ 190 MO_EM1_Sollmodus 15;
BA_ "GenSigSwitchedByIgnition" SG_ 190 MO_EM1_Sollmodus 0;
BA_ "GenSigSendType" SG_ 190 MO_EM1_SollMoment 0;
BA_ "GenSigStartValue" SG_ 190 MO_EM1_SollMoment 4094;
BA_ "GenSigSwitchedByIgnition" SG_ 190 MO_EM1_SollMoment 0;
BA_ "GenSigSendType" SG_ 190 MO_EM1_SollSpannung 0;
BA_ "GenSigStartValue" SG_ 190 MO_EM1_SollSpannung 4095;
BA_ "GenSigSwitchedByIgnition" SG_ 190 MO_EM1_SollSpannung 0;
BA_ "GenSigSendType" SG_ 190 MO_EM2_AR_Anf 0;
BA_ "GenSigSwitchedByIgnition" SG_ 190 MO_EM2_AR_Anf 0;
BA_ "GenSigSendType" SG_ 190 MO_EM2_DynLimit_AR 0;
BA_ "GenSigStartValue" SG_ 190 MO_EM2_DynLimit_AR 255;
BA_ "GenSigSwitchedByIgnition" SG_ 190 MO_EM2_DynLimit_AR 0;
BA_ "GenSigSendType" SG_ 190 MO_EM2_Max_Leistung 0;
BA_ "GenSigStartValue" SG_ 190 MO_EM2_Max_Leistung 16382;
BA_ "GenSigSwitchedByIgnition" SG_ 190 MO_EM2_Max_Leistung 0;
BA_ "GenSigSendType" SG_ 190 MO_EM2_Max_Moment 0;
BA_ "GenSigStartValue" SG_ 190 MO_EM2_Max_Moment 4094;
BA_ "GenSigSwitchedByIgnition" SG_ 190 MO_EM2_Max_Moment 0;
BA_ "Fehlerwert" SG_ 190 MO_EM2_Max_Moment 4095;
BA_ "GenSigSendType" SG_ 190 MO_EM2_Max_Strom_Lim 0;
BA_ "GenSigStartValue" SG_ 190 MO_EM2_Max_Strom_Lim 8190;
BA_ "GenSigSwitchedByIgnition" SG_ 190 MO_EM2_Max_Strom_Lim 0;
BA_ "GenSigSendType" SG_ 190 MO_EM2_MaxDrehzahl 0;
BA_ "GenSigStartValue" SG_ 190 MO_EM2_MaxDrehzahl 16383;
BA_ "GenSigSwitchedByIgnition" SG_ 190 MO_EM2_MaxDrehzahl 0;
BA_ "GenSigSendType" SG_ 190 MO_EM2_Min_Leistung 0;
BA_ "GenSigStartValue" SG_ 190 MO_EM2_Min_Leistung 16382;
BA_ "GenSigSwitchedByIgnition" SG_ 190 MO_EM2_Min_Leistung 0;
BA_ "GenSigSendType" SG_ 190 MO_EM2_Min_Moment 0;
BA_ "GenSigStartValue" SG_ 190 MO_EM2_Min_Moment 4094;
BA_ "GenSigSwitchedByIgnition" SG_ 190 MO_EM2_Min_Moment 0;
BA_ "Fehlerwert" SG_ 190 MO_EM2_Min_Moment 4095;
BA_ "GenSigSendType" SG_ 190 MO_EM2_Min_Strom_Lim 0;
BA_ "GenSigStartValue" SG_ 190 MO_EM2_Min_Strom_Lim 8190;
BA_ "GenSigSwitchedByIgnition" SG_ 190 MO_EM2_Min_Strom_Lim 0;
BA_ "GenSigSendType" SG_ 190 MO_EM2_MinDrehzahl 0;
BA_ "GenSigStartValue" SG_ 190 MO_EM2_MinDrehzahl 16383;
BA_ "GenSigSwitchedByIgnition" SG_ 190 MO_EM2_MinDrehzahl 0;
BA_ "GenSigSendType" SG_ 190 MO_EM2_Periode_AR 0;
BA_ "GenSigStartValue" SG_ 190 MO_EM2_Periode_AR 255;
BA_ "GenSigSwitchedByIgnition" SG_ 190 MO_EM2_Periode_AR 0;
BA_ "GenSigSendType" SG_ 190 MO_EM2_Sollmodus 0;
BA_ "GenSigStartValue" SG_ 190 MO_EM2_Sollmodus 15;
BA_ "GenSigSwitchedByIgnition" SG_ 190 MO_EM2_Sollmodus 0;
BA_ "GenSigSendType" SG_ 190 MO_EM2_SollMoment 0;
BA_ "GenSigStartValue" SG_ 190 MO_EM2_SollMoment 4094;
BA_ "GenSigSwitchedByIgnition" SG_ 190 MO_EM2_SollMoment 0;
BA_ "Fehlerwert" SG_ 190 MO_EM2_SollMoment 4095;
BA_ "GenSigSendType" SG_ 190 MO_EM2_SollSpannung 0;
BA_ "GenSigStartValue" SG_ 190 MO_EM2_SollSpannung 4095;
BA_ "GenSigSwitchedByIgnition" SG_ 190 MO_EM2_SollSpannung 0;
BA_ "GenSigSendType" SG_ 190 Motor_56_BZ 0;
BA_ "GenSigFuncType" SG_ 190 Motor_56_BZ 1;
BA_ "GenSigSwitchedByIgnition" SG_ 190 Motor_56_BZ 0;
BA_ "GenSigSendType" SG_ 190 Motor_56_CRC 0;
BA_ "GenSigFuncType" SG_ 190 Motor_56_CRC 2;
BA_ "GenSigSwitchedByIgnition" SG_ 190 Motor_56_CRC 0;
BA_ "GenSigSendType" SG_ 2463978666 MO_Drehzahl_EM 0;
BA_ "GenSigStartValue" SG_ 2463978666 MO_Drehzahl_EM 8190;
BA_ "GenSigSwitchedByIgnition" SG_ 2463978666 MO_Drehzahl_EM 0;
BA_ "Fehlerwert" SG_ 2463978666 MO_Drehzahl_EM 8191;
BA_ "GenSigSendType" SG_ 2463978666 MO_Drehzahl_EM_sek 0;
BA_ "GenSigStartValue" SG_ 2463978666 MO_Drehzahl_EM_sek 8190;
BA_ "GenSigSwitchedByIgnition" SG_ 2463978666 MO_Drehzahl_EM_sek 0;
BA_ "Fehlerwert" SG_ 2463978666 MO_Drehzahl_EM_sek 8191;
BA_ "GenSigSendType" SG_ 2463978666 MO_EM1_Generator_Leistung 0;
BA_ "GenSigStartValue" SG_ 2463978666 MO_EM1_Generator_Leistung 254;
BA_ "GenSigSwitchedByIgnition" SG_ 2463978666 MO_EM1_Generator_Leistung 0;
BA_ "Fehlerwert" SG_ 2463978666 MO_EM1_Generator_Leistung 255;
BA_ "GenSigSendType" SG_ 2463978666 MO_EM1_Max_Leistung_Gesamt 0;
BA_ "GenSigStartValue" SG_ 2463978666 MO_EM1_Max_Leistung_Gesamt 8190;
BA_ "GenSigSwitchedByIgnition" SG_ 2463978666 MO_EM1_Max_Leistung_Gesamt 0;
BA_ "GenSigSendType" SG_ 2463978666 MO_EM1_Max_Spannung_Lim 0;
BA_ "GenSigStartValue" SG_ 2463978666 MO_EM1_Max_Spannung_Lim 1022;
BA_ "GenSigSwitchedByIgnition" SG_ 2463978666 MO_EM1_Max_Spannung_Lim 0;
BA_ "GenSigSendType" SG_ 2463978666 MO_EM1_Min_Leistung_Gesamt 0;
BA_ "GenSigStartValue" SG_ 2463978666 MO_EM1_Min_Leistung_Gesamt 8190;
BA_ "GenSigSwitchedByIgnition" SG_ 2463978666 MO_EM1_Min_Leistung_Gesamt 0;
BA_ "GenSigSendType" SG_ 2463978666 MO_EM1_Min_Spannung_Lim 0;
BA_ "GenSigStartValue" SG_ 2463978666 MO_EM1_Min_Spannung_Lim 1022;
BA_ "GenSigSwitchedByIgnition" SG_ 2463978666 MO_EM1_Min_Spannung_Lim 0;
BA_ "GenSigSendType" SG_ 2463978666 MO_EM2_Max_Leistung_Gesamt 0;
BA_ "GenSigStartValue" SG_ 2463978666 MO_EM2_Max_Leistung_Gesamt 8190;
BA_ "GenSigSwitchedByIgnition" SG_ 2463978666 MO_EM2_Max_Leistung_Gesamt 0;
BA_ "GenSigSendType" SG_ 2463978666 MO_EM2_Max_Spannung_Lim 0;
BA_ "GenSigStartValue" SG_ 2463978666 MO_EM2_Max_Spannung_Lim 1022;
BA_ "GenSigSwitchedByIgnition" SG_ 2463978666 MO_EM2_Max_Spannung_Lim 0;
BA_ "GenSigSendType" SG_ 2463978666 MO_EM2_Min_Leistung_Gesamt 0;
BA_ "GenSigStartValue" SG_ 2463978666 MO_EM2_Min_Leistung_Gesamt 8190;
BA_ "GenSigSwitchedByIgnition" SG_ 2463978666 MO_EM2_Min_Leistung_Gesamt 0;
BA_ "GenSigSendType" SG_ 2463978666 MO_EM2_Min_Spannung_Lim 0;
BA_ "GenSigStartValue" SG_ 2463978666 MO_EM2_Min_Spannung_Lim 1022;
BA_ "GenSigSwitchedByIgnition" SG_ 2463978666 MO_EM2_Min_Spannung_Lim 0;
BA_ "GenSigSendType" SG_ 2463978666 MO_Rekuperation_EM_Ges_Ueberlauf 0;
BA_ "GenSigSwitchedByIgnition" SG_ 2463978666 MO_Rekuperation_EM_Ges_Ueberlauf 0;
BA_ "GenSigSendType" SG_ 2463978666 MO_Rekuperation_Ges_EM 0;
BA_ "GenSigSwitchedByIgnition" SG_ 2463978666 MO_Rekuperation_Ges_EM 0;
BA_ "GenSigSendType" SG_ 2463978666 MO_Uebersetzung_EM 0;
BA_ "GenSigStartValue" SG_ 2463978666 MO_Uebersetzung_EM 1022;
BA_ "GenSigSwitchedByIgnition" SG_ 2463978666 MO_Uebersetzung_EM 0;
BA_ "Fehlerwert" SG_ 2463978666 MO_Uebersetzung_EM 1023;
BA_ "GenSigSendType" SG_ 2463978666 MO_Uebersetzung_EM_sek 0;
BA_ "GenSigStartValue" SG_ 2463978666 MO_Uebersetzung_EM_sek 1022;
BA_ "GenSigSwitchedByIgnition" SG_ 2463978666 MO_Uebersetzung_EM_sek 0;
BA_ "Fehlerwert" SG_ 2463978666 MO_Uebersetzung_EM_sek 1023;
BA_ "GenSigSendType" SG_ 2463978666 MO_Verbrauch_EM_Ges 0;
BA_ "GenSigSwitchedByIgnition" SG_ 2463978666 MO_Verbrauch_EM_Ges 0;
BA_ "GenSigSendType" SG_ 2463978666 MO_Verbrauch_EM_Ges_Ueberlauf 0;
BA_ "GenSigSwitchedByIgnition" SG_ 2463978666 MO_Verbrauch_EM_Ges_Ueberlauf 0;
BA_REL_ "GenSigTimeoutTime" BU_SG_REL_ Airbag SG_ 958 MO_Fahrer_bremst 1000;
BA_REL_ "GenSigTimeoutTime" BU_SG_REL_ Airbag SG_ 958 MO_QBit_Fahrer_bremst 1000;
BA_REL_ "GenSigTimeoutTime" BU_SG_REL_ Airbag SG_ 958 MO_BLS 1000;
BA_REL_ "GenSigTimeoutTime" BU_SG_REL_ Airbag SG_ 267 MO_Fahrpedalrohwert_01 500;
BA_REL_ "GenSigTimeoutTime" BU_SG_REL_ Airbag SG_ 267 MO_QBit_Fahrpedalwerte_01 500;
BA_REL_ "GenSigTimeoutTime" BU_SG_REL_ ICAS1_Gateway SG_ 958 Motor_14_CRC 1000;
BA_REL_ "GenSigTimeoutTime" BU_SG_REL_ ICAS1_Gateway SG_ 958 Motor_14_BZ 1000;
BA_REL_ "GenSigTimeoutTime" BU_SG_REL_ ICAS1_Gateway SG_ 958 MO_HYB_Fahrbereitschaft 1000;
BA_REL_ "GenSigTimeoutTime" BU_SG_REL_ ICAS1_Gateway SG_ 958 MO_Fahrer_bremst 1000;
BA_REL_ "GenSigTimeoutTime" BU_SG_REL_ ICAS1_Gateway SG_ 958 MO_BLS 1000;
BA_REL_ "GenSigTimeoutTime" BU_SG_REL_ ICAS1_Gateway SG_ 1631 MO_Energieinhalt_BMS 5000;
BA_REL_ "GenSigTimeoutTime" BU_SG_REL_ ICAS1_Gateway SG_ 1648 MO_Bremslicht_Reku 5000;
BA_REL_ "GenSigTimeoutTime" BU_SG_REL_ ICAS1_Gateway SG_ 1648 MO_EPCL 5000;
BA_REL_ "GenSigTimeoutTime" BU_SG_REL_ ICAS1_Gateway SG_ 1648 MO_Fahrzeugtyp 5000;
BA_REL_ "GenSigTimeoutTime" BU_SG_REL_ ICAS1_Gateway SG_ 267 MO_Fahrpedalrohwert_01 500;
BA_REL_ "GenSigTimeoutTime" BU_SG_REL_ ICAS1_Gateway SG_ 267 MO_QBit_Fahrpedalwerte_01 500;
BA_REL_ "GenSigTimeoutTime" BU_SG_REL_ ICAS1_Gateway SG_ 330 Ladezustand_02 500;
BA_REL_ "GenSigTimeoutTime" BU_SG_REL_ ICAS1_Gateway SG_ 512 MO_Anzeige_Fahrbereitschaft 500;
BA_REL_ "GenSigTimeoutTime" BU_SG_REL_ ICAS1_Gateway SG_ 332 TSK_vMax_aktuell 1000;
BA_REL_ "GenSigTimeoutTime" BU_SG_REL_ ICAS1_Gateway SG_ 332 MO_Fahrbereitschaft 1000;
BA_REL_ "GenSigTimeoutTime" BU_SG_REL_ ICAS1_Gateway SG_ 332 MO_Startwunsch 1000;
BA_REL_ "GenSigTimeoutTime" BU_SG_REL_ ICAS1_Gateway SG_ 2463978666 MO_Verbrauch_EM_Ges 1000;
BA_REL_ "GenSigTimeoutTime" BU_SG_REL_ ICAS1_Gateway SG_ 2463978666 MO_Verbrauch_EM_Ges_Ueberlauf 1000;
BA_REL_ "GenSigTimeoutTime" BU_SG_REL_ ICAS1_Gateway SG_ 2463978666 MO_Rekuperation_Ges_EM 1000;
BA_REL_ "GenSigTimeoutTime" BU_SG_REL_ ICAS1_Gateway SG_ 2463978666 MO_Rekuperation_EM_Ges_Ueberlauf 1000;
BA_REL_ "GenSigTimeoutTime" BU_SG_REL_ ICAS1_Gateway SG_ 2463978666 MO_Drehzahl_EM 1000;
BA_REL_ "GenSigTimeoutTime" BU_SG_REL_ ICAS1_Gateway SG_ 2463978666 MO_Uebersetzung_EM 1000;
BA_REL_ "GenSigTimeoutTime" BU_SG_REL_ ICAS1_Gateway SG_ 2463978666 MO_Drehzahl_EM_sek 1000;
BA_REL_ "GenSigTimeoutTime" BU_SG_REL_ ICAS1_Gateway SG_ 2463978666 MO_Uebersetzung_EM_sek 1000;
BA_REL_ "GenSigTimeoutTime" BU_SG_REL_ ICAS1_KommunikationsServer SG_ 958 MO_Kickdown 1000;
BA_REL_ "GenSigTimeoutTime" BU_SG_REL_ ICAS1_KommunikationsServer SG_ 1648 MO_EPCL 5000;
BA_REL_ "GenSigTimeoutTime" BU_SG_REL_ ICAS1_KommunikationsServer SG_ 1648 MO_Fahrzeugtyp 5000;
BA_REL_ "GenSigTimeoutTime" BU_SG_REL_ ICAS1_KommunikationsServer SG_ 967 MO_RedFahrleistung_Lampe 1000;
BA_REL_ "GenSigTimeoutTime" BU_SG_REL_ ICAS1_KommunikationsServer SG_ 706 MO_Rekuperationsstufe 5000;
BA_REL_ "GenSigTimeoutTime" BU_SG_REL_ ICAS1_KommunikationsServer SG_ 706 TSK_Einheit_vMax_FahrerInfo 5000;
BA_REL_ "GenSigTimeoutTime" BU_SG_REL_ ICAS1_KommunikationsServer SG_ 706 TSK_Status_vMax_FahrerInfo 5000;
BA_REL_ "GenSigTimeoutTime" BU_SG_REL_ ICAS1_KommunikationsServer SG_ 706 FDR_Warnung_ALR 5000;
BA_REL_ "GenSigTimeoutTime" BU_SG_REL_ ICAS1_KommunikationsServer SG_ 706 TSK_vMax_FahrerInfo 5000;
BA_REL_ "GenSigTimeoutTime" BU_SG_REL_ ICAS1_KommunikationsServer SG_ 267 TSK_Hauptschalter_GRA_ACC 500;
BA_REL_ "GenSigTimeoutTime" BU_SG_REL_ ICAS1_KommunikationsServer SG_ 330 MO_ePerformance 500;
BA_REL_ "GenSigTimeoutTime" BU_SG_REL_ ICAS1_KommunikationsServer SG_ 330 Ladezustand_02 500;
BA_REL_ "GenSigTimeoutTime" BU_SG_REL_ ICAS1_KommunikationsServer SG_ 330 MO_Powermeter 500;
BA_REL_ "GenSigTimeoutTime" BU_SG_REL_ ICAS1_KommunikationsServer SG_ 512 TSK_Wunschgeschw 500;
BA_REL_ "GenSigTimeoutTime" BU_SG_REL_ ICAS1_KommunikationsServer SG_ 512 TSK_Texte 500;
BA_REL_ "GenSigTimeoutTime" BU_SG_REL_ ICAS1_KommunikationsServer SG_ 512 TSK_Akustik 500;
BA_REL_ "GenSigTimeoutTime" BU_SG_REL_ ICAS1_KommunikationsServer SG_ 512 TSK_Texte_Primaeranz 500;
BA_REL_ "GenSigTimeoutTime" BU_SG_REL_ ICAS1_KommunikationsServer SG_ 512 TSK_Limiter_Fahrerinfo 500;
BA_REL_ "GenSigTimeoutTime" BU_SG_REL_ ICAS1_KommunikationsServer SG_ 512 TSK_Limiter_Anzeige 500;
BA_REL_ "GenSigTimeoutTime" BU_SG_REL_ ICAS1_KommunikationsServer SG_ 512 TSK_Fahrzeugstatus_GRA 500;
BA_REL_ "GenSigTimeoutTime" BU_SG_REL_ ICAS1_KommunikationsServer SG_ 512 TSK_Fahrzeugstatus_Limiter 500;
BA_REL_ "GenSigTimeoutTime" BU_SG_REL_ ICAS1_KommunikationsServer SG_ 512 TSK_Status_Anzeige 500;
BA_REL_ "GenSigTimeoutTime" BU_SG_REL_ ICAS1_KommunikationsServer SG_ 512 MO_Anzeige_Fahrbereitschaft 500;
BA_REL_ "GenSigTimeoutTime" BU_SG_REL_ ICAS1_KommunikationsServer SG_ 2463978666 MO_Verbrauch_EM_Ges 1000;
BA_REL_ "GenSigTimeoutTime" BU_SG_REL_ ICAS1_KommunikationsServer SG_ 2463978666 MO_Verbrauch_EM_Ges_Ueberlauf 1000;
BA_REL_ "GenSigTimeoutTime" BU_SG_REL_ ICAS1_KommunikationsServer SG_ 2463978666 MO_Rekuperation_Ges_EM 1000;
BA_REL_ "GenSigTimeoutTime" BU_SG_REL_ ICAS1_KommunikationsServer SG_ 2463978666 MO_Rekuperation_EM_Ges_Ueberlauf 1000;
BA_REL_ "GenSigTimeoutTime" BU_SG_REL_ LE1 SG_ 332 MO_Fahrbereitschaft 1000;
BA_REL_ "GenSigTimeoutTime" BU_SG_REL_ LE1 SG_ 332 OBD_Calc_Load_Val 1000;
BA_REL_ "GenSigTimeoutTime" BU_SG_REL_ LE1 SG_ 332 OBD_Eng_Cool_Temp 1000;
BA_REL_ "GenSigTimeoutTime" BU_SG_REL_ LE1 SG_ 332 OBD_Abs_Throttle_Pos 1000;
BA_REL_ "GenSigTimeoutTime" BU_SG_REL_ LE1 SG_ 332 OBD_Abs_Load_Val 1000;
BA_REL_ "GenSigTimeoutTime" BU_SG_REL_ LE1 SG_ 332 OBD_Abs_Pedal_Pos 1000;
BA_REL_ "GenSigTimeoutTime" BU_SG_REL_ LE1 SG_ 332 MO_Servicemodus 1000;
BA_REL_ "GenSigTimeoutTime" BU_SG_REL_ LE1 SG_ 332 OBD_ClearMem_Inhibit 1000;
BA_REL_ "GenSigTimeoutTime" BU_SG_REL_ LE1 SG_ 332 OBD_Sperrung_Kaltstart_Denom 1000;
BA_REL_ "GenSigTimeoutTime" BU_SG_REL_ LE1 SG_ 332 OBD_Sperrung_IUMPR 1000;
BA_REL_ "GenSigTimeoutTime" BU_SG_REL_ LE1 SG_ 332 OBD_Kaltstart_Denominator 1000;
BA_REL_ "GenSigTimeoutTime" BU_SG_REL_ LE1 SG_ 332 OBD_Minimum_Trip 1000;
BA_REL_ "GenSigTimeoutTime" BU_SG_REL_ LE1 SG_ 332 OBD_Driving_Cycle 1000;
BA_REL_ "GenSigTimeoutTime" BU_SG_REL_ LE1 SG_ 332 OBD_Warm_Up_Cycle 1000;
BA_REL_ "GenSigTimeoutTime" BU_SG_REL_ LE1 SG_ 332 OBD_Normed_Trip 1000;
BA_REL_ "GenSigTimeoutTime" BU_SG_REL_ LE1 SG_ 190 Motor_56_CRC 500;
BA_REL_ "GenSigTimeoutTime" BU_SG_REL_ LE1 SG_ 190 Motor_56_BZ 500;
BA_REL_ "GenSigTimeoutTime" BU_SG_REL_ LE1 SG_ 190 MO_EM1_MinDrehzahl 500;
BA_REL_ "GenSigTimeoutTime" BU_SG_REL_ LE1 SG_ 190 MO_EM1_MaxDrehzahl 500;
BA_REL_ "GenSigTimeoutTime" BU_SG_REL_ LE1 SG_ 190 MO_EM1_DynLimit_AR 500;
BA_REL_ "GenSigTimeoutTime" BU_SG_REL_ LE1 SG_ 190 MO_EM1_Periode_AR 500;
BA_REL_ "GenSigTimeoutTime" BU_SG_REL_ LE1 SG_ 190 MO_EM1_SollMoment 500;
BA_REL_ "GenSigTimeoutTime" BU_SG_REL_ LE1 SG_ 190 MO_EM1_Sollmodus 500;
BA_REL_ "GenSigTimeoutTime" BU_SG_REL_ LE1 SG_ 190 MO_EM1_Min_Leistung 500;
BA_REL_ "GenSigTimeoutTime" BU_SG_REL_ LE1 SG_ 190 MO_EM1_Max_Leistung 500;
BA_REL_ "GenSigTimeoutTime" BU_SG_REL_ LE1 SG_ 190 MO_EM1_Min_Strom_Lim 500;
BA_REL_ "GenSigTimeoutTime" BU_SG_REL_ LE1 SG_ 190 MO_EM1_Max_Strom_Lim 500;
BA_REL_ "GenSigTimeoutTime" BU_SG_REL_ LE1 SG_ 190 MO_EM1_AR_Anf 500;
BA_REL_ "GenSigTimeoutTime" BU_SG_REL_ LE1 SG_ 190 MO_EM1_Kp_AR 500;
BA_REL_ "GenSigTimeoutTime" BU_SG_REL_ LE1 SG_ 190 MO_EM1_SollSpannung 500;
BA_REL_ "GenSigTimeoutTime" BU_SG_REL_ LE1 SG_ 190 MO_EM1_Max_Moment 500;
BA_REL_ "GenSigTimeoutTime" BU_SG_REL_ LE1 SG_ 190 MO_EM1_Min_Moment 500;
BA_REL_ "GenSigTimeoutTime" BU_SG_REL_ LE1 SG_ 2463978666 MO_EM1_Min_Spannung_Lim 1000;
BA_REL_ "GenSigTimeoutTime" BU_SG_REL_ LE1 SG_ 2463978666 MO_EM1_Max_Spannung_Lim 1000;
BA_REL_ "GenSigTimeoutTime" BU_SG_REL_ LE1 SG_ 2463978666 MO_EM1_Min_Leistung_Gesamt 1000;
BA_REL_ "GenSigTimeoutTime" BU_SG_REL_ LE1 SG_ 2463978666 MO_EM1_Max_Leistung_Gesamt 1000;
BA_REL_ "GenSigTimeoutTime" BU_SG_REL_ LE1 SG_ 2463978666 MO_EM1_Generator_Leistung 1000;
BA_REL_ "GenSigTimeoutTime" BU_SG_REL_ LE2 SG_ 332 MO_Fahrbereitschaft 1000;
BA_REL_ "GenSigTimeoutTime" BU_SG_REL_ LE2 SG_ 332 OBD_Calc_Load_Val 1000;
BA_REL_ "GenSigTimeoutTime" BU_SG_REL_ LE2 SG_ 332 OBD_Eng_Cool_Temp 1000;
BA_REL_ "GenSigTimeoutTime" BU_SG_REL_ LE2 SG_ 332 OBD_Abs_Throttle_Pos 1000;
BA_REL_ "GenSigTimeoutTime" BU_SG_REL_ LE2 SG_ 332 OBD_Abs_Load_Val 1000;
BA_REL_ "GenSigTimeoutTime" BU_SG_REL_ LE2 SG_ 332 OBD_Abs_Pedal_Pos 1000;
BA_REL_ "GenSigTimeoutTime" BU_SG_REL_ LE2 SG_ 332 MO_Servicemodus 1000;
BA_REL_ "GenSigTimeoutTime" BU_SG_REL_ LE2 SG_ 332 OBD_ClearMem_Inhibit 1000;
BA_REL_ "GenSigTimeoutTime" BU_SG_REL_ LE2 SG_ 332 OBD_Sperrung_Kaltstart_Denom 1000;
BA_REL_ "GenSigTimeoutTime" BU_SG_REL_ LE2 SG_ 332 OBD_Sperrung_IUMPR 1000;
BA_REL_ "GenSigTimeoutTime" BU_SG_REL_ LE2 SG_ 332 OBD_Kaltstart_Denominator 1000;
BA_REL_ "GenSigTimeoutTime" BU_SG_REL_ LE2 SG_ 332 OBD_Minimum_Trip 1000;
BA_REL_ "GenSigTimeoutTime" BU_SG_REL_ LE2 SG_ 332 OBD_Driving_Cycle 1000;
BA_REL_ "GenSigTimeoutTime" BU_SG_REL_ LE2 SG_ 332 OBD_Warm_Up_Cycle 1000;
BA_REL_ "GenSigTimeoutTime" BU_SG_REL_ LE2 SG_ 332 OBD_Normed_Trip 1000;
BA_REL_ "GenSigTimeoutTime" BU_SG_REL_ LE2 SG_ 190 Motor_56_CRC 500;
BA_REL_ "GenSigTimeoutTime" BU_SG_REL_ LE2 SG_ 190 Motor_56_BZ 500;
BA_REL_ "GenSigTimeoutTime" BU_SG_REL_ LE2 SG_ 190 MO_EM2_MinDrehzahl 500;
BA_REL_ "GenSigTimeoutTime" BU_SG_REL_ LE2 SG_ 190 MO_EM2_MaxDrehzahl 500;
BA_REL_ "GenSigTimeoutTime" BU_SG_REL_ LE2 SG_ 190 MO_EM2_DynLimit_AR 500;
BA_REL_ "GenSigTimeoutTime" BU_SG_REL_ LE2 SG_ 190 MO_EM2_Periode_AR 500;
BA_REL_ "GenSigTimeoutTime" BU_SG_REL_ LE2 SG_ 190 MO_EM2_SollMoment 500;
BA_REL_ "GenSigTimeoutTime" BU_SG_REL_ LE2 SG_ 190 MO_EM2_Sollmodus 500;
BA_REL_ "GenSigTimeoutTime" BU_SG_REL_ LE2 SG_ 190 MO_EM2_Min_Leistung 500;
BA_REL_ "GenSigTimeoutTime" BU_SG_REL_ LE2 SG_ 190 MO_EM2_Max_Leistung 500;
BA_REL_ "GenSigTimeoutTime" BU_SG_REL_ LE2 SG_ 190 MO_EM2_Min_Strom_Lim 500;
BA_REL_ "GenSigTimeoutTime" BU_SG_REL_ LE2 SG_ 190 MO_EM2_Max_Strom_Lim 500;
BA_REL_ "GenSigTimeoutTime" BU_SG_REL_ LE2 SG_ 190 MO_EM2_AR_Anf 500;
BA_REL_ "GenSigTimeoutTime" BU_SG_REL_ LE2 SG_ 190 MO_EM2_SollSpannung 500;
BA_REL_ "GenSigTimeoutTime" BU_SG_REL_ LE2 SG_ 190 MO_EM2_Max_Moment 500;
BA_REL_ "GenSigTimeoutTime" BU_SG_REL_ LE2 SG_ 190 MO_EM2_Min_Moment 500;
BA_REL_ "GenSigTimeoutTime" BU_SG_REL_ LE2 SG_ 2463978666 MO_EM2_Min_Leistung_Gesamt 1000;
BA_REL_ "GenSigTimeoutTime" BU_SG_REL_ LE2 SG_ 2463978666 MO_EM2_Max_Leistung_Gesamt 1000;
BA_REL_ "GenSigTimeoutTime" BU_SG_REL_ LE2 SG_ 2463978666 MO_EM2_Min_Spannung_Lim 1000;
BA_REL_ "GenSigTimeoutTime" BU_SG_REL_ LE2 SG_ 2463978666 MO_EM2_Max_Spannung_Lim 1000;
VAL_ 958 MO_StartStopp_Status 0 "System_in_diesem_KL15_Zyklus_nicht_verfuegbar" 1 "System_aktiv_keine_Freigabe_durch_StartStop_Koordinator" 2 "System_aktiv_alle_Freigaben_liegen_vor" 3 "System_aktiv_mindestens_eine_Freigabe_fehlt" ;
VAL_ 958 MO_StartStopp_Wiederstart 0 "Wiederstart_inaktiv" 1 "Wiederstart_aktiv" ;
VAL_ 958 MO_StartStopp_Motorstopp 0 "Motor_Stop_inaktiv" 1 "Motor_Stop_aktiv" ;
VAL_ 958 MO_Freig_Reku 0 "Rekuperations-Modus aus" 1 "Empfehlung Spannungsanhebung" 2 "Empfehlung Spannungsabsenkung" 3 "Rekuperationsmodus aktiv, Spannungsvariation nicht notwendig" ;
VAL_ 958 MO_Kl_75 0 "Aus" 1 "Ein" ;
VAL_ 958 MO_Kl_50 0 "aus" 1 "KL50_ein_Startausfuehrung_Fahrer" ;
VAL_ 958 MO_Gangposition 0 "Gang_N" 1 "Gang_1" 2 "Gang_2" 3 "Gang_3" 4 "Gang_4" 5 "Gang_5" 6 "Gang_6" 7 "Gang_7" 8 "Gang_8" 9 "Automat_P" 10 "Automat_Vorwaerts_S" 11 "Automat_Vorwaerts_D/E" 12 "Zwischenstellung" 13 "Gang_R" 14 "Istgang_nicht_definiert" 15 "Fehler" ;
VAL_ 958 MO_StartStopp_Fahrerwunsch 0 "Init" 1 "Stoppverbot_durch_Fahrer" 2 "Stoppfreigabe_durch_Fahrer" 3 "Stoppanforderung_durch_Fahrer" ;
VAL_ 958 MO_HYB_Fahrbereitschaft 0 "keine_Fahrbereitschaft" 1 "Fahrbereitschaft" ;
VAL_ 958 MO_Ext_E_Fahrt_aktiv 0 "Rueckmeldung_E_Taster_aus" 1 "Rueckmeldung_E_Taster_ein" ;
VAL_ 958 MO_Fahrer_bremst 0 "kein_Bremsen" 1 "Bremse_betaetigt" ;
VAL_ 958 MO_QBit_Fahrer_bremst 0 "gueltiger_Wert" 1 "Ersatz_Init_oder_Fehlerwert" ;
VAL_ 958 MO_BLS 0 "kein_Bremsen" 1 "Bremse_betaetigt" ;
VAL_ 958 MO_Konsistenz_Bremsped 0 "Bremspedalinformation_plausibel" 1 "Bremspedalinformation_unplausibel" ;
VAL_ 958 MO_Timeout_ESP 0 "Empfang_iO" 1 "Timeout" ;
VAL_ 958 MO_Klima_Eingr 0 "kein Eingriff" 1 "Klimakompressor ausschalten" 2 "Klimakompressor Leistungsreduzierung" 3 "Klimakompressor aufgrund der Heissleuchtenvorwarnung ausschalten" ;
VAL_ 958 MO_Aussp_Anlass 0 "Anlasser_darf_angesteuert_werden" 1 "Anlasser_ausspuren__Ansteuerung_nicht_moeglich" ;
VAL_ 958 MO_Freig_Anlass 0 "Start_nicht_zulaessig" 1 "Startfreigabe" ;
VAL_ 958 MO_Kuppl_schalter 0 "Schalter_sagt_ausgekuppelt" 1 "Schalter_sagt_eingekuppelt" ;
VAL_ 958 MO_Interlock 0 "Interlockschalter_nicht_betaetigt" 1 "Interlockschalter_betaetigt" ;
VAL_ 958 MO_Motor_laeuft 0 "Motor_laeuft_nicht" 1 "Motor_laeuft_autark_und_stabil_und_darf_mechanisch_belastet_werden" ;
VAL_ 958 MO_Kickdown 0 "kein_Kickdown" 1 "Kickdown" ;
VAL_ 958 MO_QBit_KL_75 0 "gueltiger_Wert" 1 "Ersatz_Init_oder_Fehlerwert" ;
VAL_ 958 MO_EKlKomLeiRed 0 "keine_Leistungsbegr" 1 "Leistungsbegr_75" 2 "Leistungsbegr_50" 3 "Leistungsbegr_25" ;
VAL_ 958 MO_Handshake_STH 0 "keine EKP-Ansteuerung durch STH-Anforderung" 1 "EKP-Ansteuerung durch STH-Anforderung" ;
VAL_ 958 MO_BKV_Unterdruckwarnung 0 "Unterdruckhaushalt_iO" 1 "Unterdruckhaushalt_niO" ;
VAL_ 958 MO_Freigabe_Segeln 0 "Segelbetrieb_nicht_freigegeben" 1 "Segelbetrieb_freigegeben" ;
VAL_ 958 MO_PTC_Status 0 "nicht_unterstuetzt" 1 "Stufe_0" 2 "Stufe_1" 3 "Stufe_2" 4 "Stufe_3" 7 "PTC_am_BCM" ;
VAL_ 958 MO_QBit_Gangposition 0 "gueltiger_Wert" 1 "Ersatz_Init_oder_Fehlerwert" ;
VAL_ 958 MO_Signalquelle_Gangposition 0 "Sensorsignal" 1 "Modellsignal" ;
VAL_ 958 MO_Remotestart_Betrieb 0 "MSG_nicht_bereit_fuer_RS_Betrieb" 1 "MSG_bereit_fuer_oder_im_RS_Betrieb" ;
VAL_ 958 MO_Remotestart_moeglich 0 "Remotestart_nicht_moeglich" 1 "Remotestart_moeglich" ;
VAL_ 958 MO_FMAus_aktiv 0 "inaktiv" 1 "Segeln_mit_Motor_aus_aktiv" ;
VAL_ 958 MO_FMAus_Startvariante 0 "kein_Motorstart" 1 "Motorstart_elektrischer_Starter" 2 "GetriebeAnschleppstart" 3 "GetriebeNotAnschleppstart" ;
VAL_ 958 MO_BMS_NV_Anf_stuetzen 0 "nicht_notwendig" 1 "notwendig" ;
VAL_ 958 MO_Zylinderabschaltung 0 "Vollmotorbetrieb_VMB" 1 "Uebergang_HMB_in_VMB" 2 "Uebergang_VMB_in_HMB" 3 "Halbmotorbetrieb_HMB" ;
VAL_ 958 MO_HYB_VM_aktiv 0 "VM_nicht_aktiv" 1 "VM_aktiv" ;
VAL_ 958 MO_StartVorauss_erfuellt 0 "Signal_nicht_bedient" 1 "StartVorauss_nicht_ueberpruefbar" 2 "StartVorauss_nicht_erfuellt" 3 "StartVorauss_erfuellt" ;
VAL_ 1631 TSK_QBit_Steigung 0 "gueltiger_Wert" 1 "Ersatz_Init_oder_Fehlerwert" ;
VAL_ 1631 TSK_QBit_Fahrzeugmasse 0 "gueltiger_Wert" 1 "Ersatz_Init_oder_Fehlerwert" ;
VAL_ 1631 MO_SpannungsAnf_02 0 "keine_Anforderung" 1 "Anforderung_Stufe_1" 2 "Anforderung_Stufe_2" 3 "Anforderung_Stufe_3" ;
VAL_ 1631 MO_DPF_reg 0 "DPF_regeneriert_nicht" 1 "DPF_regeneriert" ;
VAL_ 1631 MO_Heizstrom_EKAT 127 "Fehler" ;
VAL_ 1631 MO_Heizstrom_SCR 63 "Fehler" ;
VAL_ 1631 MO_P_Generator_ungefiltert_Anf 0 "nicht_angefordert" 1 "angefordert" ;
VAL_ 1631 TSK_Getriebeinfo 0 "Handschalter" 1 "AL_AQ_Getriebe" 2 "DL_DQ_Getriebe" 3 "CVT_Getriebe" ;
VAL_ 1631 MO_Energieinhalt_BMS 4094 "Init" 4095 "Fehler" ;
VAL_ 1631 TSK_Fahrzeugmasse_02 255 "Fehler" ;
VAL_ 1631 TSK_Steigung_02 0 "Init_oder_nicht_verbaut" 255 "Fehler" ;
VAL_ 1648 MO_ANC_Kennfeld_Anf 0 "Kennfeld_1" 1 "Uebergang_Kennfeld_2_nach_1" 2 "Uebergang_Kennfeld_1_nach_2" 3 "Kennfeld_2" ;
VAL_ 1648 MO_Bremslicht_Reku 0 "Aus" 1 "Ein" ;
VAL_ 1648 MO_StartStopp_PopUp 0 "Statuswechsel_ohne_Taster (Init)" 1 "StSt_per_Taster_deaktiviert" 2 "StSt_per_Taster_aktiviert" 3 "nicht verwendet" ;
VAL_ 1648 MO1_Sperr_Info_WFS 0 "nicht_gesperrt" 1 "gesperrt" ;
VAL_ 1648 MO1_Freigabe_Info_WFS 0 "ungueltig" 1 "gueltig" ;
VAL_ 1648 MO_EPCL 0 "EPCL_aus_kein_Text" 1 "EPCL_gelb_Stoerung" 2 "EPCL_gelb_Leistungsbeschraenkung" 3 "EPCL_rot_Fzg_sicher_abstellen" ;
VAL_ 1648 MO_Zylabsch_Texte_02 0 "ein_ZAS_generell_keine_ZAS_Anzeigen" 1 "ZAS_im_VMB" 2 "ZAS_im_ASB_1_Zyl_aktiv" 3 "ZAS_im_ASB_2_Zyl_aktiv" 4 "ZAS_im_ASB_3_Zyl_aktiv" 5 "ZAS_im_ASB_4_Zyl_aktiv" 6 "ZAS_im_ASB_5_Zyl_aktiv" 7 "ZAS_im_ASB_6_Zyl_aktiv" 8 "ZAS_im_ASB_8_Zyl_aktiv" 9 "ZAS_im_ASB_12_Zyl_aktiv" 13 "Uebergangsbetrieb" 14 "keine_ZAS_Anzeige_ggf_Stopp_Schub_Betrieb" 15 "ZAS_Stoerungs_Anzeige" ;
VAL_ 1648 MO_Fahrzeugtyp 0 "Verbrenner_Fahrzeug" 1 "Hybrid" 2 "E_Fahrzeug" 3 "E_Fahrzeug_mit_Range_Extender" 4 "Brennstoffzellenfahrzeug" 5 "tbd" 6 "tbd" 7 "tbd" ;
VAL_ 1648 MO_Abstellzeit 254 "Init" 255 "reserviert" ;
VAL_ 1648 MO_Abstellzeit_Status 0 "Abstellzeit_nicht_berechnet" 1 "Abstellzeit_berechnet" 2 "Abstellzeit_Minimalwert" 3 "Abstellzeit_ungueltig" ;
VAL_ 1648 MO1_Freigabe_Verfallsinfo_WFS 0 "verfaellt_nicht" 1 "verfaellt" ;
VAL_ 1648 MO_Hybrid_StartStopp_LED 0 "LED_aus_und_Blinken_aus" 1 "LED_ein_und_Blinken_aus" 2 "LED_ein_und_Blinken_ein_50_percent" 3 "reserviert" ;
VAL_ 1648 MO_Fehler_Zylabsch 0 "kein_Fehler" 1 "Notlauf_Vollmotorbetrieb" 2 "Notlauf_mindestens_einem_abgesch_Zylinder" ;
VAL_ 1648 MO_Anzahl_Abgesch_Zyl 0 "Vollmotorbetrieb" 1 "1_Zylinder_abgeschaltet" 2 "2_Zylinder_abgeschaltet" 3 "3_Zylinder_abgeschaltet" 4 "4_Zylinder_abgeschaltet" 5 "5_Zylinder_abgeschaltet" 6 "6_Zylinder_abgeschaltet" 7 "8_Zylinder_abgeschaltet" ;
VAL_ 1648 MO_Zylabsch_Texte 0 "keine_Texte" 1 "Zylinderabschaltung_deaktivieren" 2 "Zylinderabschaltung_aktivieren" 3 "Zylinderabschaltung_unruhig" ;
VAL_ 1648 MO_Ethanol_BS_Texte 0 "kein_Text" 1 "E85_Warm_Up" 2 "FlexFuel_Warnung_Stufe_3" 3 "Warmfahrempfehlung_MQB__FlexFuel_Warnung_Stufe_1" 4 "FlexFuel_Warnung_Stufe_2" 5 "FlexFuel_Warnung_Stufe_4" 6 "E25_Warm_Up" ;
VAL_ 1648 MO_Drehzahl_Warnung 0 "keinen_Warnhinweis_anzeigen" 1 "Warnhinweis_anzeigen" ;
VAL_ 1648 MO_obere_Drehzahlgrenze 0 "Init" ;
VAL_ 967 MO_Kuehlerluefter_MUX 0 "Kuehlerluefter_1" 1 "Kuehlerluefter_2" ;
VAL_ 967 MO_Kuehlerluefter_1 126 "Init" 127 "Fehler" ;
VAL_ 967 MO_Kuehlerluefter_2 126 "Init" 127 "Fehler" ;
VAL_ 967 MO_EFLEX_Lampe 0 "Lampe_aus" 1 "Lampe_ein" 2 "Lampe_blinkend" 3 "Lampe_blinkend_mit_Akustik" ;
VAL_ 967 MO_KJS_nicht_bereit 0 "kein_Fehler" 1 "Fehler" ;
VAL_ 967 MO_ITM_Warnung_Pumpe 0 "keine_Warnung" 1 "ITM_Warnung" ;
VAL_ 967 WIV_Anzeige_aktiv 0 "Anzeige aus" 1 "WIV Anzeige aktiv" ;
VAL_ 967 WIV_Oelmin_Warn 0 "in_Ordnung" 1 "Warnung" ;
VAL_ 967 WIV_Sensorfehler 0 "in_Ordnung" 1 "Sensor_defekt" ;
VAL_ 967 WIV_Schieflage 0 "Fahrzeug_gerade" 1 "Fahrzeug_in_Schieflage" ;
VAL_ 967 MO_Zustand_HWP 0 "HWP_nicht_schaltbar" 1 "HWP_foerdert_nicht" 2 "HWP_foerdert" 3 "reserviert" ;
VAL_ 967 OLEV_Systemstoerung 0 "Ölsystem i.O." 1 "Systemstörung Ölsystem" ;
VAL_ 967 MO_Oelwarnung_max 0 "keine_Warnung" 1 "Warnfall_aktiv" ;
VAL_ 967 WIV_Oelsystem_aktiv 0 "Anzeige_aus" 1 "Anzeige_aktiv" ;
VAL_ 967 WIV_nicht_betriebswarm 0 "Motor_warm" 1 "Motor_nicht_betriebswarm" ;
VAL_ 967 WIV_Ueberfuell_Warn 0 "in_Ordnung" 1 "Ueberfuellwarnung" ;
VAL_ 967 WIV_laufender_Motor 0 "Messung_moeglich" 1 "Messung_nicht_moeglich" ;
VAL_ 967 MO_E_Warnungen 0 "keine_Anzeige" 1 "Fehler_Elektrosystem_Anhalten" 2 "Fehler_Elektrosystem_Werkstatt" 3 "Elektrosystem_ueberhitzt_Stopp" 4 "Fehler_Hybridsystem_Anhalten" 5 "Fehler_Hybridsystem_Werkstatt" 6 "Fehler_Wasserstoffsystem_Anhalte" 7 "Fehler_Wasserstoffsystem_Werksta" 8 "reserviert_keine_Anzeige" 9 "reserviert_keine_Anzeige" 10 "reserviert_keine_Anzeige" 11 "reserviert_keine_Anzeige" 12 "reserviert_keine_Anzeige" 13 "reserviert_keine_Anzeige" 14 "reserviert_keine_Anzeige" 15 "reserviert_keine_Anzeige" ;
VAL_ 967 MO_Text_Motorstart 0 "keine_Anzeige" 1 "Motor_im_Stoppbetrieb" 2 "StartStopp_sicherheitsbedingt_deaktiviert" 3 "System_fordert_Wiederstart" 4 "Aufforderung_Motorstart" 5 "Motorlauf_noetig" 6 "Motorlaufwarnung" 9 "Unerwuenschter_Motorstillstand" 10 "Motorstart_nicht_moeglich" 11 "Fehler_Kupplungsschalter" 12 "Motor_startet" 13 "Kupplung_betaetigen" 14 "Waehlhebel_in_PN_Position" 15 "Bremse_treten" ;
VAL_ 967 MO_E_Texte 0 "keine_Anzeige" 1 "Batterie_fast_leer" 2 "Ladestecker_nicht_fahrbereit" 3 "VM_Betrieb_erforderlich" 4 "Batterie_laedt_Nicht_ausschalten" 5 "Bitte_Bremse_treten" 6 "manueller_Neustart_erforderlich" 7 "Stopp_Fahrzeug_nicht_abschleppen" 8 "kein_Neustart_Haube_nicht_oeffnen" 9 "Motorstart_im_naechsten_Zyklus" 10 "VM_erforderlich_EVMode_abwaehlen" 11 "laengerer_VMBetrieb_Bordbuch" 12 "Tank_leer_VM_nicht_verfuegbar" 13 "Bitte_warten_Motor_startet" 14 "kein_Start_Batterietemperatur" 15 "Ende_elektrische_Reichweite_erreicht" ;
VAL_ 967 WIV_Oeldyn_avl 0 "Oeldyn_nicht_vorhanden" 1 "Oeldyn_vorhanden" ;
VAL_ 967 OLEV_Oelstand_nicht_vorhanden 0 "Ölstand vorhanden" 1 "Ölstand nicht vorhanden" ;
VAL_ 967 MO_Systemlampe 0 "Lampe aus" 1 "Lampe ein" ;
VAL_ 967 MO_OBD2_Lampe 0 "Lampe aus" 1 "Lampe ein" ;
VAL_ 967 MO_Heissleuchte 0 "Lampe aus" 1 "Lampe ein" ;
VAL_ 967 MO_Partikel_Lampe 0 "Lampe aus" 1 "Lampe ein" ;
VAL_ 967 MO_RedFahrleistung_Lampe 0 "Lampe_aus" 1 "Lampe_ein" ;
VAL_ 967 WIV_Oelstand_nicht_vorhanden 0 "Ölstand vorhanden" 1 "Ölstand nicht vorhanden" ;
VAL_ 967 WIV_nachfuellanzeige_ein 0 "keine_Nachfuellanzeige" 1 "Nachfuellanzeige" ;
VAL_ 967 WIV_Ueberfuell_deaktiv 0 "Ueberfuellwarnung_am_Kombi_aktiv" 1 "Ueberfuellwarnung_am_Kombi_deaktiv" ;
VAL_ 967 WIV_Unterfuell_Warn 0 "in_Ordnung" 1 "Unterfuellwarnung" ;
VAL_ 967 MO_Tankdeckel_Lampe 0 "Lampe aus" 1 "Lampe ein" ;
VAL_ 967 MO_Text_Tankdeckelwarn 0 "kein_Text" 1 "Anzeige_Text_Tankdeckelwarnung_im_Kombi" ;
VAL_ 967 MO_Vorglueh_Lampe 0 "Lampe_aus" 1 "Lampe_ein" ;
VAL_ 967 WIV_Oeldr_Warn_Motor 0 "keine_Warnung" 1 "niedrige_Oeldruckstufe_nicht_erreicht" ;
VAL_ 967 MO_E_Mode 0 "keine_Anzeige" 1 "E_Mode_passiv" 2 "E_Mode_aktiv" 3 "E_Mode_inaktiv_nicht_verfuegbar" 4 "E_Mode_aktiv_nicht_verfuegbar" 5 "reserviert_keine_Anzeige" 6 "reserviert_keine_Anzeige" 7 "reserviert_keine_Anzeige" ;
VAL_ 706 MO_Anzeige_StSt_Text 0 "keine_Anzeige" 1 "Systemfehler" 2 "Motor_manuell_starten" 3 "Rueckmeldung_durch_Fahrstufe_einlegen" 4 "Zuendungsabschaltwarnung_Timerstart" 5 "Zum_Motorstart_Bremse_treten" 6 "StSt_Aktivierung_nicht_moeglich_auf_Grund_Fahrprogramm" ;
VAL_ 706 MO_Anzeige_StSt_Symbol 0 "keine_Anzeige" 1 "StSt_aktiv" 2 "Motorlauf_noetig" 3 "Fahrer_temporaer_abwesend" ;
VAL_ 706 MO_ADR_Status 0 "nicht_aktiv" 1 "ADR_angefordert" 2 "ADR_aktiv" 3 "ADR_Fehler" ;
VAL_ 706 MO_AGA_Sound_Texte 0 "keine_Anzeige" 1 "Sound_off" 2 "Sound_on" ;
VAL_ 706 MO_Anzeige_FMAus_Text 0 "keine_Anzeige" 1 "FMAus_Systemfehler" ;
VAL_ 706 PEA_Texte 0 "Keine_Anzeige" 1 "PEA_Fahreruebernahme_noetig" 2 "PEA_Reku_nicht_verfuegbar" ;
VAL_ 706 TSK_Ueberstimmt_vMax_FahrerInfo 0 "nicht_ueberstimmbar" 1 "ueberstimmbar" 2 "ueberstimmt" ;
VAL_ 706 MO_Rekuperationsstufe 0 "keine_Anzeige" 1 "Rekuperationsstufe_1" 2 "Rekuperationsstufe_2" 3 "Rekuperationsstufe_3" 4 "Rekuperationsstufe_4" 5 "Rekuperationsstufe_5" 6 "Rekuperationsstufe_auto" 7 "Init" ;
VAL_ 706 TSK_Einheit_vMax_FahrerInfo 0 "km_h" 1 "mph" ;
VAL_ 706 TSK_Status_vMax_FahrerInfo 0 "keine_Anzeige" 1 "Anzeige_im_Fahrzeugstatus" 2 "PopUp_ohne_Gong__Eintrag_FhzStat" 3 "PopUp_mit_Gong__Eintrag_FhzStat" ;
VAL_ 706 MO_Anz_Kuehlerluefter 0 "Kein_KuehlerluefterNachlauf" 1 "Text_Luefternachlauf_aktiv" 2 "Text_Luefternachlauf_DPF_aktiv" 3 "Platzhalter_weitere_Signale" 4 "Platzhalter_weitere_Signale" 5 "Platzhalter_weitere_Signale" 6 "Platzhalter_weitere_Signale" 7 "Platzhalter_weitere_Signale" ;
VAL_ 706 FDR_Warnung_ALR 0 "keine_Anzeige" 1 "Text_Stoerung_Allradverteilung" 2 "Text_Ausfall_Allradverteilung" 3 "reserved" ;
VAL_ 706 TSK_vMax_FahrerInfo 0 "Init___kein_Wert" ;
VAL_ 267 MO_Fahrpedalrohwert_01 255 "Fehler" ;
VAL_ 267 MO_QBit_Fahrpedalwerte_01 0 "gueltiger_Wert" 1 "Ersatz_Init_oder_Fehlerwert" ;
VAL_ 267 MO_Fahrpedalgradient 255 "Fehler" ;
VAL_ 267 MO_Sig_Fahrpedalgradient 0 "Fahrpedalgradient positiv" 1 "Fahrpedalgradient negativ" ;
VAL_ 267 MO_rel_Saugrohrdruck 0 "Init_Ueberdruck" 63 "Fehler" ;
VAL_ 267 MO_rel_Saugrohrdruck_gem_err 0 "errechnet" 1 "gemessen" ;
VAL_ 267 MO_Moment_im_Leerlauf 0 "kein_Leergas" 1 "Leergas" ;
VAL_ 267 MO_Schubabschaltung 0 "keine_Schubabschaltung" 1 "Schubabschaltung_aktiv" ;
VAL_ 267 MO_Entkopplung_Sollschlupf 125 "Notoeffnen_Anfahrelement" 126 "Init" ;
VAL_ 267 MO_temporaere_Fahrerabwesenheit 0 "nicht_erkannt" 1 "erkannt" ;
VAL_ 267 TSK_a_Soll_gradientenbegrenzt 127 "Init_oder_nicht_aktiv" ;
VAL_ 267 TSK_Status 0 "Hauptschalter_aus" 1 "Init" 2 "passiv" 3 "aktiv" 4 "Uebertreten" 5 "brake_only_Mode" 6 "reversibel_aus" 7 "irreversibel_aus" ;
VAL_ 267 TSK_v_Begrenzung_aktiv 0 "inaktiv" 1 "aktiv" ;
VAL_ 267 TSK_Standby_Anf_ESP 0 "keine_Standby_Anforderung" 1 "Standby_Anforderung" ;
VAL_ 267 TSK_Freig_WU 0 "TSK_Uebersetzungswunsch_nicht_freigegeben" 1 "TSK_Uebersetzungswunsch_freigegeben" ;
VAL_ 267 TSK_Freig_Verzoeg_Anf 0 "Verzoegerungsanforderung_nicht_freigegeben" 1 "Verzoegerungsanforderung_freigegeben" ;
VAL_ 267 TSK_Limiter_ausgewaehlt 0 "kein_Limiter_ausgewaehlt" 1 "Limiter_ausgewaehlt" ;
VAL_ 267 TSK_Wunsch_Uebersetz 0 "Init" ;
VAL_ 267 TSK_Hauptschalter_GRA_ACC 0 "Init" 1 "Aus" 2 "Ein" 3 "Fehler" ;
VAL_ 267 TSK_SRBM_Anf_ASIL 0 "keine_SRBM_Anforderung" 1 "SRBM_Anforderung_in_ASIL_QM" 2 "SRBM_Anforderung_in_ASIL_A" 3 "SRBM_Anforderung_in_ASIL_B" 4 "SRBM_Anforderung_in_ASIL_C" ;
VAL_ 267 TSK_ax_Getriebe_02 511 "Neutralwert" ;
VAL_ 267 TSK_Zwangszusch_ESP 0 "keine_ESP_ASR_Beeinflussung" 1 "ESP_ASR_Beeinflussung" ;
VAL_ 267 MO_Status_MinDrzEingriff 0 "kein_Eingriff" 1 "Schalteingriff" 2 "ESP_Eingriff" 3 "Achsdifferenzdrehzahl" 4 "Bauteilschutz" 5 "Rennstart" ;
VAL_ 267 MO_Status_MaxDrzEingriff 0 "kein_Eingriff" 1 "Schalteingriff" 2 "ESP_Eingriff" 3 "Achsdifferenzdrehzahl" 4 "Bauteilschutz" 5 "Rennstart" ;
VAL_ 267 MO_Status_MinDrzEingriff_sek 0 "kein_Eingriff" 1 "Schalteingriff" 2 "ESP_Eingriff" 3 "Achsdifferenzdrehzahl" 4 "Bauteilschutz" 5 "Rennstart" ;
VAL_ 267 MO_Status_MaxDrzEingriff_sek 0 "kein_Eingriff" 1 "Schalteingriff" 2 "ESP_Eingriff" 3 "Achsdifferenzdrehzahl" 4 "Bauteilschutz" 5 "Rennstart" ;
VAL_ 267 GRA_KuFu_aktiv 0 "inaktiv" 1 "aktiv" ;
VAL_ 267 TSK_SRBM_max_Gradient 126 "Init" 127 "Fehler" ;
VAL_ 267 LIM_KuFu_aktiv 0 "inaktiv" 1 "aktiv" ;
VAL_ 330 MO_Hochschaltdrehz 0 "keine_manuelle_Hochschaltung" 4095 "Fehler" ;
VAL_ 330 MO_Anzeige_Verbr_Einheit 0 "l_h" 1 "kg_h" ;
VAL_ 330 MO_Schaltblitz_Anz 101 "blinkende_Anzeige" 126 "Init_Funktion_nicht_aktiv" 127 "Fehler" ;
VAL_ 330 MO_Anzeige_Drehmoment 2046 "nicht_verbaut" 2047 "Fehler" ;
VAL_ 330 MO_Anzeige_Leistung 2046 "nicht_verbaut" 2047 "Fehler" ;
VAL_ 330 MO_rel_Ladedruck 255 "Fehler" ;
VAL_ 330 MO_Istgang 0 "kein_Gang_eingelegt" 1 "Gang_1" 2 "Gang_2" 3 "Gang_3" 4 "Gang_4" 5 "Gang_5" 6 "Gang_6" 7 "Gang_7" 8 "Gang_8" 9 "Gang_9" ;
VAL_ 330 MO_Sollgang 0 "keine_Empfehlung" 1 "Gang_1" 2 "Gang_2" 3 "Gang_3" 4 "Gang_4" 5 "Gang_5" 6 "Gang_6" 7 "Gang_7" 8 "Gang_8" 9 "Gang_9" 15 "Neutralgang" ;
VAL_ 330 MO_Oeldruck 254 "Init" 255 "Fehler" ;
VAL_ 330 MO_Anzeigedrehz 4095 "reserviert" ;
VAL_ 330 MO_Effizienzmodus 0 "nicht_im_Effizienz_Modus" 1 "Effizienz_Modus" ;
VAL_ 330 MO_Fehler_Oeldrucksensor 0 "kein_Fehler" 1 "Fehler" ;
VAL_ 330 MO_Schaltempf_verfbar 0 "nicht_verfuegbar" 1 "verfuegbar" ;
VAL_ 330 MO_Ladedruck 511 "Fehler" ;
VAL_ 330 MO_KVS_Ueberlauf 0 "kein Ueberlauf" 1 "Kraftstoffverbrauchsignale mindestens 1x übergelaufen" ;
VAL_ 330 MO_ePowermeter 0 "Init_keine_Anzeige" 254 "Funktion_deaktiv_Anzeige_ausgegraut" 255 "Fehler_keine_Anzeige" ;
VAL_ 330 MO_ePerformance 0 "Init" 254 "Funktion_deaktiv_Anz_ausgegraut" 255 "Fehler" ;
VAL_ 330 MO_Zust_Antrieb 0 "VKM aktiv" 1 "EM aktiv" 2 "VKM und EM aktiv" 3 "Segeln oder Reku aktiv" ;
VAL_ 330 MO_Zust_Betriebsstrategie 0 "Kein Hybrid" 1 "Depleting" 2 "Soft-Depleting " 3 "Sustaining" 4 "Increasing" 5 "Fremdgesteuert" ;
VAL_ 330 Ladezustand_02 254 "Init" 255 "Fehler" ;
VAL_ 330 MO_Powermeter_Elm_02 0 "nicht_verbaut" 4094 "Init" ;
VAL_ 330 MO_Powermeter 4093 "Off" ;
VAL_ 512 TSK_Wunschgeschw 1022 "keine_Anzeige" 1023 "kein_Wert_im_Speicher" ;
VAL_ 512 TSK_praediktiver_Hinweis 0 "keine_Anzeige" 1 "Vorschlag_zur_Bestaetigung" 2 "Hinweis_neuer_Setzwert" 3 "Regelung_im_Uebergang" ;
VAL_ 512 TSK_naechstes_Event 0 "Init" 1 "Tempolimit_5" 2 "Tempolimit_10" 3 "Tempolimit_15" 4 "Tempolimit_20" 5 "Tempolimit_25" 6 "Tempolimit_30" 7 "Tempolimit_35" 8 "Tempolimit_40" 9 "Tempolimit_45" 10 "Tempolimit_50" 11 "Tempolimit_55" 12 "Tempolimit_60" 13 "Tempolimit_65" 14 "Tempolimit_70" 15 "Tempolimit_75" 16 "Tempolimit_80" 17 "Tempolimit_90" 18 "Tempolimit_100" 19 "Tempolimit_110" 20 "Tempolimit_120" 21 "Tempolimit_130" 22 "Tempolimit_140" 23 "Tempolimit_150" 24 "Tempolimit_160" 25 "Tempolimit_unbegrenzt" 26 "Linkskurve" 27 "Rechtskurve" 28 "Kuppe" 29 "Steigung" 30 "Gefaelle" 31 "Kreuzung" 32 "Ampel" 33 "Bahnuebergang" 34 "Ortsanfang" 35 "Kreisverkehr" 36 "naechstes_Limit_ausserh_Verfueg" ;
VAL_ 512 TSK_Fahrzeugstatus_praed_Fkt 0 "init" 1 "Praed_Fkt_verfuegbar" 2 "Praed_Fkt_eingeschraenkt_verfueg" 3 "Praed_Fkt_nicht_verfuegbar" 4 "Praed_Fkt_Land_nicht_verfuegbar" ;
VAL_ 512 TSK_Texte 0 "kein_Text" 1 "GRA_Modus_ausgewaehlt" 2 "ACC_Modus_ausgewaehlt" 3 "Lim_Modus_ausgewaehlt" 4 "Lim_nicht_verfuegbar_ESC_passiv" 5 "GRA_nicht_verfuegbar_ESC_passiv" 6 "Lim_nicht_verfuegbar_Charisma" 7 "GRA_nicht_verfuegbar_Charisma" 8 "Lim_nicht_verfuegbar_HDC" 9 "GRA_nicht_verfuegbar_HDC" 10 "P_GRA_Modus_ausgewaehlt" 11 "P_LIM_Modus_ausgewaehlt" 12 "Bremse_ueberhitzt" ;
VAL_ 512 TSK_Akustik 0 "keine_Akustik" 1 "einzelner_Warnton" 2 "dauerhafter_Warnton" ;
VAL_ 512 TSK_Texte_Primaeranz 0 "keine_Anzeige" 1 "GRA_Symbol_passiv_xxx_kmh_mph" 2 "GRA_Symbol_aktiv_xxx_kmh_mph" 3 "Bremse_ueberhitzt" 4 "Limiter_Modus_aktiviert" 5 "GRA_Modus_aktiviert" 6 "ACC_Modus_aktiviert" 7 "Opt_Geschwindigkeitswarnung" 8 "Opt_und_akustische_GeschwWarnung" 9 "Opt_GeschwWarnung_dauerhaft_mit_einmal_Akustik" 10 "Limiter_passiv_mit_Akustik" 11 "Limiter_Fehler_mit_Akustik" 12 "Limiter_Symbol_passiv_xxx_kmh_mph" 13 "Limiter_Symbol_aktiv_xxx_kmh_mph" 14 "Popup_Geschw_zu_hoch__Resume_unzulaessig" ;
VAL_ 512 TSK_Limiter_Fahrerinfo 0 "keine_Info" 1 "Limit_erreicht" 2 "Ueberschritten" 3 "Vom_Fahrer_Ueberstimmt" ;
VAL_ 512 TSK_Limiter_Anzeige 0 "Display_Anzeige_GRA_ACC" 1 "Display_Anzeige_Limiter" ;
VAL_ 512 TSK_Fahrzeugstatus_GRA 0 "GRA_verfuegbar" 1 "GRA_nicht_verfuegbar" ;
VAL_ 512 TSK_Fahrzeugstatus_Limiter 0 "Limiter_verfuegbar" 1 "Limiter_nicht_verfuegbar" ;
VAL_ 512 MO_Motorlaufwarnung 0 "keine_Anzeige" 1 "Anforderung_Motorlaufwarnung" ;
VAL_ 512 TSK_naechstes_Event_Einheit 0 "kmh" 1 "mph" ;
VAL_ 512 TSK_Status_Anzeige 0 "Hauptschalter_aus" 1 "Init" 2 "passiv" 3 "aktiv" 4 "Uebertreten" 5 "Limitiierung_aktiv" 6 "reversibel_aus" 7 "irreversibel_aus" ;
VAL_ 512 MO_Sperrung_FahrPr_BZS 0 "keine Sperrung" 1 "Sperrung BZS1" 2 "Sperrung BZS2" 4 "Sperrung BZS3" 8 "Sperrung BZS4" 16 "Sperrung BZS5" 32 "Sperrung BZS6" 64 "Sperrung BZS7" 128 "Sperrung BZS8" ;
VAL_ 512 MO_Rampenzeit_Generator_Anf 0 "0_sec" 1 "1_sec" 2 "2_sec" 3 "3_sec" 4 "4_sec" 5 "5_sec" 6 "6_sec" 7 "7_sec" 8 "8_sec" 9 "9_sec" 10 "reserviert" 11 "reserviert" 12 "reserviert" 13 "reserviert" 14 "reserviert" 15 "keine_Anforderung" ;
VAL_ 512 MO_Prio_MAX_Wunschdrehzahl 0 "Wunsch" 1 "Zwang" ;
VAL_ 512 MO_Prio_MIN_Wunschdrehzahl 0 "Wunsch" 1 "Zwang" ;
VAL_ 512 MO_Luftpfad_aktiv 0 "kein Eingriff oder nur Eingriff über Zündpfad" 1 "Eingriff über Luftpfad" ;
VAL_ 512 MO_v_Begrenz_Aktivierbar 0 "V-Begrenzung nicht möglich" 1 "V-Begrenzung möglich" ;
VAL_ 512 MO_Charisma_FahrPr 0 "keine_Funktion" 1 "Programm_1" 2 "Programm_2" 3 "Programm_3" 4 "Programm_4" 5 "Programm_5" 6 "Programm_6" 7 "Programm_7" 8 "Programm_8" 9 "Programm_9" 10 "Programm_10" 11 "Programm_11" 12 "Programm_12" 13 "Programm_13" 14 "Programm_14" 15 "Programm_15" ;
VAL_ 512 MO_Charisma_Status 0 "Init" 1 "verfuegbar" 2 "nicht_verfuegbar" 3 "asynchron_durch_Fahrerwunsch" ;
VAL_ 512 MO_StSt_Charisma_FahrPr 0 "keine_Funktion" 1 "Programm_1" 2 "Programm_2" 3 "Programm_3" 4 "Programm_4" 5 "Programm_5" 6 "Programm_6" 7 "Programm_7" 8 "Programm_8" 9 "Programm_9" 10 "Programm_10" 11 "Programm_11" 12 "Programm_12" 13 "Programm_13" 14 "Programm_14" 15 "Programm_15" ;
VAL_ 512 MO_StSt_Charisma_Status 0 "Init" 1 "verfuegbar" 2 "nicht_verfuegbar" 3 "asynchron_durch_Fahrerwunsch" ;
VAL_ 512 MO_BZS_Charisma_FahrPr 0 "keine_Funktion" 1 "Programm_1" 2 "Programm_2" 3 "Programm_3" 4 "Programm_4" 5 "Programm_5" 6 "Programm_6" 7 "Programm_7" 8 "Programm_8" 9 "Programm_9" 10 "Programm_10" 11 "Programm_11" 12 "Programm_12" 13 "Programm_13" 14 "Programm_14" 15 "Programm_15" ;
VAL_ 512 MO_BZS_Charisma_Status 0 "Init" 1 "verfuegbar" 2 "nicht_verfuegbar" 3 "asynchron_durch_Fahrerwunsch" ;
VAL_ 512 MO_NGS_Position 0 "Neutralposition_nicht_erkannt" 1 "Neutralposition_erkannt" ;
VAL_ 512 MO_NGS_Status 0 "nicht_verbaut" 1 "nicht_plausibilisiert" 2 "plausibilisiert" 3 "Fehler" ;
VAL_ 512 MO_v_Begrenzung_Niveau 0 "keine_Begrenzung_aktiv" 1 "Sicherheitsbegrenzung_1_aktiv" 2 "Sicherheitsbegrenzung_2_aktiv" 3 "Komfortbegrenzung_aktiv" ;
VAL_ 512 MO_Anzeige_Rekuperation 0 "Init_und_nicht_verbaut" ;
VAL_ 512 PEA_Fortschrittsanzeige 127 "Neutralwert" ;
VAL_ 512 MO_Anzeige_Fahrbereitschaft 0 "OFF" 1 "READY" ;
VAL_ 512 MO_Boost_verfuegbar 0 "Init" 253 "Nicht_verbaut" 254 "Funktion_deaktiv" 255 "Fehler" ;
VAL_ 512 MO_Overboost 0 "inaktiv" 1 "aktiv" ;
VAL_ 512 MO_Boost_aktiv 0 "kein_Boost_aktiv" 1 "Boost_aktiv" ;
VAL_ 512 MO_Anzeige_Betriebsmodus 0 "Init_keine_Anzeige" 1 "EV" 2 "Auto" 3 "Hold" 4 "Charge" 5 "GTE" 6 "ECO" 7 "SPORT" 8 "Auto_praediktiv" 9 "Manuell_SOC_erhoehen" 10 "Manuell_SOC_halten" 11 "Manuell_SOC_verringern" ;
VAL_ 512 PEA_Hinweis 0 "keine_Anzeige" 1 "Anzeige_Fusssymbol_1" 2 "Anzeige_Fusssymbol_2" 3 "Anzeige_Auskuppeln" ;
VAL_ 512 PEA_Ereignisanzeige 0 "keine_Anzeige" 1 "Linkskurve_voraus" 2 "Rechtskurve_voraus" 3 "Kreuzung_voraus" 4 "Gefaelle_voraus" 5 "Kreisverkehr_voraus" 6 "Fahrzeug_voraus" 7 "Tempolimit_voraus" 8 "Ereignis_voraus" 9 "Autobahnabfahrt_voraus" 10 "Autobahnauffahrt_voraus" 11 "Abbiegung_links_voraus" 12 "Abbiegung_rechts_voraus" 13 "Ortseinfahrt_voraus" 14 "Autobahnabfahrt_links_voraus" ;
VAL_ 512 PEA_Ereignisanzeige_temporaer 0 "keine_Anzeige" 1 "Anzeige_temporaer" ;
VAL_ 512 PEA_Abschalttexte 0 "keine_Anzeige" 1 "PEA_ausserhalb_Einsatzgebiet" 2 "PEA_temporaer_nicht_verfuegbar" 3 "PEA_vom_Fahrer_deaktiviert" ;
VAL_ 512 PEA_Zielgeschw_Einheit 0 "km_h" 1 "mph" ;
VAL_ 512 PEA_Zielgeschw 0 "keine_Anzeige" 1 "Wert_5" 2 "Wert_10" 3 "Wert_15" 4 "Wert_20" 5 "Wert_25" 6 "Wert_30" 7 "Wert_35" 8 "Wert_40" 9 "Wert_45" 10 "50" 11 "Wert_55" 12 "Wert_60" 13 "Wert_65" 14 "Wert_70" 15 "Wert_75" 16 "Wert_80" 17 "Wert_85" 18 "Wert_90" 19 "Wert_95" 20 "Wert_100" 21 "Wert_105" 22 "Wert_110" 23 "Wert_115" 24 "Wert_120" 25 "Wert_125" 26 "Wert_130" 27 "Wert_140" 28 "Wert_150" 29 "Wert_160" ;
VAL_ 512 MO_Antriebsstrang_Warnung_HS 0 "Keine_Anzeige" 1 "Fehlereskalationsstufe_I" 2 "Fehlereskalationsstufe_II" 3 "Fehlereskalationsstufe_III" ;
VAL_ 332 MO_Anforderung_HMS 0 "keine_Anforderung" 1 "halten" 2 "parken" 3 "halten_Standby" 4 "anfahren" 5 "Loesen_ueber_Rampe" ;
VAL_ 332 FoD_DTC_TSK_GRA 0 "Kein_DTC" 1 "DTC_vorhanden_oder_in_Quali" ;
VAL_ 332 TSK_vMax_aktuell 254 "kein_Limit_aktiv" 255 "Init" ;
VAL_ 332 TSK_Status_EA 0 "Aus" 1 "Init_oder_nicht_verbaut" 3 "Aktiv" 4 "Uebertreten" 5 "Abschaltung_laeuft" 6 "Reversibel_aus" 7 "Fehler" ;
VAL_ 332 FoD_DTC_TSK_ACC 0 "Kein_DTC" 1 "DTC_vorhanden_oder_in_Quali" ;
VAL_ 332 TSK_ACC_FoD_Status 0 "default" 1 "nicht_aktiv" 2 "aktiv" 3 "nicht_genutzt" ;
VAL_ 332 TSK_GRA_FoD_Status 0 "default" 1 "nicht_aktiv" 2 "aktiv" 3 "nicht_genutzt" ;
VAL_ 332 TSK_vMax_Fahrerassistenz 511 "Init_ungueltig_keine_Beschraenkung" ;
VAL_ 332 TSK_Einheit_vMax_Fahrerassistenz 0 "kmh" 1 "mph" ;
VAL_ 332 TSK_Status_PLA 0 "Aus_Funktionsbereit" 1 "Init_oder_nicht_verbaut" 2 "aktivierbar" 3 "aktiv" 5 "Abschaltung_laeuft" 6 "reversibel_aus" 7 "Fehler" ;
VAL_ 332 TSK_aktives_System 0 "keine_Funktion_aktiv" 1 "GRA_ACC" 2 "ARA" 3 "Speedlimiter" 4 "IPA" 5 "PLA" 6 "PEA_Ausrollassistent" 7 "EA" ;
VAL_ 332 TSK_erhoehter_Fahrwiderstand 0 "kein_erhoehter_Fahrwiderstand" 1 "erhoehter_Fahrwiderstand" ;
VAL_ 332 TSK_Anf_Antriebsmoment 0 "keine_Anforderung" 1 "Anforderung_aktiv" ;
VAL_ 332 TSK_Status_ARA 0 "Aus" 1 "Init_oder_nicht_verbaut" 2 "aktivierbar" 3 "aktiv" 5 "abschaltung_laeuft" 6 "reversibel_aus" 7 "Fehler" ;
VAL_ 332 TSK_Status_IPA 0 "Aus_Funktionsbereit" 1 "Init_oder_nicht_verbaut" 2 "aktivierbar" 3 "aktiv" 4 "Fahreruebernahme_angefordert" 5 "Abschaltung_laueft" 6 "reversibel_aus" 7 "Fehler" ;
VAL_ 332 MO_Fahrbereitschaft 0 "Fahrzykl_inaktiv__kein_Antrieb" 1 "Fahrzykl_aktiv__kein_Antrieb" 2 "Fahrzykl_aktiv__Antrieb_moeglich" ;
VAL_ 332 MO_Freilauf_Info 0 "Freilauf_freigegeben" 1 "Uebergang_in_Freilauf_unzulaessig" 2 "Freilauf_nicht_freigegeben_Abbruch" 3 "Freilauf_Anforderung" ;
VAL_ 332 MO_Krit_Heckobjekt 0 "Init_kein_relevantes_Objekt" 1 "Entfernung_grosser_Abstand" 2 "Annaeherung_grosser_Abstand" 3 "Entfernung_geringer_Abstand" 4 "Annaeherung_geringer_Abstand" 7 "Fehler" ;
VAL_ 332 MO_NGS_Gangpos 0 "nicht_bedient" 1 "1_3_oder_5" 2 "2_4_6_oder_R" 3 "R" 4 "Neutralposition" 5 "Zwischenposition" 6 "Sensor_temp_nicht_verfuegbar" 7 "Fehler" ;
VAL_ 332 MO_Freilauf_Status 0 "Freilauf_inaktiv_aber_moeglich" 1 "Freilauf_aktiv" 2 "Freilauf_nicht_moegl_1Verhinderer" 3 "Freilauf_nicht_moegl_gr_1Verhinderer" 7 "Fehler" ;
VAL_ 332 MO_EBoost_verf_praed 0 "Init_oder_nicht_verfuegbar" 1 "EBoost_kurzzeit_verfuegbar" 2 "EBoost_langzeit_verfuegbar" ;
VAL_ 332 MO_Heckspoiler_Anf 0 "nicht_angefordert" 1 "angefordert" ;
VAL_ 332 MO_eLaunch_verf 0 "Init" 1 "nicht_verfuegbar" 2 "verfuegbar" ;
VAL_ 332 MO_Positionierung_aktiv 0 "keine_Positionierung_aktiv" 1 "Positionierung_aktiv" ;
VAL_ 332 MO_Freilauf_Typ 0 "Koordinator_GSG" 1 "Koordinator_MSG" 2 "Koordinator_GSG_mit_FP_Grad" ;
VAL_ 332 MO_Startwunsch 0 "kein_Startwunsch" 1 "Startwunsch" ;
VAL_ 332 MO_Servicemodus 0 "nicht_aktiv" 1 "Service_Mode_1" 2 "Service_Mode_2" 3 "Service_Mode_3" 4 "Service_Mode_4" 5 "Service_Mode_5" 6 "Service_Mode_6" 7 "Service_Mode_7" 8 "Service_Mode_8" 9 "Service_Mode_9" 10 "Service_Mode_10" 11 "Service_Mode_11" 12 "Service_Mode_12" 13 "Service_Mode_13" 14 "Service_Mode_14" 15 "Service_Mode_15" ;
VAL_ 332 OBD_ClearMem_Inhibit 0 "FSP_Loeschen_zulaessig" 1 "FSP_Loeschen_nicht_zulaessig" ;
VAL_ 332 OBD_Sperrung_Kaltstart_Denom 0 "EVAP_Berechnung_freigegeben" 1 "EVAP_Berechnung_gesperrt" ;
VAL_ 332 MO_QBit_Aussen_Temp 0 "gueltiger_Wert" 1 "Ersatz_Init_oder_Fehlerwert" ;
VAL_ 332 OBD_Sperrung_IUMPR 0 "IUMPR_Berechnung_freigegeben" 1 "IUMPR_Berechnung_gesperrt" ;
VAL_ 332 OBD_Kaltstart_Denominator 0 "Denominator_nicht_hochzaehlen" 1 "Bedingungen_zum_Inkr_des_Kaltstart_Denom_erf" ;
VAL_ 332 OBD_Minimum_Trip 0 "kein_Min_Normed_Trip" 1 "Min_Normed_Trip" ;
VAL_ 332 OBD_Driving_Cycle 0 "kein Driving Cycle erkannt" 1 "DC erkannt" ;
VAL_ 332 OBD_Warm_Up_Cycle 0 "kein Warm Up Cycle erkannt" 1 "Warm Up Cycle erkannt" ;
VAL_ 332 OBD_Normed_Trip 0 "kein Normed Trip" 1 "Normed Trip erfüllt" ;
VAL_ 332 OBD_Aussen_Temp_gef 254 "Init" 255 "Fehler" ;
VAL_ 246 TS_Faktor_Radmomente 0 "Faktor_1NM" 1 "Faktor_2NM" 2 "Faktor_3NM" 3 "Faktor_4NM" ;
VAL_ 246 TS_Status_MomRad_Ist 0 "FuSi_hohe_Genauigkeit" 1 "FuSi_niedrige_Genauigkeit" 2 "QM_fehlerfrei" 3 "QM_mit_Fehlern" ;
VAL_ 246 TS_MomRad_verfuegb_maxReku_Summe 4094 "Init" 4095 "Fehler" ;
VAL_ 246 TS_MomRad_Ist 8190 "Init" ;
VAL_ 246 TS_MomRad_Soll_Summe 8190 "Init" ;
VAL_ 246 TS_MomRad_Wunsch 8190 "Init" ;
VAL_ 246 TS_MomRad_Wunsch_sek 8190 "Init" 8191 "Fehler" ;
VAL_ 246 TS_MomRad_verfuegb_max 4094 "Init" ;
VAL_ 246 TS_MomRad_verfuegb_max_sek 4094 "Init" 4095 "Fehler" ;
VAL_ 246 TS_MomRad_verfuegb_maxReku 4094 "Init" ;
VAL_ 246 TS_MomRad_verfuegb_maxReku_sek 4094 "Init" 4095 "Fehler" ;
VAL_ 246 TS_MomRad_Ist_sek 8190 "Init" 8191 "Fehler" ;
VAL_ 246 TS_Allrad_Anteil_sek 510 "Init" 511 "Fehler" ;
VAL_ 246 FDR_Allrad_Anteil_max_sek 510 "Init" 511 "Fehler" ;
VAL_ 246 FDR_Allrad_Anteil_min_sek 510 "Init" 511 "Fehler" ;
VAL_ 246 FDR_MomRad_Eingriff 8190 "Init" 8191 "Fehler" ;
VAL_ 246 FDR_Status_Eingriff 0 "kein_Eingriff" 1 "Eingriff" ;
VAL_ 246 FDR_MomRad_Eingriff_sek 8190 "Init" 8191 "Fehler" ;
VAL_ 246 FDR_Status_Eingriff_sek 0 "kein_Eingriff" 1 "Eingriff" ;
VAL_ 190 MO_EM1_MinDrehzahl 16383 "Init" ;
VAL_ 190 MO_EM1_MaxDrehzahl 16383 "Init" ;
VAL_ 190 MO_EM1_DynLimit_AR 255 "Init" ;
VAL_ 190 MO_EM1_Periode_AR 255 "Init" ;
VAL_ 190 MO_EM1_SollMoment 4094 "Init" ;
VAL_ 190 MO_EM1_Sollmodus 0 "Standby" 1 "Momentenreg" 2 "Int_Drehzahlreg" 3 "Spannungsreg" 4 "Ext_Drehzahlreg" 6 "Kalibrierung" 7 "Sonderbremsbetrieb" 8 "Freilauf" 15 "Initialisierung" ;
VAL_ 190 MO_EM1_Min_Leistung 16382 "Init" ;
VAL_ 190 MO_EM1_Max_Leistung 16382 "Init" ;
VAL_ 190 MO_EM1_Min_Strom_Lim 8190 "Init" ;
VAL_ 190 MO_EM1_Max_Strom_Lim 8190 "Init" ;
VAL_ 190 MO_EM1_AR_Anf 0 "AR_aus" 2 "AR_D2T2" 3 "AR_RDR" 4 "AR_IRDR" ;
VAL_ 190 MO_EM1_Kp_AR 511 "Init" ;
VAL_ 190 MO_EM1_SollSpannung 4095 "Init" ;
VAL_ 190 MO_EM2_MinDrehzahl 16383 "Init" ;
VAL_ 190 MO_EM2_MaxDrehzahl 16383 "Init" ;
VAL_ 190 MO_EM2_DynLimit_AR 255 "Init" ;
VAL_ 190 MO_EM2_Periode_AR 255 "Init" ;
VAL_ 190 MO_EM2_SollMoment 4094 "Init" 4095 "Fehler" ;
VAL_ 190 MO_EM2_Sollmodus 0 "Standby" 1 "Momentenreg" 2 "Int_Drehzahlreg" 3 "Spannungsreg" 4 "Ext_Drehzahlreg" 6 "Kalibrierung" 7 "Sonderbremsbetrieb" 8 "Freilauf" 15 "Initialisierung" ;
VAL_ 190 MO_EM2_Min_Leistung 16382 "Init" ;
VAL_ 190 MO_EM2_Max_Leistung 16382 "Init" ;
VAL_ 190 MO_EM2_Min_Strom_Lim 8190 "Init" ;
VAL_ 190 MO_EM2_Max_Strom_Lim 8190 "Init" ;
VAL_ 190 MO_EM2_AR_Anf 0 "AR_aus" 2 "AR_D2T2" 3 "AR_RDR" 4 "AR_IRDR" ;
VAL_ 190 MO_EM2_SollSpannung 4095 "Init" ;
VAL_ 190 MO_DC_Max_Strom_HV 255 "Init" ;
VAL_ 190 MO_DC_SollSpannung_HV 255 "Init" ;
VAL_ 190 MO_EM1_Max_Moment 4094 "Init" ;
VAL_ 190 MO_EM1_Min_Moment 4094 "Init" ;
VAL_ 190 MO_EM2_Max_Moment 4094 "Init" 4095 "Fehler" ;
VAL_ 190 MO_EM2_Min_Moment 4094 "Init" 4095 "Fehler" ;
VAL_ 2463978666 MO_EM1_Min_Spannung_Lim 1022 "Init" ;
VAL_ 2463978666 MO_EM1_Max_Spannung_Lim 1022 "Init" ;
VAL_ 2463978666 MO_EM1_Min_Leistung_Gesamt 8190 "Init" ;
VAL_ 2463978666 MO_EM1_Max_Leistung_Gesamt 8190 "Init" ;
VAL_ 2463978666 MO_EM2_Min_Leistung_Gesamt 8190 "Init" ;
VAL_ 2463978666 MO_EM2_Max_Leistung_Gesamt 8190 "Init" ;
VAL_ 2463978666 MO_EM2_Min_Spannung_Lim 1022 "Init" ;
VAL_ 2463978666 MO_EM2_Max_Spannung_Lim 1022 "Init" ;
VAL_ 2463978666 MO_EM1_Generator_Leistung 254 "Init" 255 "Fehler" ;
VAL_ 2463978666 MO_Verbrauch_EM_Ges_Ueberlauf 0 "kein_Ueberlauf" 1 "Ueberlauf_Verbrauchssignal" ;
VAL_ 2463978666 MO_Rekuperation_EM_Ges_Ueberlauf 0 "kein_Ueberlauf" 1 "Ueberlauf_Reku_Leistungssignal" ;
VAL_ 2463978666 MO_Drehzahl_EM 8190 "Init_nichtverbaut" 8191 "Fehler" ;
VAL_ 2463978666 MO_Uebersetzung_EM 0 "keine_sichere_Uebertragung" 1022 "Init_nichtverbaut" 1023 "Fehler" ;
VAL_ 2463978666 MO_Drehzahl_EM_sek 8190 "Init_nichtverbaut" 8191 "Fehler" ;
VAL_ 2463978666 MO_Uebersetzung_EM_sek 0 "keine_sichere_Uebertragung" 1022 "Init" 1023 "Fehler" ;
